VERSION "dbc-export 1 2026.26.6.5"

NS_ :

BS_:

BU_: ADSP APSB BB CMP DAS DPB EPAS3P EPASTP EPASTS GTW IDB OCS1P PTC RCM RCU TCU TCU2 UDS UI UIS VCLEFT VCSEAT2L VCSEAT2R

BO_ 1297 RCM_alertLog: 8 RCM
 SG_ RCM_alertID M : 0|10@1+ (1,0) [0|1023] "" Vector__XXX
 SG_ RCM_a073_eventFactoryMode m73 : 12|1@1+ (1,0) [0|1] "" Vector__XXX
 SG_ RCM_a073_eventDiagEnabled m73 : 13|1@1+ (1,0) [0|1] "" Vector__XXX
 SG_ RCM_a073_eventDriveOrientation m73 : 14|1@1+ (1,0) [0|1] "" Vector__XXX
 SG_ RCM_a073_comChassisCANPH4MIA m73 : 16|1@1+ (1,0) [0|1] "" Vector__XXX
 SG_ RCM_a073_comChassisCANPH4ChkSm m73 : 17|1@1+ (1,0) [0|1] "" Vector__XXX
 SG_ RCM_a073_comChassisCANPH4Cntr m73 : 18|1@1+ (1,0) [0|1] "" Vector__XXX
 SG_ RCM_a073_eventIDFsignal m73 : 25|1@1+ (1,0) [0|1] "" Vector__XXX
 SG_ RCM_a073_eventFrontLeftSeatbelt m73 : 26|1@1+ (1,0) [0|1] "" Vector__XXX
 SG_ RCM_a073_eventFrontRightSeatbelt m73 : 27|1@1+ (1,0) [0|1] "" Vector__XXX
 SG_ RCM_a073_eventVehicleSpeed m73 : 28|12@1+ (0.08,-40) [-40|287.6] "kph" Vector__XXX
 SG_ RCM_a073_eventSteeringAngle m73 : 45|14@0+ (0.1,-819.2) [-819.2|819.1] "deg" Vector__XXX
 SG_ RCM_a073_eventDriverBrakeApply m73 : 46|2@1+ (1,0) [0|2] "" Vector__XXX
 SG_ RCM_a073_eventAccelPedalPos m73 : 56|8@1+ (0.4,0) [0|101.6] "%" Vector__XXX
 SG_ RCM_a074_eventArmStatus m74 : 11|1@1+ (1,0) [0|1] "" Vector__XXX
 SG_ RCM_a074_eventFactoryMode m74 : 12|1@1+ (1,0) [0|1] "" Vector__XXX
 SG_ RCM_a074_eventDiagEnabled m74 : 13|1@1+ (1,0) [0|1] "" Vector__XXX
 SG_ RCM_a074_eventDriveOrientation m74 : 14|1@1+ (1,0) [0|1] "" Vector__XXX
 SG_ RCM_a074_comChassisCANPH5MIA m74 : 16|1@1+ (1,0) [0|1] "" Vector__XXX
 SG_ RCM_a074_comChassisCANPH5ChkSm m74 : 17|1@1+ (1,0) [0|1] "" Vector__XXX
 SG_ RCM_a074_comChassisCANPH5Cntr m74 : 18|1@1+ (1,0) [0|1] "" Vector__XXX
 SG_ RCM_a074_eventIDFsignal m74 : 25|1@1+ (1,0) [0|1] "" Vector__XXX
 SG_ RCM_a074_eventFrontLeftSeatbelt m74 : 26|1@1+ (1,0) [0|1] "" Vector__XXX
 SG_ RCM_a074_eventFrontRightSeatbelt m74 : 27|1@1+ (1,0) [0|1] "" Vector__XXX
 SG_ RCM_a074_eventVehicleSpeed m74 : 28|12@1+ (0.08,-40) [-40|287.6] "kph" Vector__XXX
 SG_ RCM_a074_eventSteeringAngle m74 : 45|14@0+ (0.1,-819.2) [-819.2|819.1] "deg" Vector__XXX
 SG_ RCM_a074_eventDriverBrakeApply m74 : 46|2@1+ (1,0) [0|2] "" Vector__XXX
 SG_ RCM_a074_eventAccelPedalPos m74 : 56|8@1+ (0.4,0) [0|101.6] "%" Vector__XXX
 SG_ RCM_a075_eventArmStatus m75 : 11|1@1+ (1,0) [0|1] "" Vector__XXX
 SG_ RCM_a075_eventFactoryMode m75 : 12|1@1+ (1,0) [0|1] "" Vector__XXX
 SG_ RCM_a075_eventDiagEnabled m75 : 13|1@1+ (1,0) [0|1] "" Vector__XXX
 SG_ RCM_a075_eventDriveOrientation m75 : 14|1@1+ (1,0) [0|1] "" Vector__XXX
 SG_ RCM_a075_comChassisCANPH6MIA m75 : 16|1@1+ (1,0) [0|1] "" Vector__XXX
 SG_ RCM_a075_comChassisCANPH6ChkSm m75 : 17|1@1+ (1,0) [0|1] "" Vector__XXX
 SG_ RCM_a075_comChassisCANPH6Cntr m75 : 18|1@1+ (1,0) [0|1] "" Vector__XXX
 SG_ RCM_a075_eventIDFsignal m75 : 25|1@1+ (1,0) [0|1] "" Vector__XXX
 SG_ RCM_a075_eventFrontLeftSeatbelt m75 : 26|1@1+ (1,0) [0|1] "" Vector__XXX
 SG_ RCM_a075_eventFrontRightSeatbelt m75 : 27|1@1+ (1,0) [0|1] "" Vector__XXX
 SG_ RCM_a075_eventVehicleSpeed m75 : 28|12@1+ (0.08,-40) [-40|287.6] "kph" Vector__XXX
 SG_ RCM_a075_eventSteeringAngle m75 : 45|14@0+ (0.1,-819.2) [-819.2|819.1] "deg" Vector__XXX
 SG_ RCM_a075_eventDriverBrakeApply m75 : 46|2@1+ (1,0) [0|2] "" Vector__XXX
 SG_ RCM_a075_eventAccelPedalPos m75 : 56|8@1+ (0.4,0) [0|101.6] "%" Vector__XXX
 SG_ RCM_a078_eventArmStatus m78 : 11|1@1+ (1,0) [0|1] "" Vector__XXX
 SG_ RCM_a078_eventFactoryMode m78 : 12|1@1+ (1,0) [0|1] "" Vector__XXX
 SG_ RCM_a078_eventDiagEnabled m78 : 13|1@1+ (1,0) [0|1] "" Vector__XXX
 SG_ RCM_a078_eventDriveOrientation m78 : 14|1@1+ (1,0) [0|1] "" Vector__XXX
 SG_ RCM_a078_comOCS1PMIA m78 : 16|1@1+ (1,0) [0|1] "" Vector__XXX
 SG_ RCM_a078_comOCS1PChkSm m78 : 17|1@1+ (1,0) [0|1] "" Vector__XXX
 SG_ RCM_a078_comOCS1PCntr m78 : 18|1@1+ (1,0) [0|1] "" Vector__XXX
 SG_ RCM_a078_eventIDFsignal m78 : 25|1@1+ (1,0) [0|1] "" Vector__XXX
 SG_ RCM_a078_eventFrontLeftSeatbelt m78 : 26|1@1+ (1,0) [0|1] "" Vector__XXX
 SG_ RCM_a078_eventFrontRightSeatbelt m78 : 27|1@1+ (1,0) [0|1] "" Vector__XXX
 SG_ RCM_a078_eventVehicleSpeed m78 : 28|12@1+ (0.08,-40) [-40|287.6] "kph" Vector__XXX
 SG_ RCM_a078_eventSteeringAngle m78 : 45|14@0+ (0.1,-819.2) [-819.2|819.1] "deg" Vector__XXX
 SG_ RCM_a078_eventDriverBrakeApply m78 : 46|2@1+ (1,0) [0|2] "" Vector__XXX
 SG_ RCM_a078_eventAccelPedalPos m78 : 56|8@1+ (0.4,0) [0|101.6] "%" Vector__XXX
 SG_ RCM_a079_eventArmStatus m79 : 11|1@1+ (1,0) [0|1] "" Vector__XXX
 SG_ RCM_a079_eventFactoryMode m79 : 12|1@1+ (1,0) [0|1] "" Vector__XXX
 SG_ RCM_a079_eventDiagEnabled m79 : 13|1@1+ (1,0) [0|1] "" Vector__XXX
 SG_ RCM_a079_eventDriveOrientation m79 : 14|1@1+ (1,0) [0|1] "" Vector__XXX
 SG_ RCM_a079_comOCS1DMIA m79 : 16|1@1+ (1,0) [0|1] "" Vector__XXX
 SG_ RCM_a079_comOCS1DChkSm m79 : 17|1@1+ (1,0) [0|1] "" Vector__XXX
 SG_ RCM_a079_comOCS1DCntr m79 : 18|1@1+ (1,0) [0|1] "" Vector__XXX
 SG_ RCM_a079_eventIDFsignal m79 : 25|1@1+ (1,0) [0|1] "" Vector__XXX
 SG_ RCM_a079_eventFrontLeftSeatbelt m79 : 26|1@1+ (1,0) [0|1] "" Vector__XXX
 SG_ RCM_a079_eventFrontRightSeatbelt m79 : 27|1@1+ (1,0) [0|1] "" Vector__XXX
 SG_ RCM_a079_eventVehicleSpeed m79 : 28|12@1+ (0.08,-40) [-40|287.6] "kph" Vector__XXX
 SG_ RCM_a079_eventSteeringAngle m79 : 45|14@0+ (0.1,-819.2) [-819.2|819.1] "deg" Vector__XXX
 SG_ RCM_a079_eventDriverBrakeApply m79 : 46|2@1+ (1,0) [0|2] "" Vector__XXX
 SG_ RCM_a079_eventAccelPedalPos m79 : 56|8@1+ (0.4,0) [0|101.6] "%" Vector__XXX
 SG_ RCM_a080_eventArmStatus m80 : 11|1@1+ (1,0) [0|1] "" Vector__XXX
 SG_ RCM_a080_eventFactoryMode m80 : 12|1@1+ (1,0) [0|1] "" Vector__XXX
 SG_ RCM_a080_eventDiagEnabled m80 : 13|1@1+ (1,0) [0|1] "" Vector__XXX
 SG_ RCM_a080_eventDriveOrientation m80 : 14|1@1+ (1,0) [0|1] "" Vector__XXX
 SG_ RCM_a080_comGTWACSMIA m80 : 16|1@1+ (1,0) [0|1] "" Vector__XXX
 SG_ RCM_a080_comGTWACSChkSm m80 : 17|1@1+ (1,0) [0|1] "" Vector__XXX
 SG_ RCM_a080_comGTWACSCntr m80 : 18|1@1+ (1,0) [0|1] "" Vector__XXX
 SG_ RCM_a080_eventIDFsignal m80 : 25|1@1+ (1,0) [0|1] "" Vector__XXX
 SG_ RCM_a080_eventFrontLeftSeatbelt m80 : 26|1@1+ (1,0) [0|1] "" Vector__XXX
 SG_ RCM_a080_eventFrontRightSeatbelt m80 : 27|1@1+ (1,0) [0|1] "" Vector__XXX
 SG_ RCM_a080_eventVehicleSpeed m80 : 28|12@1+ (0.08,-40) [-40|287.6] "kph" Vector__XXX
 SG_ RCM_a080_eventSteeringAngle m80 : 45|14@0+ (0.1,-819.2) [-819.2|819.1] "deg" Vector__XXX
 SG_ RCM_a080_eventDriverBrakeApply m80 : 46|2@1+ (1,0) [0|2] "" Vector__XXX
 SG_ RCM_a080_eventAccelPedalPos m80 : 56|8@1+ (0.4,0) [0|101.6] "%" Vector__XXX
 SG_ RCM_a083_eventArmStatus m83 : 11|1@1+ (1,0) [0|1] "" Vector__XXX
 SG_ RCM_a083_eventFactoryMode m83 : 12|1@1+ (1,0) [0|1] "" Vector__XXX
 SG_ RCM_a083_eventDiagEnabled m83 : 13|1@1+ (1,0) [0|1] "" Vector__XXX
 SG_ RCM_a083_eventDriveOrientation m83 : 14|1@1+ (1,0) [0|1] "" Vector__XXX
 SG_ RCM_a083_comGTWCarStateMIA m83 : 16|1@1+ (1,0) [0|1] "" Vector__XXX
 SG_ RCM_a083_eventIDFsignal m83 : 25|1@1+ (1,0) [0|1] "" Vector__XXX
 SG_ RCM_a083_eventFrontLeftSeatbelt m83 : 26|1@1+ (1,0) [0|1] "" Vector__XXX
 SG_ RCM_a083_eventFrontRightSeatbelt m83 : 27|1@1+ (1,0) [0|1] "" Vector__XXX
 SG_ RCM_a083_eventVehicleSpeed m83 : 28|12@1+ (0.08,-40) [-40|287.6] "kph" Vector__XXX
 SG_ RCM_a083_eventSteeringAngle m83 : 45|14@0+ (0.1,-819.2) [-819.2|819.1] "deg" Vector__XXX
 SG_ RCM_a083_eventDriverBrakeApply m83 : 46|2@1+ (1,0) [0|2] "" Vector__XXX
 SG_ RCM_a083_eventAccelPedalPos m83 : 56|8@1+ (0.4,0) [0|101.6] "%" Vector__XXX
 SG_ RCM_a087_eventArmStatus m87 : 11|1@1+ (1,0) [0|1] "" Vector__XXX
 SG_ RCM_a087_eventFactoryMode m87 : 12|1@1+ (1,0) [0|1] "" Vector__XXX
 SG_ RCM_a087_eventDiagEnabled m87 : 13|1@1+ (1,0) [0|1] "" Vector__XXX
 SG_ RCM_a087_eventDriveOrientation m87 : 14|1@1+ (1,0) [0|1] "" Vector__XXX
 SG_ RCM_a087_comChassisCANSilent m87 : 16|1@1+ (1,0) [0|1] "" Vector__XXX
 SG_ RCM_a087_comPARTYCANSilent m87 : 17|1@1+ (1,0) [0|1] "" Vector__XXX
 SG_ RCM_a087_comUnusedCANSilent m87 : 18|1@1+ (1,0) [0|1] "" Vector__XXX
 SG_ RCM_a087_eventIDFsignal m87 : 25|1@1+ (1,0) [0|1] "" Vector__XXX
 SG_ RCM_a087_eventFrontLeftSeatbelt m87 : 26|1@1+ (1,0) [0|1] "" Vector__XXX
 SG_ RCM_a087_eventFrontRightSeatbelt m87 : 27|1@1+ (1,0) [0|1] "" Vector__XXX
 SG_ RCM_a087_eventVehicleSpeed m87 : 28|12@1+ (0.08,-40) [-40|287.6] "kph" Vector__XXX
 SG_ RCM_a087_eventSteeringAngle m87 : 45|14@0+ (0.1,-819.2) [-819.2|819.1] "deg" Vector__XXX
 SG_ RCM_a087_eventDriverBrakeApply m87 : 46|2@1+ (1,0) [0|2] "" Vector__XXX
 SG_ RCM_a087_eventAccelPedalPos m87 : 56|8@1+ (0.4,0) [0|101.6] "%" Vector__XXX
 SG_ RCM_a088_eventArmStatus m88 : 11|1@1+ (1,0) [0|1] "" Vector__XXX
 SG_ RCM_a088_eventFactoryMode m88 : 12|1@1+ (1,0) [0|1] "" Vector__XXX
 SG_ RCM_a088_eventDiagEnabled m88 : 13|1@1+ (1,0) [0|1] "" Vector__XXX
 SG_ RCM_a088_eventDriveOrientation m88 : 14|1@1+ (1,0) [0|1] "" Vector__XXX
 SG_ RCM_a088_comChassisCANPH2MIA m88 : 16|1@1+ (1,0) [0|1] "" Vector__XXX
 SG_ RCM_a088_comChassisCANPH2ChkSm m88 : 17|1@1+ (1,0) [0|1] "" Vector__XXX
 SG_ RCM_a088_comChassisCANPH2Cntr m88 : 18|1@1+ (1,0) [0|1] "" Vector__XXX
 SG_ RCM_a088_eventIDFsignal m88 : 25|1@1+ (1,0) [0|1] "" Vector__XXX
 SG_ RCM_a088_eventFrontLeftSeatbelt m88 : 26|1@1+ (1,0) [0|1] "" Vector__XXX
 SG_ RCM_a088_eventFrontRightSeatbelt m88 : 27|1@1+ (1,0) [0|1] "" Vector__XXX
 SG_ RCM_a088_eventVehicleSpeed m88 : 28|12@1+ (0.08,-40) [-40|287.6] "kph" Vector__XXX
 SG_ RCM_a088_eventSteeringAngle m88 : 45|14@0+ (0.1,-819.2) [-819.2|819.1] "deg" Vector__XXX
 SG_ RCM_a088_eventDriverBrakeApply m88 : 46|2@1+ (1,0) [0|2] "" Vector__XXX
 SG_ RCM_a088_eventAccelPedalPos m88 : 56|8@1+ (0.4,0) [0|101.6] "%" Vector__XXX
 SG_ RCM_a089_eventArmStatus m89 : 11|1@1+ (1,0) [0|1] "" Vector__XXX
 SG_ RCM_a089_eventFactoryMode m89 : 12|1@1+ (1,0) [0|1] "" Vector__XXX
 SG_ RCM_a089_eventDiagEnabled m89 : 13|1@1+ (1,0) [0|1] "" Vector__XXX
 SG_ RCM_a089_eventDriveOrientation m89 : 14|1@1+ (1,0) [0|1] "" Vector__XXX
 SG_ RCM_a089_comChassisCANPH3MIA m89 : 16|1@1+ (1,0) [0|1] "" Vector__XXX
 SG_ RCM_a089_comChassisCANPH3ChkSm m89 : 17|1@1+ (1,0) [0|1] "" Vector__XXX
 SG_ RCM_a089_comChassisCANPH3Cntr m89 : 18|1@1+ (1,0) [0|1] "" Vector__XXX
 SG_ RCM_a089_eventIDFsignal m89 : 25|1@1+ (1,0) [0|1] "" Vector__XXX
 SG_ RCM_a089_eventFrontLeftSeatbelt m89 : 26|1@1+ (1,0) [0|1] "" Vector__XXX
 SG_ RCM_a089_eventFrontRightSeatbelt m89 : 27|1@1+ (1,0) [0|1] "" Vector__XXX
 SG_ RCM_a089_eventVehicleSpeed m89 : 28|12@1+ (0.08,-40) [-40|287.6] "kph" Vector__XXX
 SG_ RCM_a089_eventSteeringAngle m89 : 45|14@0+ (0.1,-819.2) [-819.2|819.1] "deg" Vector__XXX
 SG_ RCM_a089_eventDriverBrakeApply m89 : 46|2@1+ (1,0) [0|2] "" Vector__XXX
 SG_ RCM_a089_eventAccelPedalPos m89 : 56|8@1+ (0.4,0) [0|101.6] "%" Vector__XXX
 SG_ RCM_a090_eventArmStatus m90 : 11|1@1+ (1,0) [0|1] "" Vector__XXX
 SG_ RCM_a090_eventFactoryMode m90 : 12|1@1+ (1,0) [0|1] "" Vector__XXX
 SG_ RCM_a090_eventDiagEnabled m90 : 13|1@1+ (1,0) [0|1] "" Vector__XXX
 SG_ RCM_a090_eventDriveOrientation m90 : 14|1@1+ (1,0) [0|1] "" Vector__XXX
 SG_ RCM_a090_comPartyCANBusOff m90 : 16|1@1+ (1,0) [0|1] "" Vector__XXX
 SG_ RCM_a090_eventIDFsignal m90 : 25|1@1+ (1,0) [0|1] "" Vector__XXX
 SG_ RCM_a090_eventFrontLeftSeatbelt m90 : 26|1@1+ (1,0) [0|1] "" Vector__XXX
 SG_ RCM_a090_eventFrontRightSeatbelt m90 : 27|1@1+ (1,0) [0|1] "" Vector__XXX
 SG_ RCM_a090_eventVehicleSpeed m90 : 28|12@1+ (0.08,-40) [-40|287.6] "kph" Vector__XXX
 SG_ RCM_a090_eventSteeringAngle m90 : 45|14@0+ (0.1,-819.2) [-819.2|819.1] "deg" Vector__XXX
 SG_ RCM_a090_eventDriverBrakeApply m90 : 46|2@1+ (1,0) [0|2] "" Vector__XXX
 SG_ RCM_a090_eventAccelPedalPos m90 : 56|8@1+ (0.4,0) [0|101.6] "%" Vector__XXX
 SG_ RCM_a092_eventArmStatus m92 : 11|1@1+ (1,0) [0|1] "" Vector__XXX
 SG_ RCM_a092_eventFactoryMode m92 : 12|1@1+ (1,0) [0|1] "" Vector__XXX
 SG_ RCM_a092_eventDiagEnabled m92 : 13|1@1+ (1,0) [0|1] "" Vector__XXX
 SG_ RCM_a092_eventDriveOrientation m92 : 14|1@1+ (1,0) [0|1] "" Vector__XXX
 SG_ RCM_a092_comDASSafetyFrontMIA m92 : 16|1@1+ (1,0) [0|1] "" Vector__XXX
 SG_ RCM_a092_comDASSafetyFrontChkSm m92 : 17|1@1+ (1,0) [0|1] "" Vector__XXX
 SG_ RCM_a092_comDASSafetyFrontCntr m92 : 18|1@1+ (1,0) [0|1] "" Vector__XXX
 SG_ RCM_a092_eventIDFsignal m92 : 25|1@1+ (1,0) [0|1] "" Vector__XXX
 SG_ RCM_a092_eventFrontLeftSeatbelt m92 : 26|1@1+ (1,0) [0|1] "" Vector__XXX
 SG_ RCM_a092_eventFrontRightSeatbelt m92 : 27|1@1+ (1,0) [0|1] "" Vector__XXX
 SG_ RCM_a092_eventVehicleSpeed m92 : 28|12@1+ (0.08,-40) [-40|287.6] "kph" Vector__XXX
 SG_ RCM_a092_eventSteeringAngle m92 : 45|14@0+ (0.1,-819.2) [-819.2|819.1] "deg" Vector__XXX
 SG_ RCM_a092_eventDriverBrakeApply m92 : 46|2@1+ (1,0) [0|2] "" Vector__XXX
 SG_ RCM_a092_eventAccelPedalPos m92 : 56|8@1+ (0.4,0) [0|101.6] "%" Vector__XXX
 SG_ RCM_a093_eventArmStatus m93 : 11|1@1+ (1,0) [0|1] "" Vector__XXX
 SG_ RCM_a093_eventFactoryMode m93 : 12|1@1+ (1,0) [0|1] "" Vector__XXX
 SG_ RCM_a093_eventDiagEnabled m93 : 13|1@1+ (1,0) [0|1] "" Vector__XXX
 SG_ RCM_a093_eventDriveOrientation m93 : 14|1@1+ (1,0) [0|1] "" Vector__XXX
 SG_ RCM_a093_comVCLEFTStatusMIA m93 : 16|1@1+ (1,0) [0|1] "" Vector__XXX
 SG_ RCM_a093_comVCLEFTStatusChkSm m93 : 17|1@1+ (1,0) [0|1] "" Vector__XXX
 SG_ RCM_a093_comVCLEFTStatusCntr m93 : 18|1@1+ (1,0) [0|1] "" Vector__XXX
 SG_ RCM_a093_bucklSwVCFrontLeftFault m93 : 19|1@1+ (1,0) [0|1] "" Vector__XXX
 SG_ RCM_a093_bucklSwVCRearLeftFault m93 : 20|1@1+ (1,0) [0|1] "" Vector__XXX
 SG_ RCM_a093_eventIDFsignal m93 : 25|1@1+ (1,0) [0|1] "" Vector__XXX
 SG_ RCM_a093_eventFrontLeftSeatbelt m93 : 26|1@1+ (1,0) [0|1] "" Vector__XXX
 SG_ RCM_a093_eventFrontRightSeatbelt m93 : 27|1@1+ (1,0) [0|1] "" Vector__XXX
 SG_ RCM_a093_eventVehicleSpeed m93 : 28|12@1+ (0.08,-40) [-40|287.6] "kph" Vector__XXX
 SG_ RCM_a093_eventSteeringAngle m93 : 45|14@0+ (0.1,-819.2) [-819.2|819.1] "deg" Vector__XXX
 SG_ RCM_a093_eventDriverBrakeApply m93 : 46|2@1+ (1,0) [0|2] "" Vector__XXX
 SG_ RCM_a093_eventAccelPedalPos m93 : 56|8@1+ (0.4,0) [0|101.6] "%" Vector__XXX
 SG_ RCM_a094_eventArmStatus m94 : 11|1@1+ (1,0) [0|1] "" Vector__XXX
 SG_ RCM_a094_eventFactoryMode m94 : 12|1@1+ (1,0) [0|1] "" Vector__XXX
 SG_ RCM_a094_eventDiagEnabled m94 : 13|1@1+ (1,0) [0|1] "" Vector__XXX
 SG_ RCM_a094_eventDriveOrientation m94 : 14|1@1+ (1,0) [0|1] "" Vector__XXX
 SG_ RCM_a094_comVCRIGHTStatusMIA m94 : 16|1@1+ (1,0) [0|1] "" Vector__XXX
 SG_ RCM_a094_comVCRIGHTStatusChkSm m94 : 17|1@1+ (1,0) [0|1] "" Vector__XXX
 SG_ RCM_a094_comVCRIGHTStatusCntr m94 : 18|1@1+ (1,0) [0|1] "" Vector__XXX
 SG_ RCM_a094_bucklSwVCFrontRghtFault m94 : 19|1@1+ (1,0) [0|1] "" Vector__XXX
 SG_ RCM_a094_bucklSwVCRearRghtFault m94 : 20|1@1+ (1,0) [0|1] "" Vector__XXX
 SG_ RCM_a094_bucklSwVCRearCnterFault m94 : 21|1@1+ (1,0) [0|1] "" Vector__XXX
 SG_ RCM_a094_eventIDFsignal m94 : 25|1@1+ (1,0) [0|1] "" Vector__XXX
 SG_ RCM_a094_eventFrontLeftSeatbelt m94 : 26|1@1+ (1,0) [0|1] "" Vector__XXX
 SG_ RCM_a094_eventFrontRightSeatbelt m94 : 27|1@1+ (1,0) [0|1] "" Vector__XXX
 SG_ RCM_a094_eventVehicleSpeed m94 : 28|12@1+ (0.08,-40) [-40|287.6] "kph" Vector__XXX
 SG_ RCM_a094_eventSteeringAngle m94 : 45|14@0+ (0.1,-819.2) [-819.2|819.1] "deg" Vector__XXX
 SG_ RCM_a094_eventDriverBrakeApply m94 : 46|2@1+ (1,0) [0|2] "" Vector__XXX
 SG_ RCM_a094_eventAccelPedalPos m94 : 56|8@1+ (0.4,0) [0|101.6] "%" Vector__XXX
 SG_ RCM_a101_eventArmStatus m101 : 11|1@1+ (1,0) [0|1] "" Vector__XXX
 SG_ RCM_a101_eventFactoryMode m101 : 12|1@1+ (1,0) [0|1] "" Vector__XXX
 SG_ RCM_a101_eventDiagEnabled m101 : 13|1@1+ (1,0) [0|1] "" Vector__XXX
 SG_ RCM_a101_eventDriveOrientation m101 : 14|1@1+ (1,0) [0|1] "" Vector__XXX
 SG_ RCM_a101_idfMisuseMonitoringErr m101 : 16|1@1+ (1,0) [0|1] "" Vector__XXX
 SG_ RCM_a101_idfEnviMonitoringError m101 : 17|1@1+ (1,0) [0|1] "" Vector__XXX
 SG_ RCM_a101_idfEnviMonitoringEvent m101 : 18|1@1+ (1,0) [0|1] "" Vector__XXX
 SG_ RCM_a101_eventIDFsignal m101 : 25|1@1+ (1,0) [0|1] "" Vector__XXX
 SG_ RCM_a101_eventFrontLeftSeatbelt m101 : 26|1@1+ (1,0) [0|1] "" Vector__XXX
 SG_ RCM_a101_eventFrontRightSeatbelt m101 : 27|1@1+ (1,0) [0|1] "" Vector__XXX
 SG_ RCM_a101_eventVehicleSpeed m101 : 28|12@1+ (0.08,-40) [-40|287.6] "kph" Vector__XXX
 SG_ RCM_a101_eventSteeringAngle m101 : 45|14@0+ (0.1,-819.2) [-819.2|819.1] "deg" Vector__XXX
 SG_ RCM_a101_eventDriverBrakeApply m101 : 46|2@1+ (1,0) [0|2] "" Vector__XXX
 SG_ RCM_a101_eventAccelPedalPos m101 : 56|8@1+ (0.4,0) [0|101.6] "%" Vector__XXX
 SG_ RCM_a102_eventArmStatus m102 : 11|1@1+ (1,0) [0|1] "" Vector__XXX
 SG_ RCM_a102_eventFactoryMode m102 : 12|1@1+ (1,0) [0|1] "" Vector__XXX
 SG_ RCM_a102_eventDiagEnabled m102 : 13|1@1+ (1,0) [0|1] "" Vector__XXX
 SG_ RCM_a102_eventDriveOrientation m102 : 14|1@1+ (1,0) [0|1] "" Vector__XXX
 SG_ RCM_a102_imuYawR8OffCompPosLife m102 : 16|1@1+ (1,0) [0|1] "" Vector__XXX
 SG_ RCM_a102_imuYawR8OffCompNegLife m102 : 17|1@1+ (1,0) [0|1] "" Vector__XXX
 SG_ RCM_a102_imuYawR8OffCompPosFLDC m102 : 18|1@1+ (1,0) [0|1] "" Vector__XXX
 SG_ RCM_a102_imuYawR8OffCompNegFLDC m102 : 19|1@1+ (1,0) [0|1] "" Vector__XXX
 SG_ RCM_a102_imuYawR8OffCompPosSLDC m102 : 20|1@1+ (1,0) [0|1] "" Vector__XXX
 SG_ RCM_a102_imuYawR8OffCompNegSLDC m102 : 21|1@1+ (1,0) [0|1] "" Vector__XXX
 SG_ RCM_a102_eventIDFsignal m102 : 25|1@1+ (1,0) [0|1] "" Vector__XXX
 SG_ RCM_a102_eventFrontLeftSeatbelt m102 : 26|1@1+ (1,0) [0|1] "" Vector__XXX
 SG_ RCM_a102_eventFrontRightSeatbelt m102 : 27|1@1+ (1,0) [0|1] "" Vector__XXX
 SG_ RCM_a102_eventVehicleSpeed m102 : 28|12@1+ (0.08,-40) [-40|287.6] "kph" Vector__XXX
 SG_ RCM_a102_eventSteeringAngle m102 : 45|14@0+ (0.1,-819.2) [-819.2|819.1] "deg" Vector__XXX
 SG_ RCM_a102_eventDriverBrakeApply m102 : 46|2@1+ (1,0) [0|2] "" Vector__XXX
 SG_ RCM_a102_eventAccelPedalPos m102 : 56|8@1+ (0.4,0) [0|101.6] "%" Vector__XXX
 SG_ RCM_a103_eventArmStatus m103 : 11|1@1+ (1,0) [0|1] "" Vector__XXX
 SG_ RCM_a103_eventFactoryMode m103 : 12|1@1+ (1,0) [0|1] "" Vector__XXX
 SG_ RCM_a103_eventDiagEnabled m103 : 13|1@1+ (1,0) [0|1] "" Vector__XXX
 SG_ RCM_a103_eventDriveOrientation m103 : 14|1@1+ (1,0) [0|1] "" Vector__XXX
 SG_ RCM_a103_imuPtchR8OffCompPosLife m103 : 16|1@1+ (1,0) [0|1] "" Vector__XXX
 SG_ RCM_a103_imuPtchR8OffCompNegLife m103 : 17|1@1+ (1,0) [0|1] "" Vector__XXX
 SG_ RCM_a103_imuPtchR8OffCompPosFLDC m103 : 18|1@1+ (1,0) [0|1] "" Vector__XXX
 SG_ RCM_a103_imuPtchR8OffCompNegFLDC m103 : 19|1@1+ (1,0) [0|1] "" Vector__XXX
 SG_ RCM_a103_imuPtchR8OffCompPosSLDC m103 : 20|1@1+ (1,0) [0|1] "" Vector__XXX
 SG_ RCM_a103_imuPtchR8OffCompNegSLDC m103 : 21|1@1+ (1,0) [0|1] "" Vector__XXX
 SG_ RCM_a103_eventIDFsignal m103 : 25|1@1+ (1,0) [0|1] "" Vector__XXX
 SG_ RCM_a103_eventFrontLeftSeatbelt m103 : 26|1@1+ (1,0) [0|1] "" Vector__XXX
 SG_ RCM_a103_eventFrontRightSeatbelt m103 : 27|1@1+ (1,0) [0|1] "" Vector__XXX
 SG_ RCM_a103_eventVehicleSpeed m103 : 28|12@1+ (0.08,-40) [-40|287.6] "kph" Vector__XXX
 SG_ RCM_a103_eventSteeringAngle m103 : 45|14@0+ (0.1,-819.2) [-819.2|819.1] "deg" Vector__XXX
 SG_ RCM_a103_eventDriverBrakeApply m103 : 46|2@1+ (1,0) [0|2] "" Vector__XXX
 SG_ RCM_a103_eventAccelPedalPos m103 : 56|8@1+ (0.4,0) [0|101.6] "%" Vector__XXX
 SG_ RCM_a104_eventArmStatus m104 : 11|1@1+ (1,0) [0|1] "" Vector__XXX
 SG_ RCM_a104_eventFactoryMode m104 : 12|1@1+ (1,0) [0|1] "" Vector__XXX
 SG_ RCM_a104_eventDiagEnabled m104 : 13|1@1+ (1,0) [0|1] "" Vector__XXX
 SG_ RCM_a104_eventDriveOrientation m104 : 14|1@1+ (1,0) [0|1] "" Vector__XXX
 SG_ RCM_a104_imuRollR8OffCompPosLife m104 : 16|1@1+ (1,0) [0|1] "" Vector__XXX
 SG_ RCM_a104_imuRollR8OffCompNegLife m104 : 17|1@1+ (1,0) [0|1] "" Vector__XXX
 SG_ RCM_a104_imuRollR8OffCompPosFLDC m104 : 18|1@1+ (1,0) [0|1] "" Vector__XXX
 SG_ RCM_a104_imuRollR8OffCompNegFLDC m104 : 19|1@1+ (1,0) [0|1] "" Vector__XXX
 SG_ RCM_a104_imuRollR8OffCompPosSLDC m104 : 20|1@1+ (1,0) [0|1] "" Vector__XXX
 SG_ RCM_a104_imuRollR8OffCompNegSLDC m104 : 21|1@1+ (1,0) [0|1] "" Vector__XXX
 SG_ RCM_a104_eventIDFsignal m104 : 25|1@1+ (1,0) [0|1] "" Vector__XXX
 SG_ RCM_a104_eventFrontLeftSeatbelt m104 : 26|1@1+ (1,0) [0|1] "" Vector__XXX
 SG_ RCM_a104_eventFrontRightSeatbelt m104 : 27|1@1+ (1,0) [0|1] "" Vector__XXX
 SG_ RCM_a104_eventVehicleSpeed m104 : 28|12@1+ (0.08,-40) [-40|287.6] "kph" Vector__XXX
 SG_ RCM_a104_eventSteeringAngle m104 : 45|14@0+ (0.1,-819.2) [-819.2|819.1] "deg" Vector__XXX
 SG_ RCM_a104_eventDriverBrakeApply m104 : 46|2@1+ (1,0) [0|2] "" Vector__XXX
 SG_ RCM_a104_eventAccelPedalPos m104 : 56|8@1+ (0.4,0) [0|101.6] "%" Vector__XXX
 SG_ RCM_a105_eventArmStatus m105 : 11|1@1+ (1,0) [0|1] "" Vector__XXX
 SG_ RCM_a105_eventFactoryMode m105 : 12|1@1+ (1,0) [0|1] "" Vector__XXX
 SG_ RCM_a105_eventDiagEnabled m105 : 13|1@1+ (1,0) [0|1] "" Vector__XXX
 SG_ RCM_a105_eventDriveOrientation m105 : 14|1@1+ (1,0) [0|1] "" Vector__XXX
 SG_ RCM_a105_imuLongAOffCompPosLife m105 : 16|1@1+ (1,0) [0|1] "" Vector__XXX
 SG_ RCM_a105_imuLongAOffCompNegLife m105 : 17|1@1+ (1,0) [0|1] "" Vector__XXX
 SG_ RCM_a105_imuLongAOffCompPosFLDC m105 : 18|1@1+ (1,0) [0|1] "" Vector__XXX
 SG_ RCM_a105_imuLongAOffCompNegFLDC m105 : 19|1@1+ (1,0) [0|1] "" Vector__XXX
 SG_ RCM_a105_imuLongAOffCompPosSLDC m105 : 20|1@1+ (1,0) [0|1] "" Vector__XXX
 SG_ RCM_a105_imuLongAOffCompNegSLDC m105 : 21|1@1+ (1,0) [0|1] "" Vector__XXX
 SG_ RCM_a105_eventIDFsignal m105 : 25|1@1+ (1,0) [0|1] "" Vector__XXX
 SG_ RCM_a105_eventFrontLeftSeatbelt m105 : 26|1@1+ (1,0) [0|1] "" Vector__XXX
 SG_ RCM_a105_eventFrontRightSeatbelt m105 : 27|1@1+ (1,0) [0|1] "" Vector__XXX
 SG_ RCM_a105_eventVehicleSpeed m105 : 28|12@1+ (0.08,-40) [-40|287.6] "kph" Vector__XXX
 SG_ RCM_a105_eventSteeringAngle m105 : 45|14@0+ (0.1,-819.2) [-819.2|819.1] "deg" Vector__XXX
 SG_ RCM_a105_eventDriverBrakeApply m105 : 46|2@1+ (1,0) [0|2] "" Vector__XXX
 SG_ RCM_a105_eventAccelPedalPos m105 : 56|8@1+ (0.4,0) [0|101.6] "%" Vector__XXX
 SG_ RCM_a106_eventArmStatus m106 : 11|1@1+ (1,0) [0|1] "" Vector__XXX
 SG_ RCM_a106_eventFactoryMode m106 : 12|1@1+ (1,0) [0|1] "" Vector__XXX
 SG_ RCM_a106_eventDiagEnabled m106 : 13|1@1+ (1,0) [0|1] "" Vector__XXX
 SG_ RCM_a106_eventDriveOrientation m106 : 14|1@1+ (1,0) [0|1] "" Vector__XXX
 SG_ RCM_a106_imuLatAcOffCompPosLife m106 : 16|1@1+ (1,0) [0|1] "" Vector__XXX
 SG_ RCM_a106_imuLatAcOffCompNegLife m106 : 17|1@1+ (1,0) [0|1] "" Vector__XXX
 SG_ RCM_a106_imuLatAcOffCompPosFLDC m106 : 18|1@1+ (1,0) [0|1] "" Vector__XXX
 SG_ RCM_a106_imuLatAcOffCompNegFLDC m106 : 19|1@1+ (1,0) [0|1] "" Vector__XXX
 SG_ RCM_a106_imuLatAcOffCompPosSLDC m106 : 20|1@1+ (1,0) [0|1] "" Vector__XXX
 SG_ RCM_a106_imuLatAcOffCompNegSLDC m106 : 21|1@1+ (1,0) [0|1] "" Vector__XXX
 SG_ RCM_a106_eventIDFsignal m106 : 25|1@1+ (1,0) [0|1] "" Vector__XXX
 SG_ RCM_a106_eventFrontLeftSeatbelt m106 : 26|1@1+ (1,0) [0|1] "" Vector__XXX
 SG_ RCM_a106_eventFrontRightSeatbelt m106 : 27|1@1+ (1,0) [0|1] "" Vector__XXX
 SG_ RCM_a106_eventVehicleSpeed m106 : 28|12@1+ (0.08,-40) [-40|287.6] "kph" Vector__XXX
 SG_ RCM_a106_eventSteeringAngle m106 : 45|14@0+ (0.1,-819.2) [-819.2|819.1] "deg" Vector__XXX
 SG_ RCM_a106_eventDriverBrakeApply m106 : 46|2@1+ (1,0) [0|2] "" Vector__XXX
 SG_ RCM_a106_eventAccelPedalPos m106 : 56|8@1+ (0.4,0) [0|101.6] "%" Vector__XXX
 SG_ RCM_a107_eventArmStatus m107 : 11|1@1+ (1,0) [0|1] "" Vector__XXX
 SG_ RCM_a107_eventFactoryMode m107 : 12|1@1+ (1,0) [0|1] "" Vector__XXX
 SG_ RCM_a107_eventDiagEnabled m107 : 13|1@1+ (1,0) [0|1] "" Vector__XXX
 SG_ RCM_a107_eventDriveOrientation m107 : 14|1@1+ (1,0) [0|1] "" Vector__XXX
 SG_ RCM_a107_imuVertAOffCompPosLife m107 : 16|1@1+ (1,0) [0|1] "" Vector__XXX
 SG_ RCM_a107_imuVertAOffCompNegLife m107 : 17|1@1+ (1,0) [0|1] "" Vector__XXX
 SG_ RCM_a107_imuVertAOffCompPosFLDC m107 : 18|1@1+ (1,0) [0|1] "" Vector__XXX
 SG_ RCM_a107_imuVertAOffCompNegFLDC m107 : 19|1@1+ (1,0) [0|1] "" Vector__XXX
 SG_ RCM_a107_imuVertAOffCompPosSLDC m107 : 20|1@1+ (1,0) [0|1] "" Vector__XXX
 SG_ RCM_a107_imuVertAOffCompNegSLDC m107 : 21|1@1+ (1,0) [0|1] "" Vector__XXX
 SG_ RCM_a107_eventIDFsignal m107 : 25|1@1+ (1,0) [0|1] "" Vector__XXX
 SG_ RCM_a107_eventFrontLeftSeatbelt m107 : 26|1@1+ (1,0) [0|1] "" Vector__XXX
 SG_ RCM_a107_eventFrontRightSeatbelt m107 : 27|1@1+ (1,0) [0|1] "" Vector__XXX
 SG_ RCM_a107_eventVehicleSpeed m107 : 28|12@1+ (0.08,-40) [-40|287.6] "kph" Vector__XXX
 SG_ RCM_a107_eventSteeringAngle m107 : 45|14@0+ (0.1,-819.2) [-819.2|819.1] "deg" Vector__XXX
 SG_ RCM_a107_eventDriverBrakeApply m107 : 46|2@1+ (1,0) [0|2] "" Vector__XXX
 SG_ RCM_a107_eventAccelPedalPos m107 : 56|8@1+ (0.4,0) [0|101.6] "%" Vector__XXX
 SG_ RCM_a108_eventArmStatus m108 : 11|1@1+ (1,0) [0|1] "" Vector__XXX
 SG_ RCM_a108_eventFactoryMode m108 : 12|1@1+ (1,0) [0|1] "" Vector__XXX
 SG_ RCM_a108_eventDiagEnabled m108 : 13|1@1+ (1,0) [0|1] "" Vector__XXX
 SG_ RCM_a108_eventDriveOrientation m108 : 14|1@1+ (1,0) [0|1] "" Vector__XXX
 SG_ RCM_a108_crashAlgoWakeupSig m108 : 16|1@1+ (1,0) [0|1] "" Vector__XXX
 SG_ RCM_a108_eventIDFsignal m108 : 25|1@1+ (1,0) [0|1] "" Vector__XXX
 SG_ RCM_a108_eventFrontLeftSeatbelt m108 : 26|1@1+ (1,0) [0|1] "" Vector__XXX
 SG_ RCM_a108_eventFrontRightSeatbelt m108 : 27|1@1+ (1,0) [0|1] "" Vector__XXX
 SG_ RCM_a108_eventVehicleSpeed m108 : 28|12@1+ (0.08,-40) [-40|287.6] "kph" Vector__XXX
 SG_ RCM_a108_eventSteeringAngle m108 : 45|14@0+ (0.1,-819.2) [-819.2|819.1] "deg" Vector__XXX
 SG_ RCM_a108_eventDriverBrakeApply m108 : 46|2@1+ (1,0) [0|2] "" Vector__XXX
 SG_ RCM_a108_eventAccelPedalPos m108 : 56|8@1+ (0.4,0) [0|101.6] "%" Vector__XXX
 SG_ RCM_a109_eventArmStatus m109 : 11|1@1+ (1,0) [0|1] "" Vector__XXX
 SG_ RCM_a109_eventFactoryMode m109 : 12|1@1+ (1,0) [0|1] "" Vector__XXX
 SG_ RCM_a109_eventDiagEnabled m109 : 13|1@1+ (1,0) [0|1] "" Vector__XXX
 SG_ RCM_a109_eventDriveOrientation m109 : 14|1@1+ (1,0) [0|1] "" Vector__XXX
 SG_ RCM_a109_immunityThrsholdCrossed m109 : 16|1@1+ (1,0) [0|1] "" Vector__XXX
 SG_ RCM_a109_eventIDFsignal m109 : 25|1@1+ (1,0) [0|1] "" Vector__XXX
 SG_ RCM_a109_eventFrontLeftSeatbelt m109 : 26|1@1+ (1,0) [0|1] "" Vector__XXX
 SG_ RCM_a109_eventFrontRightSeatbelt m109 : 27|1@1+ (1,0) [0|1] "" Vector__XXX
 SG_ RCM_a109_eventVehicleSpeed m109 : 28|12@1+ (0.08,-40) [-40|287.6] "kph" Vector__XXX
 SG_ RCM_a109_eventSteeringAngle m109 : 45|14@0+ (0.1,-819.2) [-819.2|819.1] "deg" Vector__XXX
 SG_ RCM_a109_eventDriverBrakeApply m109 : 46|2@1+ (1,0) [0|2] "" Vector__XXX
 SG_ RCM_a109_eventAccelPedalPos m109 : 56|8@1+ (0.4,0) [0|101.6] "%" Vector__XXX
 SG_ RCM_a110_eventArmStatus m110 : 11|1@1+ (1,0) [0|1] "" Vector__XXX
 SG_ RCM_a110_eventFactoryMode m110 : 12|1@1+ (1,0) [0|1] "" Vector__XXX
 SG_ RCM_a110_eventDiagEnabled m110 : 13|1@1+ (1,0) [0|1] "" Vector__XXX
 SG_ RCM_a110_eventDriveOrientation m110 : 14|1@1+ (1,0) [0|1] "" Vector__XXX
 SG_ RCM_a110_inFactoryMode m110 : 16|1@1+ (1,0) [0|1] "" Vector__XXX
 SG_ RCM_a110_eventIDFsignal m110 : 25|1@1+ (1,0) [0|1] "" Vector__XXX
 SG_ RCM_a110_eventFrontLeftSeatbelt m110 : 26|1@1+ (1,0) [0|1] "" Vector__XXX
 SG_ RCM_a110_eventFrontRightSeatbelt m110 : 27|1@1+ (1,0) [0|1] "" Vector__XXX
 SG_ RCM_a110_eventVehicleSpeed m110 : 28|12@1+ (0.08,-40) [-40|287.6] "kph" Vector__XXX
 SG_ RCM_a110_eventSteeringAngle m110 : 45|14@0+ (0.1,-819.2) [-819.2|819.1] "deg" Vector__XXX
 SG_ RCM_a110_eventDriverBrakeApply m110 : 46|2@1+ (1,0) [0|2] "" Vector__XXX
 SG_ RCM_a110_eventAccelPedalPos m110 : 56|8@1+ (0.4,0) [0|101.6] "%" Vector__XXX
 SG_ RCM_a112_eventArmStatus m112 : 11|1@1+ (1,0) [0|1] "" Vector__XXX
 SG_ RCM_a112_eventFactoryMode m112 : 12|1@1+ (1,0) [0|1] "" Vector__XXX
 SG_ RCM_a112_eventDiagEnabled m112 : 13|1@1+ (1,0) [0|1] "" Vector__XXX
 SG_ RCM_a112_eventDriveOrientation m112 : 14|1@1+ (1,0) [0|1] "" Vector__XXX
 SG_ RCM_a112_imuYawR8SnsrMonitTmp m112 : 16|1@1+ (1,0) [0|1] "" Vector__XXX
 SG_ RCM_a112_imuYawR8SnsrMonitPerm m112 : 17|1@1+ (1,0) [0|1] "" Vector__XXX
 SG_ RCM_a112_imuYawR8ChnlMonitTmp m112 : 19|1@1+ (1,0) [0|1] "" Vector__XXX
 SG_ RCM_a112_imuYawR8ChnlMonitPerm m112 : 20|1@1+ (1,0) [0|1] "" Vector__XXX
 SG_ RCM_a112_eventIDFsignal m112 : 25|1@1+ (1,0) [0|1] "" Vector__XXX
 SG_ RCM_a112_eventFrontLeftSeatbelt m112 : 26|1@1+ (1,0) [0|1] "" Vector__XXX
 SG_ RCM_a112_eventFrontRightSeatbelt m112 : 27|1@1+ (1,0) [0|1] "" Vector__XXX
 SG_ RCM_a112_eventVehicleSpeed m112 : 28|12@1+ (0.08,-40) [-40|287.6] "kph" Vector__XXX
 SG_ RCM_a112_eventSteeringAngle m112 : 45|14@0+ (0.1,-819.2) [-819.2|819.1] "deg" Vector__XXX
 SG_ RCM_a112_eventDriverBrakeApply m112 : 46|2@1+ (1,0) [0|2] "" Vector__XXX
 SG_ RCM_a112_eventAccelPedalPos m112 : 56|8@1+ (0.4,0) [0|101.6] "%" Vector__XXX
 SG_ RCM_a113_eventArmStatus m113 : 11|1@1+ (1,0) [0|1] "" Vector__XXX
 SG_ RCM_a113_eventFactoryMode m113 : 12|1@1+ (1,0) [0|1] "" Vector__XXX
 SG_ RCM_a113_eventDiagEnabled m113 : 13|1@1+ (1,0) [0|1] "" Vector__XXX
 SG_ RCM_a113_eventDriveOrientation m113 : 14|1@1+ (1,0) [0|1] "" Vector__XXX
 SG_ RCM_a113_imuPitchR8SnsrMonitTmp m113 : 16|1@1+ (1,0) [0|1] "" Vector__XXX
 SG_ RCM_a113_imuPitchR8SnsrMonitPerm m113 : 17|1@1+ (1,0) [0|1] "" Vector__XXX
 SG_ RCM_a113_imuPitchR8ChnlMonitTmp m113 : 18|1@1+ (1,0) [0|1] "" Vector__XXX
 SG_ RCM_a113_imuPitchR8ChnlMonitPerm m113 : 19|1@1+ (1,0) [0|1] "" Vector__XXX
 SG_ RCM_a113_eventIDFsignal m113 : 25|1@1+ (1,0) [0|1] "" Vector__XXX
 SG_ RCM_a113_eventFrontLeftSeatbelt m113 : 26|1@1+ (1,0) [0|1] "" Vector__XXX
 SG_ RCM_a113_eventFrontRightSeatbelt m113 : 27|1@1+ (1,0) [0|1] "" Vector__XXX
 SG_ RCM_a113_eventVehicleSpeed m113 : 28|12@1+ (0.08,-40) [-40|287.6] "kph" Vector__XXX
 SG_ RCM_a113_eventSteeringAngle m113 : 45|14@0+ (0.1,-819.2) [-819.2|819.1] "deg" Vector__XXX
 SG_ RCM_a113_eventDriverBrakeApply m113 : 46|2@1+ (1,0) [0|2] "" Vector__XXX
 SG_ RCM_a113_eventAccelPedalPos m113 : 56|8@1+ (0.4,0) [0|101.6] "%" Vector__XXX
 SG_ RCM_a114_eventArmStatus m114 : 11|1@1+ (1,0) [0|1] "" Vector__XXX
 SG_ RCM_a114_eventFactoryMode m114 : 12|1@1+ (1,0) [0|1] "" Vector__XXX
 SG_ RCM_a114_eventDiagEnabled m114 : 13|1@1+ (1,0) [0|1] "" Vector__XXX
 SG_ RCM_a114_eventDriveOrientation m114 : 14|1@1+ (1,0) [0|1] "" Vector__XXX
 SG_ RCM_a114_imuRollR8SnsrMonitTmp m114 : 16|1@1+ (1,0) [0|1] "" Vector__XXX
 SG_ RCM_a114_imuRollR8SnsrMonitPerm m114 : 17|1@1+ (1,0) [0|1] "" Vector__XXX
 SG_ RCM_a114_imuRollR8ChnlMonitTmp m114 : 18|1@1+ (1,0) [0|1] "" Vector__XXX
 SG_ RCM_a114_imuRollR8ChnlMonitPerm m114 : 19|1@1+ (1,0) [0|1] "" Vector__XXX
 SG_ RCM_a114_eventIDFsignal m114 : 25|1@1+ (1,0) [0|1] "" Vector__XXX
 SG_ RCM_a114_eventFrontLeftSeatbelt m114 : 26|1@1+ (1,0) [0|1] "" Vector__XXX
 SG_ RCM_a114_eventFrontRightSeatbelt m114 : 27|1@1+ (1,0) [0|1] "" Vector__XXX
 SG_ RCM_a114_eventVehicleSpeed m114 : 28|12@1+ (0.08,-40) [-40|287.6] "kph" Vector__XXX
 SG_ RCM_a114_eventSteeringAngle m114 : 45|14@0+ (0.1,-819.2) [-819.2|819.1] "deg" Vector__XXX
 SG_ RCM_a114_eventDriverBrakeApply m114 : 46|2@1+ (1,0) [0|2] "" Vector__XXX
 SG_ RCM_a114_eventAccelPedalPos m114 : 56|8@1+ (0.4,0) [0|101.6] "%" Vector__XXX
 SG_ RCM_a115_eventArmStatus m115 : 11|1@1+ (1,0) [0|1] "" Vector__XXX
 SG_ RCM_a115_eventFactoryMode m115 : 12|1@1+ (1,0) [0|1] "" Vector__XXX
 SG_ RCM_a115_eventDiagEnabled m115 : 13|1@1+ (1,0) [0|1] "" Vector__XXX
 SG_ RCM_a115_eventDriveOrientation m115 : 14|1@1+ (1,0) [0|1] "" Vector__XXX
 SG_ RCM_a115_imuLinAccChnlMonitTmp m115 : 16|1@1+ (1,0) [0|1] "" Vector__XXX
 SG_ RCM_a115_imuLinAccChnlMonitPerm m115 : 17|1@1+ (1,0) [0|1] "" Vector__XXX
 SG_ RCM_a115_eventIDFsignal m115 : 25|1@1+ (1,0) [0|1] "" Vector__XXX
 SG_ RCM_a115_eventFrontLeftSeatbelt m115 : 26|1@1+ (1,0) [0|1] "" Vector__XXX
 SG_ RCM_a115_eventFrontRightSeatbelt m115 : 27|1@1+ (1,0) [0|1] "" Vector__XXX
 SG_ RCM_a115_eventVehicleSpeed m115 : 28|12@1+ (0.08,-40) [-40|287.6] "kph" Vector__XXX
 SG_ RCM_a115_eventSteeringAngle m115 : 45|14@0+ (0.1,-819.2) [-819.2|819.1] "deg" Vector__XXX
 SG_ RCM_a115_eventDriverBrakeApply m115 : 46|2@1+ (1,0) [0|2] "" Vector__XXX
 SG_ RCM_a115_eventAccelPedalPos m115 : 56|8@1+ (0.4,0) [0|101.6] "%" Vector__XXX
 SG_ RCM_a116_eventArmStatus m116 : 11|1@1+ (1,0) [0|1] "" Vector__XXX
 SG_ RCM_a116_eventFactoryMode m116 : 12|1@1+ (1,0) [0|1] "" Vector__XXX
 SG_ RCM_a116_eventDiagEnabled m116 : 13|1@1+ (1,0) [0|1] "" Vector__XXX
 SG_ RCM_a116_eventDriveOrientation m116 : 14|1@1+ (1,0) [0|1] "" Vector__XXX
 SG_ RCM_a116_imuLatAccChnlMonitTmp m116 : 16|1@1+ (1,0) [0|1] "" Vector__XXX
 SG_ RCM_a116_imuLatAccChnlMonitPerm m116 : 17|1@1+ (1,0) [0|1] "" Vector__XXX
 SG_ RCM_a116_eventIDFsignal m116 : 25|1@1+ (1,0) [0|1] "" Vector__XXX
 SG_ RCM_a116_eventFrontLeftSeatbelt m116 : 26|1@1+ (1,0) [0|1] "" Vector__XXX
 SG_ RCM_a116_eventFrontRightSeatbelt m116 : 27|1@1+ (1,0) [0|1] "" Vector__XXX
 SG_ RCM_a116_eventVehicleSpeed m116 : 28|12@1+ (0.08,-40) [-40|287.6] "kph" Vector__XXX
 SG_ RCM_a116_eventSteeringAngle m116 : 45|14@0+ (0.1,-819.2) [-819.2|819.1] "deg" Vector__XXX
 SG_ RCM_a116_eventDriverBrakeApply m116 : 46|2@1+ (1,0) [0|2] "" Vector__XXX
 SG_ RCM_a116_eventAccelPedalPos m116 : 56|8@1+ (0.4,0) [0|101.6] "%" Vector__XXX
 SG_ RCM_a117_eventArmStatus m117 : 11|1@1+ (1,0) [0|1] "" Vector__XXX
 SG_ RCM_a117_eventFactoryMode m117 : 12|1@1+ (1,0) [0|1] "" Vector__XXX
 SG_ RCM_a117_eventDiagEnabled m117 : 13|1@1+ (1,0) [0|1] "" Vector__XXX
 SG_ RCM_a117_eventDriveOrientation m117 : 14|1@1+ (1,0) [0|1] "" Vector__XXX
 SG_ RCM_a117_imuZaccelChnlMonitTmp m117 : 16|1@1+ (1,0) [0|1] "" Vector__XXX
 SG_ RCM_a117_imuZaccelChnlMonitPerm m117 : 17|1@1+ (1,0) [0|1] "" Vector__XXX
 SG_ RCM_a117_eventIDFsignal m117 : 25|1@1+ (1,0) [0|1] "" Vector__XXX
 SG_ RCM_a117_eventFrontLeftSeatbelt m117 : 26|1@1+ (1,0) [0|1] "" Vector__XXX
 SG_ RCM_a117_eventFrontRightSeatbelt m117 : 27|1@1+ (1,0) [0|1] "" Vector__XXX
 SG_ RCM_a117_eventVehicleSpeed m117 : 28|12@1+ (0.08,-40) [-40|287.6] "kph" Vector__XXX
 SG_ RCM_a117_eventSteeringAngle m117 : 45|14@0+ (0.1,-819.2) [-819.2|819.1] "deg" Vector__XXX
 SG_ RCM_a117_eventDriverBrakeApply m117 : 46|2@1+ (1,0) [0|2] "" Vector__XXX
 SG_ RCM_a117_eventAccelPedalPos m117 : 56|8@1+ (0.4,0) [0|101.6] "%" Vector__XXX
 SG_ RCM_a118_eventArmStatus m118 : 11|1@1+ (1,0) [0|1] "" Vector__XXX
 SG_ RCM_a118_eventFactoryMode m118 : 12|1@1+ (1,0) [0|1] "" Vector__XXX
 SG_ RCM_a118_eventDiagEnabled m118 : 13|1@1+ (1,0) [0|1] "" Vector__XXX
 SG_ RCM_a118_eventDriveOrientation m118 : 14|1@1+ (1,0) [0|1] "" Vector__XXX
 SG_ RCM_a118_imuInPlaneSnsrMonitTmp m118 : 16|1@1+ (1,0) [0|1] "" Vector__XXX
 SG_ RCM_a118_imuInPlaneSnsrMonitPerm m118 : 17|1@1+ (1,0) [0|1] "" Vector__XXX
 SG_ RCM_a118_eventIDFsignal m118 : 25|1@1+ (1,0) [0|1] "" Vector__XXX
 SG_ RCM_a118_eventFrontLeftSeatbelt m118 : 26|1@1+ (1,0) [0|1] "" Vector__XXX
 SG_ RCM_a118_eventFrontRightSeatbelt m118 : 27|1@1+ (1,0) [0|1] "" Vector__XXX
 SG_ RCM_a118_eventVehicleSpeed m118 : 28|12@1+ (0.08,-40) [-40|287.6] "kph" Vector__XXX
 SG_ RCM_a118_eventSteeringAngle m118 : 45|14@0+ (0.1,-819.2) [-819.2|819.1] "deg" Vector__XXX
 SG_ RCM_a118_eventDriverBrakeApply m118 : 46|2@1+ (1,0) [0|2] "" Vector__XXX
 SG_ RCM_a118_eventAccelPedalPos m118 : 56|8@1+ (0.4,0) [0|101.6] "%" Vector__XXX

BO_ 881 RCM_alertMatrix: 8 RCM
 SG_ RCM_matrixIndex M : 0|4@1+ (1,0) [0|15] "" Vector__XXX
 SG_ RCM_a000_crashDetected m0 : 4|1@1+ (1,0) [0|1] "" Vector__XXX
 SG_ RCM_a001_nearDeploy m0 : 5|1@1+ (1,0) [0|1] "" Vector__XXX
 SG_ RCM_a002_airbagsNotArmed m0 : 6|1@1+ (1,0) [0|1] "" Vector__XXX
 SG_ RCM_a003_warningIndicator m0 : 7|1@1+ (1,0) [0|1] "" Vector__XXX
 SG_ RCM_a004_internalFault m0 : 8|1@1+ (1,0) [0|1] "" Vector__XXX
 SG_ RCM_a005_crcError m0 : 9|1@1+ (1,0) [0|1] "" Vector__XXX
 SG_ RCM_a006_batteryVoltageRange m0 : 10|1@1+ (1,0) [0|1] "" Vector__XXX
 SG_ RCM_a007_powerSupplyExternal m0 : 11|1@1+ (1,0) [0|1] "" Vector__XXX
 SG_ RCM_a008_powerSupplyInternal m0 : 12|1@1+ (1,0) [0|1] "" Vector__XXX
 SG_ RCM_a009_reprogramLimit m0 : 13|1@1+ (1,0) [0|1] "" Vector__XXX
 SG_ RCM_a010_scmDisabled m0 : 14|1@1+ (1,0) [0|1] "" Vector__XXX
 SG_ RCM_a011_eepromDataLocked m0 : 15|1@1+ (1,0) [0|1] "" Vector__XXX
 SG_ RCM_a012_vinStorage m0 : 16|1@1+ (1,0) [0|1] "" Vector__XXX
 SG_ RCM_a013_driverOrientation m0 : 17|1@1+ (1,0) [0|1] "" Vector__XXX
 SG_ RCM_a014_driverABStage1 m0 : 18|1@1+ (1,0) [0|1] "" Vector__XXX
 SG_ RCM_a015_driverABStage2 m0 : 19|1@1+ (1,0) [0|1] "" Vector__XXX
 SG_ RCM_a016_passABStage1 m0 : 20|1@1+ (1,0) [0|1] "" Vector__XXX
 SG_ RCM_a017_passABStage2 m0 : 21|1@1+ (1,0) [0|1] "" Vector__XXX
 SG_ RCM_a018_passengerActiveVent m0 : 22|1@1+ (1,0) [0|1] "" Vector__XXX
 SG_ RCM_a019_pretenShldrFrontLeft m0 : 23|1@1+ (1,0) [0|1] "" Vector__XXX
 SG_ RCM_a020_pretenShldFrontRight m0 : 24|1@1+ (1,0) [0|1] "" Vector__XXX
 SG_ RCM_a021_pretenLapFrontLeft m0 : 25|1@1+ (1,0) [0|1] "" Vector__XXX
 SG_ RCM_a022_pretenLapFrontRight m0 : 26|1@1+ (1,0) [0|1] "" Vector__XXX
 SG_ RCM_a023_loadLimiterLeftSide m0 : 27|1@1+ (1,0) [0|1] "" Vector__XXX
 SG_ RCM_a024_loadLimiterRightSide m0 : 28|1@1+ (1,0) [0|1] "" Vector__XXX
 SG_ RCM_a025_kneeABDriver m0 : 29|1@1+ (1,0) [0|1] "" Vector__XXX
 SG_ RCM_a026_kneeABFrontPassenger m0 : 30|1@1+ (1,0) [0|1] "" Vector__XXX
 SG_ RCM_a027_sideAB1stRowLeft m0 : 31|1@1+ (1,0) [0|1] "" Vector__XXX
 SG_ RCM_a028_sideAB1stRowRight m0 : 32|1@1+ (1,0) [0|1] "" Vector__XXX
 SG_ RCM_a029_driverABActiveVent m0 : 33|1@1+ (1,0) [0|1] "" Vector__XXX
 SG_ RCM_a030_farSideInboardAirbag m0 : 34|1@1+ (1,0) [0|1] "" Vector__XXX
 SG_ RCM_a031_frontCenterAirbag m0 : 35|1@1+ (1,0) [0|1] "" Vector__XXX
 SG_ RCM_a032_curtainABLeft m0 : 36|1@1+ (1,0) [0|1] "" Vector__XXX
 SG_ RCM_a033_curtainABRight m0 : 37|1@1+ (1,0) [0|1] "" Vector__XXX
 SG_ RCM_a034_preten2ndRowLeft m0 : 38|1@1+ (1,0) [0|1] "" Vector__XXX
 SG_ RCM_a035_preten2ndRowRight m0 : 39|1@1+ (1,0) [0|1] "" Vector__XXX
 SG_ RCM_a036_curAB2ndRowLeft m0 : 40|1@1+ (1,0) [0|1] "" Vector__XXX
 SG_ RCM_a037_curAB2ndRowRight m0 : 41|1@1+ (1,0) [0|1] "" Vector__XXX
 SG_ RCM_a038_unusedA m0 : 42|1@1+ (1,0) [0|1] "" Vector__XXX
 SG_ RCM_a039_unusedB m0 : 43|1@1+ (1,0) [0|1] "" Vector__XXX
 SG_ RCM_a040_hoodActuatorRight m0 : 44|1@1+ (1,0) [0|1] "" Vector__XXX
 SG_ RCM_a041_hoodActuatorLeft m0 : 45|1@1+ (1,0) [0|1] "" Vector__XXX
 SG_ RCM_a042_ens1Line m0 : 46|1@1+ (1,0) [0|1] "" Vector__XXX
 SG_ RCM_a043_ens2Line m0 : 47|1@1+ (1,0) [0|1] "" Vector__XXX
 SG_ RCM_a044_upFrontSensorLeft m0 : 48|1@1+ (1,0) [0|1] "" Vector__XXX
 SG_ RCM_a045_upFrontSensorRight m0 : 49|1@1+ (1,0) [0|1] "" Vector__XXX
 SG_ RCM_a046_sideAccelBPillarLeft m0 : 50|1@1+ (1,0) [0|1] "" Vector__XXX
 SG_ RCM_a047_sideAccelBPillarRight m0 : 51|1@1+ (1,0) [0|1] "" Vector__XXX
 SG_ RCM_a048_sideAccelCPillarLeft m0 : 52|1@1+ (1,0) [0|1] "" Vector__XXX
 SG_ RCM_a049_sideAccelCPillarRight m0 : 53|1@1+ (1,0) [0|1] "" Vector__XXX
 SG_ RCM_a050_upFrontSensorCenter m0 : 54|1@1+ (1,0) [0|1] "" Vector__XXX
 SG_ RCM_a051_pressureFrontLftDoor m0 : 55|1@1+ (1,0) [0|1] "" Vector__XXX
 SG_ RCM_a052_pressureFrontRtDoor m0 : 56|1@1+ (1,0) [0|1] "" Vector__XXX
 SG_ RCM_a053_pressurePedProLeft m0 : 57|1@1+ (1,0) [0|1] "" Vector__XXX
 SG_ RCM_a054_pressurePedProRight m0 : 58|1@1+ (1,0) [0|1] "" Vector__XXX
 SG_ RCM_a055_inertialMeasurement m0 : 59|1@1+ (1,0) [0|1] "" Vector__XXX
 SG_ RCM_a056_passengerFrontOCS m0 : 60|1@1+ (1,0) [0|1] "" Vector__XXX
 SG_ RCM_a057_driverOCS m0 : 61|1@1+ (1,0) [0|1] "" Vector__XXX
 SG_ RCM_a058_buckle1stRowLeft m0 : 62|1@1+ (1,0) [0|1] "" Vector__XXX
 SG_ RCM_a059_buckle1stRowRight m0 : 63|1@1+ (1,0) [0|1] "" Vector__XXX
 SG_ RCM_a060_stpsLeft m1 : 4|1@1+ (1,0) [0|1] "" Vector__XXX
 SG_ RCM_a061_stpsRight m1 : 5|1@1+ (1,0) [0|1] "" Vector__XXX
 SG_ RCM_a062_alrSwitch m1 : 6|1@1+ (1,0) [0|1] "" Vector__XXX
 SG_ RCM_a063_sbsw2ndRowRight m1 : 7|1@1+ (1,0) [0|1] "" Vector__XXX
 SG_ RCM_a064_hardwareCodingPin1 m1 : 8|1@1+ (1,0) [0|1] "" Vector__XXX
 SG_ RCM_a065_driverOrientConfigPin m1 : 9|1@1+ (1,0) [0|1] "" Vector__XXX
 SG_ RCM_a066_seatBackSw2ndRowLeft m1 : 10|1@1+ (1,0) [0|1] "" Vector__XXX
 SG_ RCM_a067_comCANInitFailure m1 : 11|1@1+ (1,0) [0|1] "" Vector__XXX
 SG_ RCM_a068_comChassisBusOff m1 : 12|1@1+ (1,0) [0|1] "" Vector__XXX
 SG_ RCM_a069_comCHCANPH7 m1 : 13|1@1+ (1,0) [0|1] "" Vector__XXX
 SG_ RCM_a070_comCHCANPH8 m1 : 14|1@1+ (1,0) [0|1] "" Vector__XXX
 SG_ RCM_a071_comCHCANPH9 m1 : 15|1@1+ (1,0) [0|1] "" Vector__XXX
 SG_ RCM_a072_comUnused m1 : 16|1@1+ (1,0) [0|1] "" Vector__XXX
 SG_ RCM_a073_comCHCANPH4 m1 : 17|1@1+ (1,0) [0|1] "" Vector__XXX
 SG_ RCM_a074_comCHCANPH5 m1 : 18|1@1+ (1,0) [0|1] "" Vector__XXX
 SG_ RCM_a075_comCHCANPH6 m1 : 19|1@1+ (1,0) [0|1] "" Vector__XXX
 SG_ RCM_a076_comEPBLStatus m1 : 20|1@1+ (1,0) [0|1] "" Vector__XXX
 SG_ RCM_a077_comEPBRStatus m1 : 21|1@1+ (1,0) [0|1] "" Vector__XXX
 SG_ RCM_a078_comOCS1PStatus m1 : 22|1@1+ (1,0) [0|1] "" Vector__XXX
 SG_ RCM_a079_comOCS1DStatus m1 : 23|1@1+ (1,0) [0|1] "" Vector__XXX
 SG_ RCM_a080_comGTWACS m1 : 24|1@1+ (1,0) [0|1] "" Vector__XXX
 SG_ RCM_a081_comVCFRONTLVPwr m1 : 25|1@1+ (1,0) [0|1] "" Vector__XXX
 SG_ RCM_a082_comUIodo m1 : 26|1@1+ (1,0) [0|1] "" Vector__XXX
 SG_ RCM_a083_comGTWCarState m1 : 27|1@1+ (1,0) [0|1] "" Vector__XXX
 SG_ RCM_a084_comTPMSStatus m1 : 28|1@1+ (1,0) [0|1] "" Vector__XXX
 SG_ RCM_a085_comGTWCarConfig m1 : 29|1@1+ (1,0) [0|1] "" Vector__XXX
 SG_ RCM_a086_comVINMIA m1 : 30|1@1+ (1,0) [0|1] "" Vector__XXX
 SG_ RCM_a087_comCANSilent m1 : 31|1@1+ (1,0) [0|1] "" Vector__XXX
 SG_ RCM_a088_comCHCANPH2 m1 : 32|1@1+ (1,0) [0|1] "" Vector__XXX
 SG_ RCM_a089_comCHCANPH3 m1 : 33|1@1+ (1,0) [0|1] "" Vector__XXX
 SG_ RCM_a090_comPartyBusOff m1 : 34|1@1+ (1,0) [0|1] "" Vector__XXX
 SG_ RCM_a091_comEPAS3PsysStatus m1 : 35|1@1+ (1,0) [0|1] "" Vector__XXX
 SG_ RCM_a092_comDASISF m1 : 36|1@1+ (1,0) [0|1] "" Vector__XXX
 SG_ RCM_a093_comVCLEFTStatus m1 : 37|1@1+ (1,0) [0|1] "" Vector__XXX
 SG_ RCM_a094_comVCRIGHTStatus m1 : 38|1@1+ (1,0) [0|1] "" Vector__XXX
 SG_ RCM_a095_comESPstatus m1 : 39|1@1+ (1,0) [0|1] "" Vector__XXX
 SG_ RCM_a096_comESPwheelSpeeds m1 : 40|1@1+ (1,0) [0|1] "" Vector__XXX
 SG_ RCM_a097_comDIspeed m1 : 41|1@1+ (1,0) [0|1] "" Vector__XXX
 SG_ RCM_a098_comDIchassisControl m1 : 42|1@1+ (1,0) [0|1] "" Vector__XXX
 SG_ RCM_a099_comDItorque m1 : 43|1@1+ (1,0) [0|1] "" Vector__XXX
 SG_ RCM_a100_comDIsystemStatus m1 : 44|1@1+ (1,0) [0|1] "" Vector__XXX
 SG_ RCM_a101_idfSystem m1 : 45|1@1+ (1,0) [0|1] "" Vector__XXX
 SG_ RCM_a102_imuYawR8OffstCompLim m1 : 46|1@1+ (1,0) [0|1] "" Vector__XXX
 SG_ RCM_a103_imuPtchR8OffstCompLim m1 : 47|1@1+ (1,0) [0|1] "" Vector__XXX
 SG_ RCM_a104_imuRollR8OffstCompLim m1 : 48|1@1+ (1,0) [0|1] "" Vector__XXX
 SG_ RCM_a105_imuLongAccOffstCompLim m1 : 49|1@1+ (1,0) [0|1] "" Vector__XXX
 SG_ RCM_a106_imuLatAccOffstCompLim m1 : 50|1@1+ (1,0) [0|1] "" Vector__XXX
 SG_ RCM_a107_imuVertAccOffstCompLim m1 : 51|1@1+ (1,0) [0|1] "" Vector__XXX
 SG_ RCM_a108_crashAlgoWakeup m1 : 52|1@1+ (1,0) [0|1] "" Vector__XXX
 SG_ RCM_a109_abuseImmunity m1 : 53|1@1+ (1,0) [0|1] "" Vector__XXX
 SG_ RCM_a110_factoryMode m1 : 54|1@1+ (1,0) [0|1] "" Vector__XXX
 SG_ RCM_a111_diagnosticsEnabled m1 : 55|1@1+ (1,0) [0|1] "" Vector__XXX
 SG_ RCM_a112_imuYawRate m1 : 56|1@1+ (1,0) [0|1] "" Vector__XXX
 SG_ RCM_a113_imuPitchRate m1 : 57|1@1+ (1,0) [0|1] "" Vector__XXX
 SG_ RCM_a114_imuRollRate m1 : 58|1@1+ (1,0) [0|1] "" Vector__XXX
 SG_ RCM_a115_imuLinearAcceleration m1 : 59|1@1+ (1,0) [0|1] "" Vector__XXX
 SG_ RCM_a116_imuLateralAcceleration m1 : 60|1@1+ (1,0) [0|1] "" Vector__XXX
 SG_ RCM_a117_imuVerticalAcceleration m1 : 61|1@1+ (1,0) [0|1] "" Vector__XXX
 SG_ RCM_a118_imuInPlaneAcceleration m1 : 62|1@1+ (1,0) [0|1] "" Vector__XXX

BO_ 1471 RCU_alertLog: 8 RCU
 SG_ RCU_alertID M : 0|7@1+ (1,0) [0|127] "" Vector__XXX
 SG_ RCU_alertState : 15|1@1+ (1,0) [0|1] "" Vector__XXX
 SG_ RCU_a010_sensorPowerSupply m10 : 16|1@1+ (1,0) [0|1] "" Vector__XXX
 SG_ RCU_a010_sensorHardware m10 : 17|1@1+ (1,0) [0|1] "" Vector__XXX
 SG_ RCU_a010_sensorSignal m10 : 18|1@1+ (1,0) [0|1] "" Vector__XXX
 SG_ RCU_a023_validityOnChassisBus m23 : 16|1@1+ (1,0) [0|1] "" Vector__XXX
 SG_ RCU_a023_validityOnPartyBus m23 : 17|1@1+ (1,0) [0|1] "" Vector__XXX
 SG_ RCU_a024_validityOnChassisBus m24 : 16|1@1+ (1,0) [0|1] "" Vector__XXX
 SG_ RCU_a024_validityOnPartyBus m24 : 17|1@1+ (1,0) [0|1] "" Vector__XXX
 SG_ RCU_a025_validityOnChassisBus m25 : 16|1@1+ (1,0) [0|1] "" Vector__XXX
 SG_ RCU_a025_validityOnPartyBus m25 : 17|1@1+ (1,0) [0|1] "" Vector__XXX
 SG_ RCU_a035_validityOnChassisBus m35 : 16|1@1+ (1,0) [0|1] "" Vector__XXX
 SG_ RCU_a035_validityOnPartyBus m35 : 17|1@1+ (1,0) [0|1] "" Vector__XXX
 SG_ RCU_a036_validityOnChassisBus m36 : 16|1@1+ (1,0) [0|1] "" Vector__XXX
 SG_ RCU_a036_validityOnPartyBus m36 : 17|1@1+ (1,0) [0|1] "" Vector__XXX

BO_ 998 RCU_alertMatrix: 8 RCU
 SG_ RCU_matrixIndex M : 0|4@1+ (1,0) [0|15] "" Vector__XXX
 SG_ RCU_a001_valveDriverFault m0 : 4|1@1+ (1,0) [0|1] "" Vector__XXX
 SG_ RCU_a002_solenoidValveFault m0 : 5|1@1+ (1,0) [0|1] "" Vector__XXX
 SG_ RCU_a003_pumpMotorFault m0 : 6|1@1+ (1,0) [0|1] "" Vector__XXX
 SG_ RCU_a004_supplyOvervoltage m0 : 7|1@1+ (1,0) [0|1] "" Vector__XXX
 SG_ RCU_a005_supplyUndervoltage m0 : 8|1@1+ (1,0) [0|1] "" Vector__XXX
 SG_ RCU_a006_wakeLineOpen m0 : 9|1@1+ (1,0) [0|1] "" Vector__XXX
 SG_ RCU_a007_pressureSensorFault m0 : 10|1@1+ (1,0) [0|1] "" Vector__XXX
 SG_ RCU_a008_pressureNotCalibrated m0 : 11|1@1+ (1,0) [0|1] "" Vector__XXX
 SG_ RCU_a009_brakeFluidLow m0 : 12|1@1+ (1,0) [0|1] "" Vector__XXX
 SG_ RCU_a010_pedalSensorFault m0 : 13|1@1+ (1,0) [0|1] "" Vector__XXX
 SG_ RCU_a011_idbPedalTravelMismatch m0 : 14|1@1+ (1,0) [0|1] "" Vector__XXX
 SG_ RCU_a012_pedalSensorNotCal m0 : 15|1@1+ (1,0) [0|1] "" Vector__XXX
 SG_ RCU_a013_mcuGenericFault m0 : 16|1@1+ (1,0) [0|1] "" Vector__XXX
 SG_ RCU_a014_asicTempHigh m0 : 17|1@1+ (1,0) [0|1] "" Vector__XXX
 SG_ RCU_a015_fluidLeakDetected m0 : 18|1@1+ (1,0) [0|1] "" Vector__XXX
 SG_ RCU_a016_partyBusOff m0 : 19|1@1+ (1,0) [0|1] "" Vector__XXX
 SG_ RCU_a017_chassisBusOff m0 : 20|1@1+ (1,0) [0|1] "" Vector__XXX
 SG_ RCU_a018_DItorquePathFaulted m0 : 21|1@1+ (1,0) [0|1] "" Vector__XXX
 SG_ RCU_a019_DItorquePathActive m0 : 22|1@1+ (1,0) [0|1] "" Vector__XXX
 SG_ RCU_a020_BBstatusDLC m0 : 23|1@1+ (1,0) [0|1] "" Vector__XXX
 SG_ RCU_a021_BBstatusChecksum m0 : 24|1@1+ (1,0) [0|1] "" Vector__XXX
 SG_ RCU_a022_BBstatusCounter m0 : 25|1@1+ (1,0) [0|1] "" Vector__XXX
 SG_ RCU_a023_IDBstatusDLC m0 : 26|1@1+ (1,0) [0|1] "" Vector__XXX
 SG_ RCU_a024_IDBstatusChecksum m0 : 27|1@1+ (1,0) [0|1] "" Vector__XXX
 SG_ RCU_a025_IDBstatusCounter m0 : 28|1@1+ (1,0) [0|1] "" Vector__XXX
 SG_ RCU_a026_DIchassisControlDLC m0 : 29|1@1+ (1,0) [0|1] "" Vector__XXX
 SG_ RCU_a027_DIchassisCtrlChecksum m0 : 30|1@1+ (1,0) [0|1] "" Vector__XXX
 SG_ RCU_a028_DIchassisControlCounter m0 : 31|1@1+ (1,0) [0|1] "" Vector__XXX
 SG_ RCU_a029_PMstate2DLC m0 : 32|1@1+ (1,0) [0|1] "" Vector__XXX
 SG_ RCU_a030_PMstate2Checksum m0 : 33|1@1+ (1,0) [0|1] "" Vector__XXX
 SG_ RCU_a031_PMstate2Counter m0 : 34|1@1+ (1,0) [0|1] "" Vector__XXX
 SG_ RCU_a032_VCFRONTLVPowerStateDLC m0 : 35|1@1+ (1,0) [0|1] "" Vector__XXX
 SG_ RCU_a033_VCFRONTLVPowerStateChec m0 : 36|1@1+ (1,0) [0|1] "" Vector__XXX
 SG_ RCU_a034_VCFRONTLVPowerStateCoun m0 : 37|1@1+ (1,0) [0|1] "" Vector__XXX
 SG_ RCU_a035_IDBpcpInvalid m0 : 38|1@1+ (1,0) [0|1] "" Vector__XXX
 SG_ RCU_a036_IDBpspInvalid m0 : 39|1@1+ (1,0) [0|1] "" Vector__XXX
 SG_ RCU_a037_IDBinputRodStrokeInvali m0 : 40|1@1+ (1,0) [0|1] "" Vector__XXX
 SG_ RCU_a038_DIsystemStatusDLC m0 : 41|1@1+ (1,0) [0|1] "" Vector__XXX
 SG_ RCU_a039_DIaccelPosInvalid m0 : 42|1@1+ (1,0) [0|1] "" Vector__XXX
 SG_ RCU_a040_DIgearInvalid m0 : 43|1@1+ (1,0) [0|1] "" Vector__XXX
 SG_ RCU_a041_DIsystemStatusCounter m0 : 44|1@1+ (1,0) [0|1] "" Vector__XXX
 SG_ RCU_a042_DIsystemStatusChecksum m0 : 45|1@1+ (1,0) [0|1] "" Vector__XXX
 SG_ RCU_a043_VCFRONTiBoosterLvStateI m0 : 46|1@1+ (1,0) [0|1] "" Vector__XXX
 SG_ RCU_a044_VCFRONTsensorsMIA m0 : 47|1@1+ (1,0) [0|1] "" Vector__XXX
 SG_ RCU_a045_VCFRONTtempInvalid m0 : 48|1@1+ (1,0) [0|1] "" Vector__XXX
 SG_ RCU_a046_brakeFluidLevelSNA m0 : 49|1@1+ (1,0) [0|1] "" Vector__XXX
 SG_ RCU_a047_ESPwheelSpeedsDLC m0 : 50|1@1+ (1,0) [0|1] "" Vector__XXX
 SG_ RCU_a048_ESPFrLWSSLInvalid m0 : 51|1@1+ (1,0) [0|1] "" Vector__XXX
 SG_ RCU_a049_ESPFrRWSSLInvalid m0 : 52|1@1+ (1,0) [0|1] "" Vector__XXX
 SG_ RCU_a050_ESPReLWSSLInvalid m0 : 53|1@1+ (1,0) [0|1] "" Vector__XXX
 SG_ RCU_a051_ESPReRWSSLInvalid m0 : 54|1@1+ (1,0) [0|1] "" Vector__XXX
 SG_ RCU_a052_ESPwheelSpeedsCounter m0 : 55|1@1+ (1,0) [0|1] "" Vector__XXX
 SG_ RCU_a053_ESPwheelSpeedsChecksum m0 : 56|1@1+ (1,0) [0|1] "" Vector__XXX
 SG_ RCU_a054_IDBcircuitPressFaulted m0 : 57|1@1+ (1,0) [0|1] "" Vector__XXX
 SG_ RCU_a055_IDBsimulatorPressFaulte m0 : 58|1@1+ (1,0) [0|1] "" Vector__XXX
 SG_ RCU_a056_redundantControllerIsMa m0 : 59|1@1+ (1,0) [0|1] "" Vector__XXX
 SG_ RCU_a057_DASredundantBrakingCont m0 : 60|1@1+ (1,0) [0|1] "" Vector__XXX
 SG_ RCU_a058_DASredundantBrakingCont m0 : 61|1@1+ (1,0) [0|1] "" Vector__XXX
 SG_ RCU_a059_DASredundantBrakingCont m0 : 62|1@1+ (1,0) [0|1] "" Vector__XXX
 SG_ RCU_a060_DASbrakeTorqueCommandIn m0 : 63|1@1+ (1,0) [0|1] "" Vector__XXX
 SG_ RCU_a061_DIlocStatus2DLC m1 : 4|1@1+ (1,0) [0|1] "" Vector__XXX
 SG_ RCU_a062_DIlocStatus2Counter m1 : 5|1@1+ (1,0) [0|1] "" Vector__XXX
 SG_ RCU_a063_DIlocStatus2Checksum m1 : 6|1@1+ (1,0) [0|1] "" Vector__XXX
 SG_ RCU_a064_ESPredundantBrakingStat m1 : 7|1@1+ (1,0) [0|1] "" Vector__XXX
 SG_ RCU_a065_ESPredundantBrakingStat m1 : 8|1@1+ (1,0) [0|1] "" Vector__XXX
 SG_ RCU_a066_ESPredundantBrakingStat m1 : 9|1@1+ (1,0) [0|1] "" Vector__XXX

BO_ 831 RCU_info: 8 RCU
 SG_ RCU_infoIndex M : 0|8@1+ (1,0) [0|255] "" Vector__XXX
 SG_ RCU_infoPcbaID m11 : 16|8@1+ (1,0) [0|255] "" Vector__XXX
 SG_ RCU_infoAssemblyID m11 : 24|8@1+ (1,0) [0|255] "" Vector__XXX
 SG_ RCU_infoUsageID m11 : 32|16@1+ (1,0) [0|65535] "" Vector__XXX
 SG_ RCU_infoSubUsageID m11 : 48|16@1+ (1,0) [0|65535] "" Vector__XXX

BO_ 1415 TCU2_SleepConfig: 1 TCU2
 SG_ TCU2_tc10Version : 0|2@1+ (1,0) [1|3] "" Vector__XXX

BO_ 1413 TCU2_alertLog: 8 TCU2
 SG_ TCU2_alertID M : 0|5@1+ (1,0) [0|31] "" Vector__XXX
 SG_ TCU2_alertState : 15|1@1+ (1,0) [0|1] "" Vector__XXX
 SG_ TCU2_w001_FailCode m1 : 16|32@1+ (1,0) [0|4294967295] "" Vector__XXX
 SG_ TCU2_w002_RejCause m2 : 16|32@1+ (1,0) [0|4294967295] "" Vector__XXX
 SG_ TCU2_w003_CallFailCode m3 : 16|32@1+ (1,0) [0|4294967295] "" Vector__XXX
 SG_ TCU2_w004_MSDFailCode m4 : 16|32@1+ (1,0) [0|4294967295] "" Vector__XXX
 SG_ TCU2_w006_Count m6 : 16|32@1+ (1,0) [0|4294967295] "" Vector__XXX
 SG_ TCU2_w007_Count m7 : 16|32@1+ (1,0) [0|4294967295] "" Vector__XXX
 SG_ TCU2_w009_CrashCode m9 : 16|32@1+ (1,0) [0|4294967295] "" Vector__XXX
 SG_ TCU2_w012_DataRAT m12 : 16|4@1+ (1,0) [0|15] "" Vector__XXX
 SG_ TCU2_w012_RSRP m12 : 20|8@1- (1,0) [-128|127] "dBm" Vector__XXX
 SG_ TCU2_w012_RSRQ m12 : 28|7@1- (1,0) [-64|63] "dBm" Vector__XXX
 SG_ TCU2_w012_MNC m12 : 45|10@1+ (1,0) [0|1023] "" Vector__XXX
 SG_ TCU2_w012_AvgQueueUsage m12 : 55|7@1+ (1,0) [0|127] "%" Vector__XXX
 SG_ TCU2_w012_NSAAvailable m12 : 62|2@1+ (1,0) [0|3] "" Vector__XXX
 SG_ TCU2_w013_DataRAT m13 : 16|4@1+ (1,0) [0|15] "" Vector__XXX
 SG_ TCU2_w013_RSRP m13 : 20|8@1- (1,0) [-128|127] "dBm" Vector__XXX
 SG_ TCU2_w013_RSRQ m13 : 28|7@1- (1,0) [-64|63] "dBm" Vector__XXX
 SG_ TCU2_w013_MNC m13 : 45|10@1+ (1,0) [0|1023] "" Vector__XXX
 SG_ TCU2_w013_AvgQueueUsage m13 : 55|7@1+ (1,0) [0|127] "%" Vector__XXX
 SG_ TCU2_w013_NSAAvailable m13 : 62|2@1+ (1,0) [0|3] "" Vector__XXX
 SG_ TCU2_w014_Reason m14 : 16|32@1- (1,0) [-2147483648|2147483647] "" Vector__XXX

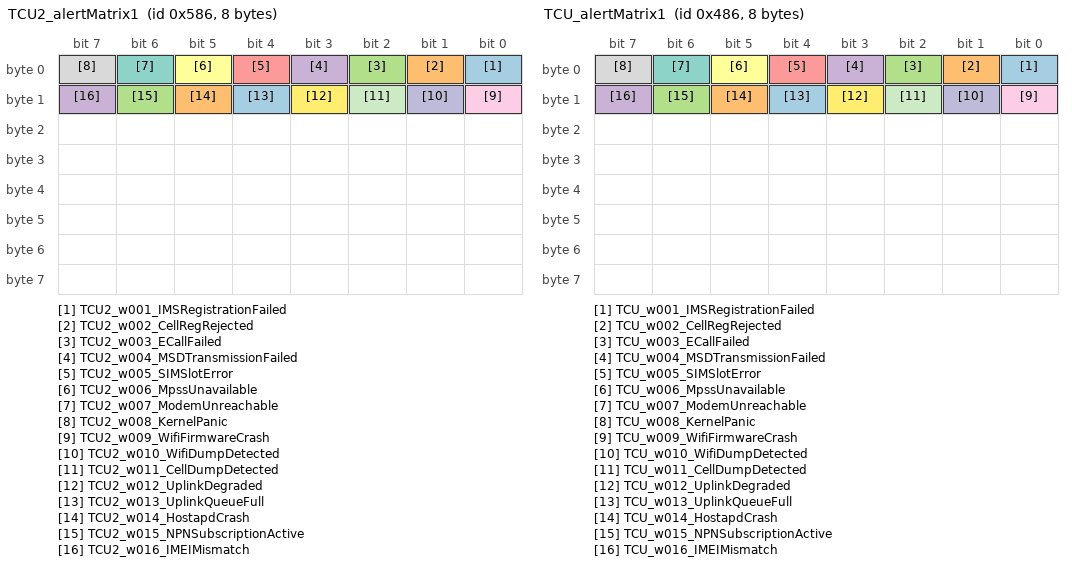
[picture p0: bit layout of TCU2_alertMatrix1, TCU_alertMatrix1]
BO_ 1414 TCU2_alertMatrix1: 8 TCU2
 SG_ TCU2_w001_IMSRegistrationFailed : 0|1@1+ (1,0) [0|1] "" Vector__XXX
 SG_ TCU2_w002_CellRegRejected : 1|1@1+ (1,0) [0|1] "" Vector__XXX
 SG_ TCU2_w003_ECallFailed : 2|1@1+ (1,0) [0|1] "" Vector__XXX
 SG_ TCU2_w004_MSDTransmissionFailed : 3|1@1+ (1,0) [0|1] "" Vector__XXX
 SG_ TCU2_w005_SIMSlotError : 4|1@1+ (1,0) [0|1] "" Vector__XXX
 SG_ TCU2_w006_MpssUnavailable : 5|1@1+ (1,0) [0|1] "" Vector__XXX
 SG_ TCU2_w007_ModemUnreachable : 6|1@1+ (1,0) [0|1] "" Vector__XXX
 SG_ TCU2_w008_KernelPanic : 7|1@1+ (1,0) [0|1] "" Vector__XXX
 SG_ TCU2_w009_WifiFirmwareCrash : 8|1@1+ (1,0) [0|1] "" Vector__XXX
 SG_ TCU2_w010_WifiDumpDetected : 9|1@1+ (1,0) [0|1] "" Vector__XXX
 SG_ TCU2_w011_CellDumpDetected : 10|1@1+ (1,0) [0|1] "" Vector__XXX
 SG_ TCU2_w012_UplinkDegraded : 11|1@1+ (1,0) [0|1] "" Vector__XXX
 SG_ TCU2_w013_UplinkQueueFull : 12|1@1+ (1,0) [0|1] "" Vector__XXX
 SG_ TCU2_w014_HostapdCrash : 13|1@1+ (1,0) [0|1] "" Vector__XXX
 SG_ TCU2_w015_NPNSubscriptionActive : 14|1@1+ (1,0) [0|1] "" Vector__XXX
 SG_ TCU2_w016_IMEIMismatch : 15|1@1+ (1,0) [0|1] "" Vector__XXX

BO_ 1412 TCU2_log: 8 TCU2
 SG_ TCU2_logMux M : 0|32@1+ (1,0) [0|4294967295] "" Vector__XXX
 SG_ TCU2_cpuTemp m0 : 32|32@1+ (1,0) [0|4294967295] "C" Vector__XXX
 SG_ TCU2_cpuUsage m1 : 32|32@1+ (1,0) [0|4294967295] "%" Vector__XXX
 SG_ TCU2_mdmCoreTemperature m2 : 32|32@1+ (1,0) [0|4294967295] "C" Vector__XXX
 SG_ TCU2_availableMemory m3 : 32|32@1+ (1,0) [0|4294967295] "KB" Vector__XXX
 SG_ TCU2_pwm m4 : 32|32@1+ (1,0) [0|4294967295] "" Vector__XXX
 SG_ TCU2_pwmcap m5 : 32|32@1+ (1,0) [0|4294967295] "" Vector__XXX
 SG_ TCU2_totalResumes m6 : 32|32@1+ (1,0) [0|4294967295] "" Vector__XXX
 SG_ TCU2_mdmUplinkQueueSize m7 : 32|32@1+ (1,0) [0|4294967295] "bytes" Vector__XXX
 SG_ TCU2_mdmRSRP m8 : 32|32@1- (1,0) [-2147483648|2147483647] "dBm" Vector__XXX
 SG_ TCU2_mdmSINR m9 : 32|32@1- (1,0) [-2147483648|2147483647] "dBm" Vector__XXX
 SG_ TCU2_mdmUplinkAllowedRate m10 : 32|32@1+ (1,0) [0|4294967295] "Kbps" Vector__XXX
 SG_ TCU2_mdmUplinkAvgRate m11 : 32|32@1+ (1,0) [0|4294967295] "Kbps" Vector__XXX
 SG_ TCU2_mdmServiceState m12 : 32|32@1+ (1,0) [0|4294967295] "" Vector__XXX
 SG_ TCU2_mdmIMSStatus m13 : 32|32@1+ (1,0) [0|4294967295] "" Vector__XXX
 SG_ TCU2_mdmSIMStatus m14 : 32|32@1+ (1,0) [0|4294967295] "" Vector__XXX
 SG_ TCU2_mdmBusyActive m15 : 32|32@1+ (1,0) [0|4294967294] "" Vector__XXX
 SG_ TCU2_modemUptime m16 : 32|32@1+ (1,0) [0|4294967295] "" Vector__XXX
 SG_ TCU2_mdmDataRat m17 : 32|3@1+ (1,0) [0|7] "" Vector__XXX
 SG_ TCU2_mdmDataCallStatus m18 : 32|3@1+ (1,0) [0|7] "" Vector__XXX
 SG_ TCU2_mdmNSAAvailable m19 : 32|2@1+ (1,0) [0|3] "" Vector__XXX
 SG_ TCU2_mdmPCIID m20 : 32|32@1+ (1,0) [0|4294967295] "" Vector__XXX
 SG_ TCU2_mdmMnc m21 : 32|32@1+ (1,0) [0|4294967295] "" Vector__XXX
 SG_ TCU2_mdmMcc m22 : 32|32@1+ (1,0) [0|4294967295] "" Vector__XXX
 SG_ TCU2_mdmTxKiloBytes m23 : 32|32@1+ (1,0) [0|4294967295] "KB" Vector__XXX
 SG_ TCU2_mdmDataCallTermReason m24 : 32|32@1+ (1,0) [0|4294967295] "" Vector__XXX
 SG_ TCU2_mdmDataCallTermCode m25 : 32|32@1+ (1,0) [0|4294967295] "" Vector__XXX
 SG_ TCU2_cellularSMState m26 : 32|32@1+ (1,0) [0|4294967295] "" Vector__XXX
 SG_ TCU2_tcuSMState m27 : 32|32@1+ (1,0) [0|4294967295] "" Vector__XXX
 SG_ TCU2_checkInternetFailCount m28 : 32|32@1+ (1,0) [0|4294967295] "" Vector__XXX
 SG_ TCU2_mdmBand m29 : 32|32@1+ (1,0) [0|4294967295] "" Vector__XXX
 SG_ TCU2_wakeSource m30 : 32|2@1+ (1,0) [0|3] "" Vector__XXX

BO_ 1159 TCU_SleepConfig: 1 TCU
 SG_ TCU_tc10Version : 0|2@1+ (1,0) [1|3] "" Vector__XXX

BO_ 1157 TCU_alertLog: 8 TCU
 SG_ TCU_alertID M : 0|5@1+ (1,0) [0|31] "" Vector__XXX
 SG_ TCU_alertState : 15|1@1+ (1,0) [0|1] "" Vector__XXX
 SG_ TCU_w001_FailCode m1 : 16|32@1+ (1,0) [0|4294967295] "" Vector__XXX
 SG_ TCU_w002_RejCause m2 : 16|32@1+ (1,0) [0|4294967295] "" Vector__XXX
 SG_ TCU_w003_CallFailCode m3 : 16|32@1+ (1,0) [0|4294967295] "" Vector__XXX
 SG_ TCU_w004_MSDFailCode m4 : 16|32@1+ (1,0) [0|4294967295] "" Vector__XXX
 SG_ TCU_w006_Count m6 : 16|32@1+ (1,0) [0|4294967295] "" Vector__XXX
 SG_ TCU_w007_Count m7 : 16|32@1+ (1,0) [0|4294967295] "" Vector__XXX
 SG_ TCU_w009_CrashCode m9 : 16|32@1+ (1,0) [0|4294967295] "" Vector__XXX
 SG_ TCU_w012_DataRAT m12 : 16|4@1+ (1,0) [0|15] "" Vector__XXX
 SG_ TCU_w012_RSRP m12 : 20|8@1- (1,0) [-128|127] "dBm" Vector__XXX
 SG_ TCU_w012_RSRQ m12 : 28|7@1- (1,0) [-64|63] "dBm" Vector__XXX
 SG_ TCU_w012_MNC m12 : 45|10@1+ (1,0) [0|1023] "" Vector__XXX
 SG_ TCU_w012_AvgQueueUsage m12 : 55|7@1+ (1,0) [0|127] "%" Vector__XXX
 SG_ TCU_w012_NSAAvailable m12 : 62|2@1+ (1,0) [0|3] "" Vector__XXX
 SG_ TCU_w013_DataRAT m13 : 16|4@1+ (1,0) [0|15] "" Vector__XXX
 SG_ TCU_w013_RSRP m13 : 20|8@1- (1,0) [-128|127] "dBm" Vector__XXX
 SG_ TCU_w013_RSRQ m13 : 28|7@1- (1,0) [-64|63] "dBm" Vector__XXX
 SG_ TCU_w013_MNC m13 : 45|10@1+ (1,0) [0|1023] "" Vector__XXX
 SG_ TCU_w013_AvgQueueUsage m13 : 55|7@1+ (1,0) [0|127] "%" Vector__XXX
 SG_ TCU_w013_NSAAvailable m13 : 62|2@1+ (1,0) [0|3] "" Vector__XXX
 SG_ TCU_w014_Reason m14 : 16|32@1- (1,0) [-2147483648|2147483647] "" Vector__XXX

BO_ 1158 TCU_alertMatrix1: 8 TCU
 SG_ TCU_w001_IMSRegistrationFailed : 0|1@1+ (1,0) [0|1] "" Vector__XXX
 SG_ TCU_w002_CellRegRejected : 1|1@1+ (1,0) [0|1] "" Vector__XXX
 SG_ TCU_w003_ECallFailed : 2|1@1+ (1,0) [0|1] "" Vector__XXX
 SG_ TCU_w004_MSDTransmissionFailed : 3|1@1+ (1,0) [0|1] "" Vector__XXX
 SG_ TCU_w005_SIMSlotError : 4|1@1+ (1,0) [0|1] "" Vector__XXX
 SG_ TCU_w006_MpssUnavailable : 5|1@1+ (1,0) [0|1] "" Vector__XXX
 SG_ TCU_w007_ModemUnreachable : 6|1@1+ (1,0) [0|1] "" Vector__XXX
 SG_ TCU_w008_KernelPanic : 7|1@1+ (1,0) [0|1] "" Vector__XXX
 SG_ TCU_w009_WifiFirmwareCrash : 8|1@1+ (1,0) [0|1] "" Vector__XXX
 SG_ TCU_w010_WifiDumpDetected : 9|1@1+ (1,0) [0|1] "" Vector__XXX
 SG_ TCU_w011_CellDumpDetected : 10|1@1+ (1,0) [0|1] "" Vector__XXX
 SG_ TCU_w012_UplinkDegraded : 11|1@1+ (1,0) [0|1] "" Vector__XXX
 SG_ TCU_w013_UplinkQueueFull : 12|1@1+ (1,0) [0|1] "" Vector__XXX
 SG_ TCU_w014_HostapdCrash : 13|1@1+ (1,0) [0|1] "" Vector__XXX
 SG_ TCU_w015_NPNSubscriptionActive : 14|1@1+ (1,0) [0|1] "" Vector__XXX
 SG_ TCU_w016_IMEIMismatch : 15|1@1+ (1,0) [0|1] "" Vector__XXX

BO_ 1155 TCU_log: 8 TCU
 SG_ TCU_logMux M : 0|32@1+ (1,0) [0|4294967295] "" Vector__XXX
 SG_ TCU_cpuTemp m0 : 32|32@1+ (1,0) [0|4294967295] "C" Vector__XXX
 SG_ TCU_cpuUsage m1 : 32|32@1+ (1,0) [0|4294967295] "%" Vector__XXX
 SG_ TCU_mdmCoreTemperature m2 : 32|32@1+ (1,0) [0|4294967295] "C" Vector__XXX
 SG_ TCU_availableMemory m3 : 32|32@1+ (1,0) [0|4294967295] "KB" Vector__XXX
 SG_ TCU_pwm m4 : 32|32@1+ (1,0) [0|4294967295] "" Vector__XXX
 SG_ TCU_pwmcap m5 : 32|32@1+ (1,0) [0|4294967295] "" Vector__XXX
 SG_ TCU_totalResumes m6 : 32|32@1+ (1,0) [0|4294967295] "" Vector__XXX
 SG_ TCU_mdmUplinkQueueSize m7 : 32|32@1+ (1,0) [0|4294967295] "bytes" Vector__XXX
 SG_ TCU_mdmRSRP m8 : 32|32@1- (1,0) [-2147483648|2147483647] "dBm" Vector__XXX
 SG_ TCU_mdmSINR m9 : 32|32@1- (1,0) [-2147483648|2147483647] "dBm" Vector__XXX
 SG_ TCU_mdmUplinkAllowedRate m10 : 32|32@1+ (1,0) [0|4294967295] "Kbps" Vector__XXX
 SG_ TCU_mdmUplinkAvgRate m11 : 32|32@1+ (1,0) [0|4294967295] "Kbps" Vector__XXX
 SG_ TCU_mdmServiceState m12 : 32|32@1+ (1,0) [0|4294967295] "" Vector__XXX
 SG_ TCU_mdmIMSStatus m13 : 32|32@1+ (1,0) [0|4294967295] "" Vector__XXX
 SG_ TCU_mdmSIMStatus m14 : 32|32@1+ (1,0) [0|4294967295] "" Vector__XXX
 SG_ TCU_mdmBusyActive m15 : 32|32@1+ (1,0) [0|4294967294] "" Vector__XXX
 SG_ TCU_modemUptime m16 : 32|32@1+ (1,0) [0|4294967295] "" Vector__XXX
 SG_ TCU_mdmDataRat m17 : 32|3@1+ (1,0) [0|7] "" Vector__XXX
 SG_ TCU_mdmDataCallStatus m18 : 32|3@1+ (1,0) [0|7] "" Vector__XXX
 SG_ TCU_mdmNSAAvailable m19 : 32|2@1+ (1,0) [0|3] "" Vector__XXX
 SG_ TCU_mdmPCIID m20 : 32|32@1+ (1,0) [0|4294967295] "" Vector__XXX
 SG_ TCU_mdmMnc m21 : 32|32@1+ (1,0) [0|4294967295] "" Vector__XXX
 SG_ TCU_mdmMcc m22 : 32|32@1+ (1,0) [0|4294967295] "" Vector__XXX
 SG_ TCU_mdmTxKiloBytes m23 : 32|32@1+ (1,0) [0|4294967295] "KB" Vector__XXX
 SG_ TCU_mdmDataCallTermReason m24 : 32|32@1+ (1,0) [0|4294967295] "" Vector__XXX
 SG_ TCU_mdmDataCallTermCode m25 : 32|32@1+ (1,0) [0|4294967295] "" Vector__XXX
 SG_ TCU_cellularSMState m26 : 32|32@1+ (1,0) [0|4294967295] "" Vector__XXX
 SG_ TCU_tcuSMState m27 : 32|32@1+ (1,0) [0|4294967295] "" Vector__XXX
 SG_ TCU_checkInternetFailCount m28 : 32|32@1+ (1,0) [0|4294967295] "" Vector__XXX
 SG_ TCU_mdmBand m29 : 32|32@1+ (1,0) [0|4294967295] "" Vector__XXX
 SG_ TCU_wakeSource m30 : 32|2@1+ (1,0) [0|3] "" Vector__XXX

BO_ 1603 UDS_ocs1pRequest: 8 UDS
 SG_ UDS_ocs1pRequestData : 7|64@0+ (1,0) [0|1.84467440737e+19] "" Vector__XXX

BO_ 1551 UDS_thcRequest: 8 UDS
 SG_ UDS_thcRequestData_H : 7|32@0+ (1,0) [0|4294967295] "" Vector__XXX
 SG_ UDS_thcRequestData_L : 39|32@0+ (1,0) [0|4294967295] "" Vector__XXX

BO_TX_BU_ 881 : RCM;
BO_TX_BU_ 1471 : RCU;
BO_TX_BU_ 998 : RCU;
BO_TX_BU_ 831 : RCU;
BO_TX_BU_ 1415 : TCU2;
BO_TX_BU_ 1413 : TCU2;
BO_TX_BU_ 1414 : TCU2;
BO_TX_BU_ 1412 : TCU2;
BO_TX_BU_ 1159 : TCU;
BO_TX_BU_ 1157 : TCU;
BO_TX_BU_ 1158 : TCU;
BO_TX_BU_ 1155 : TCU;
BO_TX_BU_ 1603 : UDS;
BO_TX_BU_ 1551 : UDS;
CM_ SG_ 1297 RCM_a073_eventFactoryMode "Restraint control module: a073 event factory mode";
CM_ SG_ 1297 RCM_a073_eventDiagEnabled "Restraint control module: a073 event diag enabled";
CM_ SG_ 1297 RCM_a073_eventDriveOrientation "Restraint control module: a073 event drive orientation";
CM_ SG_ 1297 RCM_a073_comChassisCANPH4MIA "Restraint control module: a073 com chassis CANPH4 MIA";
CM_ SG_ 1297 RCM_a073_comChassisCANPH4ChkSm "Restraint control module: a073 com chassis CANPH4 chk sm";
CM_ SG_ 1297 RCM_a073_comChassisCANPH4Cntr "Restraint control module: a073 com chassis CANPH4 cntr";
CM_ SG_ 1297 RCM_a073_eventIDFsignal "Restraint control module: a073 event ID fsignal";
CM_ SG_ 1297 RCM_a073_eventFrontLeftSeatbelt "Restraint control module: a073 event front left seatbelt";
CM_ SG_ 1297 RCM_a073_eventFrontRightSeatbelt "Restraint control module: a073 event front right seatbelt";
CM_ SG_ 1297 RCM_a073_eventVehicleSpeed "Restraint control module: a073 event vehicle speed";
CM_ SG_ 1297 RCM_a073_eventSteeringAngle "Restraint control module: a073 event steering angle";
CM_ SG_ 1297 RCM_a073_eventDriverBrakeApply "Restraint control module: a073 event driver brake apply; raw 3 = signal not available (SNA)";
CM_ SG_ 1297 RCM_a073_eventAccelPedalPos "Restraint control module: a073 event accel pedal pos; raw 255 = signal not available (SNA)";
CM_ SG_ 1297 RCM_a074_eventArmStatus "Restraint control module: a074 event arm status";
CM_ SG_ 1297 RCM_a074_eventFactoryMode "Restraint control module: a074 event factory mode";
CM_ SG_ 1297 RCM_a074_eventDiagEnabled "Restraint control module: a074 event diag enabled";
CM_ SG_ 1297 RCM_a074_eventDriveOrientation "Restraint control module: a074 event drive orientation";
CM_ SG_ 1297 RCM_a074_comChassisCANPH5MIA "Restraint control module: a074 com chassis CANPH5 MIA";
CM_ SG_ 1297 RCM_a074_comChassisCANPH5ChkSm "Restraint control module: a074 com chassis CANPH5 chk sm";
CM_ SG_ 1297 RCM_a074_comChassisCANPH5Cntr "Restraint control module: a074 com chassis CANPH5 cntr";
CM_ SG_ 1297 RCM_a074_eventIDFsignal "Restraint control module: a074 event ID fsignal";
CM_ SG_ 1297 RCM_a074_eventFrontLeftSeatbelt "Restraint control module: a074 event front left seatbelt";
CM_ SG_ 1297 RCM_a074_eventFrontRightSeatbelt "Restraint control module: a074 event front right seatbelt";
CM_ SG_ 1297 RCM_a074_eventVehicleSpeed "Restraint control module: a074 event vehicle speed";
CM_ SG_ 1297 RCM_a074_eventSteeringAngle "Restraint control module: a074 event steering angle";
CM_ SG_ 1297 RCM_a074_eventDriverBrakeApply "Restraint control module: a074 event driver brake apply; raw 3 = signal not available (SNA)";
CM_ SG_ 1297 RCM_a074_eventAccelPedalPos "Restraint control module: a074 event accel pedal pos; raw 255 = signal not available (SNA)";
CM_ SG_ 1297 RCM_a075_eventArmStatus "Restraint control module: a075 event arm status";
CM_ SG_ 1297 RCM_a075_eventFactoryMode "Restraint control module: a075 event factory mode";
CM_ SG_ 1297 RCM_a075_eventDiagEnabled "Restraint control module: a075 event diag enabled";
CM_ SG_ 1297 RCM_a075_eventDriveOrientation "Restraint control module: a075 event drive orientation";
CM_ SG_ 1297 RCM_a075_comChassisCANPH6MIA "Restraint control module: a075 com chassis CANPH6 MIA";
CM_ SG_ 1297 RCM_a075_comChassisCANPH6ChkSm "Restraint control module: a075 com chassis CANPH6 chk sm";
CM_ SG_ 1297 RCM_a075_comChassisCANPH6Cntr "Restraint control module: a075 com chassis CANPH6 cntr";
CM_ SG_ 1297 RCM_a075_eventIDFsignal "Restraint control module: a075 event ID fsignal";
CM_ SG_ 1297 RCM_a075_eventFrontLeftSeatbelt "Restraint control module: a075 event front left seatbelt";
CM_ SG_ 1297 RCM_a075_eventFrontRightSeatbelt "Restraint control module: a075 event front right seatbelt";
CM_ SG_ 1297 RCM_a075_eventVehicleSpeed "Restraint control module: a075 event vehicle speed";
CM_ SG_ 1297 RCM_a075_eventSteeringAngle "Restraint control module: a075 event steering angle";
CM_ SG_ 1297 RCM_a075_eventDriverBrakeApply "Restraint control module: a075 event driver brake apply; raw 3 = signal not available (SNA)";
CM_ SG_ 1297 RCM_a075_eventAccelPedalPos "Restraint control module: a075 event accel pedal pos; raw 255 = signal not available (SNA)";
CM_ SG_ 1297 RCM_a078_eventArmStatus "Restraint control module: a078 event arm status";
CM_ SG_ 1297 RCM_a078_eventFactoryMode "Restraint control module: a078 event factory mode";
CM_ SG_ 1297 RCM_a078_eventDiagEnabled "Restraint control module: a078 event diag enabled";
CM_ SG_ 1297 RCM_a078_eventDriveOrientation "Restraint control module: a078 event drive orientation";
CM_ SG_ 1297 RCM_a078_comOCS1PMIA "Restraint control module: a078 com OCS1 PMIA";
CM_ SG_ 1297 RCM_a078_comOCS1PChkSm "Restraint control module: a078 com OCS1 p chk sm";
CM_ SG_ 1297 RCM_a078_comOCS1PCntr "Restraint control module: a078 com OCS1 p cntr";
CM_ SG_ 1297 RCM_a078_eventIDFsignal "Restraint control module: a078 event ID fsignal";
CM_ SG_ 1297 RCM_a078_eventFrontLeftSeatbelt "Restraint control module: a078 event front left seatbelt";
CM_ SG_ 1297 RCM_a078_eventFrontRightSeatbelt "Restraint control module: a078 event front right seatbelt";
CM_ SG_ 1297 RCM_a078_eventVehicleSpeed "Restraint control module: a078 event vehicle speed";
CM_ SG_ 1297 RCM_a078_eventSteeringAngle "Restraint control module: a078 event steering angle";
CM_ SG_ 1297 RCM_a078_eventDriverBrakeApply "Restraint control module: a078 event driver brake apply; raw 3 = signal not available (SNA)";
CM_ SG_ 1297 RCM_a078_eventAccelPedalPos "Restraint control module: a078 event accel pedal pos; raw 255 = signal not available (SNA)";
CM_ SG_ 1297 RCM_a079_eventArmStatus "Restraint control module: a079 event arm status";
CM_ SG_ 1297 RCM_a079_eventFactoryMode "Restraint control module: a079 event factory mode";
CM_ SG_ 1297 RCM_a079_eventDiagEnabled "Restraint control module: a079 event diag enabled";
CM_ SG_ 1297 RCM_a079_eventDriveOrientation "Restraint control module: a079 event drive orientation";
CM_ SG_ 1297 RCM_a079_comOCS1DMIA "Restraint control module: a079 com OCS1 DMIA";
CM_ SG_ 1297 RCM_a079_comOCS1DChkSm "Restraint control module: a079 com OCS1 d chk sm";
CM_ SG_ 1297 RCM_a079_comOCS1DCntr "Restraint control module: a079 com OCS1 d cntr";
CM_ SG_ 1297 RCM_a079_eventIDFsignal "Restraint control module: a079 event ID fsignal";
CM_ SG_ 1297 RCM_a079_eventFrontLeftSeatbelt "Restraint control module: a079 event front left seatbelt";
CM_ SG_ 1297 RCM_a079_eventFrontRightSeatbelt "Restraint control module: a079 event front right seatbelt";
CM_ SG_ 1297 RCM_a079_eventVehicleSpeed "Restraint control module: a079 event vehicle speed";
CM_ SG_ 1297 RCM_a079_eventSteeringAngle "Restraint control module: a079 event steering angle";
CM_ SG_ 1297 RCM_a079_eventDriverBrakeApply "Restraint control module: a079 event driver brake apply; raw 3 = signal not available (SNA)";
CM_ SG_ 1297 RCM_a079_eventAccelPedalPos "Restraint control module: a079 event accel pedal pos; raw 255 = signal not available (SNA)";
CM_ SG_ 1297 RCM_a080_eventArmStatus "Restraint control module: a080 event arm status";
CM_ SG_ 1297 RCM_a080_eventFactoryMode "Restraint control module: a080 event factory mode";
CM_ SG_ 1297 RCM_a080_eventDiagEnabled "Restraint control module: a080 event diag enabled";
CM_ SG_ 1297 RCM_a080_eventDriveOrientation "Restraint control module: a080 event drive orientation";
CM_ SG_ 1297 RCM_a080_comGTWACSMIA "Restraint control module: a080 com GTWACSMIA";
CM_ SG_ 1297 RCM_a080_comGTWACSChkSm "Restraint control module: a080 com GTWACS chk sm";
CM_ SG_ 1297 RCM_a080_comGTWACSCntr "Restraint control module: a080 com GTWACS cntr";
CM_ SG_ 1297 RCM_a080_eventIDFsignal "Restraint control module: a080 event ID fsignal";
CM_ SG_ 1297 RCM_a080_eventFrontLeftSeatbelt "Restraint control module: a080 event front left seatbelt";
CM_ SG_ 1297 RCM_a080_eventFrontRightSeatbelt "Restraint control module: a080 event front right seatbelt";
CM_ SG_ 1297 RCM_a080_eventVehicleSpeed "Restraint control module: a080 event vehicle speed";
CM_ SG_ 1297 RCM_a080_eventSteeringAngle "Restraint control module: a080 event steering angle";
CM_ SG_ 1297 RCM_a080_eventDriverBrakeApply "Restraint control module: a080 event driver brake apply; raw 3 = signal not available (SNA)";
CM_ SG_ 1297 RCM_a080_eventAccelPedalPos "Restraint control module: a080 event accel pedal pos; raw 255 = signal not available (SNA)";
CM_ SG_ 1297 RCM_a083_eventArmStatus "Restraint control module: a083 event arm status";
CM_ SG_ 1297 RCM_a083_eventFactoryMode "Restraint control module: a083 event factory mode";
CM_ SG_ 1297 RCM_a083_eventDiagEnabled "Restraint control module: a083 event diag enabled";
CM_ SG_ 1297 RCM_a083_eventDriveOrientation "Restraint control module: a083 event drive orientation";
CM_ SG_ 1297 RCM_a083_comGTWCarStateMIA "Restraint control module: a083 com GTW car state MIA";
CM_ SG_ 1297 RCM_a083_eventIDFsignal "Restraint control module: a083 event ID fsignal";
CM_ SG_ 1297 RCM_a083_eventFrontLeftSeatbelt "Restraint control module: a083 event front left seatbelt";
CM_ SG_ 1297 RCM_a083_eventFrontRightSeatbelt "Restraint control module: a083 event front right seatbelt";
CM_ SG_ 1297 RCM_a083_eventVehicleSpeed "Restraint control module: a083 event vehicle speed";
CM_ SG_ 1297 RCM_a083_eventSteeringAngle "Restraint control module: a083 event steering angle";
CM_ SG_ 1297 RCM_a083_eventDriverBrakeApply "Restraint control module: a083 event driver brake apply; raw 3 = signal not available (SNA)";
CM_ SG_ 1297 RCM_a083_eventAccelPedalPos "Restraint control module: a083 event accel pedal pos; raw 255 = signal not available (SNA)";
CM_ SG_ 1297 RCM_a087_eventArmStatus "Restraint control module: a087 event arm status";
CM_ SG_ 1297 RCM_a087_eventFactoryMode "Restraint control module: a087 event factory mode";
CM_ SG_ 1297 RCM_a087_eventDiagEnabled "Restraint control module: a087 event diag enabled";
CM_ SG_ 1297 RCM_a087_eventDriveOrientation "Restraint control module: a087 event drive orientation";
CM_ SG_ 1297 RCM_a087_comChassisCANSilent "Restraint control module: a087 com chassis CAN silent";
CM_ SG_ 1297 RCM_a087_comPARTYCANSilent "Restraint control module: a087 com PARTYCAN silent";
CM_ SG_ 1297 RCM_a087_comUnusedCANSilent "Restraint control module: a087 com unused CAN silent";
CM_ SG_ 1297 RCM_a087_eventIDFsignal "Restraint control module: a087 event ID fsignal";
CM_ SG_ 1297 RCM_a087_eventFrontLeftSeatbelt "Restraint control module: a087 event front left seatbelt";
CM_ SG_ 1297 RCM_a087_eventFrontRightSeatbelt "Restraint control module: a087 event front right seatbelt";
CM_ SG_ 1297 RCM_a087_eventVehicleSpeed "Restraint control module: a087 event vehicle speed";
CM_ SG_ 1297 RCM_a087_eventSteeringAngle "Restraint control module: a087 event steering angle";
CM_ SG_ 1297 RCM_a087_eventDriverBrakeApply "Restraint control module: a087 event driver brake apply; raw 3 = signal not available (SNA)";
CM_ SG_ 1297 RCM_a087_eventAccelPedalPos "Restraint control module: a087 event accel pedal pos; raw 255 = signal not available (SNA)";
CM_ SG_ 1297 RCM_a088_eventArmStatus "Restraint control module: a088 event arm status";
CM_ SG_ 1297 RCM_a088_eventFactoryMode "Restraint control module: a088 event factory mode";
CM_ SG_ 1297 RCM_a088_eventDiagEnabled "Restraint control module: a088 event diag enabled";
CM_ SG_ 1297 RCM_a088_eventDriveOrientation "Restraint control module: a088 event drive orientation";
CM_ SG_ 1297 RCM_a088_comChassisCANPH2MIA "Restraint control module: a088 com chassis CANPH2 MIA";
CM_ SG_ 1297 RCM_a088_comChassisCANPH2ChkSm "Restraint control module: a088 com chassis CANPH2 chk sm";
CM_ SG_ 1297 RCM_a088_comChassisCANPH2Cntr "Restraint control module: a088 com chassis CANPH2 cntr";
CM_ SG_ 1297 RCM_a088_eventIDFsignal "Restraint control module: a088 event ID fsignal";
CM_ SG_ 1297 RCM_a088_eventFrontLeftSeatbelt "Restraint control module: a088 event front left seatbelt";
CM_ SG_ 1297 RCM_a088_eventFrontRightSeatbelt "Restraint control module: a088 event front right seatbelt";
CM_ SG_ 1297 RCM_a088_eventVehicleSpeed "Restraint control module: a088 event vehicle speed";
CM_ SG_ 1297 RCM_a088_eventSteeringAngle "Restraint control module: a088 event steering angle";
CM_ SG_ 1297 RCM_a088_eventDriverBrakeApply "Restraint control module: a088 event driver brake apply; raw 3 = signal not available (SNA)";
CM_ SG_ 1297 RCM_a088_eventAccelPedalPos "Restraint control module: a088 event accel pedal pos; raw 255 = signal not available (SNA)";
CM_ SG_ 1297 RCM_a089_eventArmStatus "Restraint control module: a089 event arm status";
CM_ SG_ 1297 RCM_a089_eventFactoryMode "Restraint control module: a089 event factory mode";
CM_ SG_ 1297 RCM_a089_eventDiagEnabled "Restraint control module: a089 event diag enabled";
CM_ SG_ 1297 RCM_a089_eventDriveOrientation "Restraint control module: a089 event drive orientation";
CM_ SG_ 1297 RCM_a089_comChassisCANPH3MIA "Restraint control module: a089 com chassis CANPH3 MIA";
CM_ SG_ 1297 RCM_a089_comChassisCANPH3ChkSm "Restraint control module: a089 com chassis CANPH3 chk sm";
CM_ SG_ 1297 RCM_a089_comChassisCANPH3Cntr "Restraint control module: a089 com chassis CANPH3 cntr";
CM_ SG_ 1297 RCM_a089_eventIDFsignal "Restraint control module: a089 event ID fsignal";
CM_ SG_ 1297 RCM_a089_eventFrontLeftSeatbelt "Restraint control module: a089 event front left seatbelt";
CM_ SG_ 1297 RCM_a089_eventFrontRightSeatbelt "Restraint control module: a089 event front right seatbelt";
CM_ SG_ 1297 RCM_a089_eventVehicleSpeed "Restraint control module: a089 event vehicle speed";
CM_ SG_ 1297 RCM_a089_eventSteeringAngle "Restraint control module: a089 event steering angle";
CM_ SG_ 1297 RCM_a089_eventDriverBrakeApply "Restraint control module: a089 event driver brake apply; raw 3 = signal not available (SNA)";
CM_ SG_ 1297 RCM_a089_eventAccelPedalPos "Restraint control module: a089 event accel pedal pos; raw 255 = signal not available (SNA)";
CM_ SG_ 1297 RCM_a090_eventArmStatus "Restraint control module: a090 event arm status";
CM_ SG_ 1297 RCM_a090_eventFactoryMode "Restraint control module: a090 event factory mode";
CM_ SG_ 1297 RCM_a090_eventDiagEnabled "Restraint control module: a090 event diag enabled";
CM_ SG_ 1297 RCM_a090_eventDriveOrientation "Restraint control module: a090 event drive orientation";
CM_ SG_ 1297 RCM_a090_comPartyCANBusOff "Restraint control module: a090 com party CAN bus off";
CM_ SG_ 1297 RCM_a090_eventIDFsignal "Restraint control module: a090 event ID fsignal";
CM_ SG_ 1297 RCM_a090_eventFrontLeftSeatbelt "Restraint control module: a090 event front left seatbelt";
CM_ SG_ 1297 RCM_a090_eventFrontRightSeatbelt "Restraint control module: a090 event front right seatbelt";
CM_ SG_ 1297 RCM_a090_eventVehicleSpeed "Restraint control module: a090 event vehicle speed";
CM_ SG_ 1297 RCM_a090_eventSteeringAngle "Restraint control module: a090 event steering angle";
CM_ SG_ 1297 RCM_a090_eventDriverBrakeApply "Restraint control module: a090 event driver brake apply; raw 3 = signal not available (SNA)";
CM_ SG_ 1297 RCM_a090_eventAccelPedalPos "Restraint control module: a090 event accel pedal pos; raw 255 = signal not available (SNA)";
CM_ SG_ 1297 RCM_a092_eventArmStatus "Restraint control module: a092 event arm status";
CM_ SG_ 1297 RCM_a092_eventFactoryMode "Restraint control module: a092 event factory mode";
CM_ SG_ 1297 RCM_a092_eventDiagEnabled "Restraint control module: a092 event diag enabled";
CM_ SG_ 1297 RCM_a092_eventDriveOrientation "Restraint control module: a092 event drive orientation";
CM_ SG_ 1297 RCM_a092_comDASSafetyFrontMIA "Restraint control module: a092 com DAS safety front MIA";
CM_ SG_ 1297 RCM_a092_comDASSafetyFrontChkSm "Restraint control module: a092 com DAS safety front chk sm";
CM_ SG_ 1297 RCM_a092_comDASSafetyFrontCntr "Restraint control module: a092 com DAS safety front cntr";
CM_ SG_ 1297 RCM_a092_eventIDFsignal "Restraint control module: a092 event ID fsignal";
CM_ SG_ 1297 RCM_a092_eventFrontLeftSeatbelt "Restraint control module: a092 event front left seatbelt";
CM_ SG_ 1297 RCM_a092_eventFrontRightSeatbelt "Restraint control module: a092 event front right seatbelt";
CM_ SG_ 1297 RCM_a092_eventVehicleSpeed "Restraint control module: a092 event vehicle speed";
CM_ SG_ 1297 RCM_a092_eventSteeringAngle "Restraint control module: a092 event steering angle";
CM_ SG_ 1297 RCM_a092_eventDriverBrakeApply "Restraint control module: a092 event driver brake apply; raw 3 = signal not available (SNA)";
CM_ SG_ 1297 RCM_a092_eventAccelPedalPos "Restraint control module: a092 event accel pedal pos; raw 255 = signal not available (SNA)";
CM_ SG_ 1297 RCM_a093_eventArmStatus "Restraint control module: a093 event arm status";
CM_ SG_ 1297 RCM_a093_eventFactoryMode "Restraint control module: a093 event factory mode";
CM_ SG_ 1297 RCM_a093_eventDiagEnabled "Restraint control module: a093 event diag enabled";
CM_ SG_ 1297 RCM_a093_eventDriveOrientation "Restraint control module: a093 event drive orientation";
CM_ SG_ 1297 RCM_a093_comVCLEFTStatusMIA "Restraint control module: a093 com VCLEFT status MIA";
CM_ SG_ 1297 RCM_a093_comVCLEFTStatusChkSm "Restraint control module: a093 com VCLEFT status chk sm";
CM_ SG_ 1297 RCM_a093_comVCLEFTStatusCntr "Restraint control module: a093 com VCLEFT status cntr";
CM_ SG_ 1297 RCM_a093_bucklSwVCFrontLeftFault "Restraint control module: a093 buckl sw VC front left fault";
CM_ SG_ 1297 RCM_a093_bucklSwVCRearLeftFault "Restraint control module: a093 buckl sw VC rear left fault";
CM_ SG_ 1297 RCM_a093_eventIDFsignal "Restraint control module: a093 event ID fsignal";
CM_ SG_ 1297 RCM_a093_eventFrontLeftSeatbelt "Restraint control module: a093 event front left seatbelt";
CM_ SG_ 1297 RCM_a093_eventFrontRightSeatbelt "Restraint control module: a093 event front right seatbelt";
CM_ SG_ 1297 RCM_a093_eventVehicleSpeed "Restraint control module: a093 event vehicle speed";
CM_ SG_ 1297 RCM_a093_eventSteeringAngle "Restraint control module: a093 event steering angle";
CM_ SG_ 1297 RCM_a093_eventDriverBrakeApply "Restraint control module: a093 event driver brake apply; raw 3 = signal not available (SNA)";
CM_ SG_ 1297 RCM_a093_eventAccelPedalPos "Restraint control module: a093 event accel pedal pos; raw 255 = signal not available (SNA)";
CM_ SG_ 1297 RCM_a094_eventArmStatus "Restraint control module: a094 event arm status";
CM_ SG_ 1297 RCM_a094_eventFactoryMode "Restraint control module: a094 event factory mode";
CM_ SG_ 1297 RCM_a094_eventDiagEnabled "Restraint control module: a094 event diag enabled";
CM_ SG_ 1297 RCM_a094_eventDriveOrientation "Restraint control module: a094 event drive orientation";
CM_ SG_ 1297 RCM_a094_comVCRIGHTStatusMIA "Restraint control module: a094 com VCRIGHT status MIA";
CM_ SG_ 1297 RCM_a094_comVCRIGHTStatusChkSm "Restraint control module: a094 com VCRIGHT status chk sm";
CM_ SG_ 1297 RCM_a094_comVCRIGHTStatusCntr "Restraint control module: a094 com VCRIGHT status cntr";
CM_ SG_ 1297 RCM_a094_bucklSwVCFrontRghtFault "Restraint control module: a094 buckl sw VC front rght fault";
CM_ SG_ 1297 RCM_a094_bucklSwVCRearRghtFault "Restraint control module: a094 buckl sw VC rear rght fault";
CM_ SG_ 1297 RCM_a094_bucklSwVCRearCnterFault "Restraint control module: a094 buckl sw VC rear cnter fault";
CM_ SG_ 1297 RCM_a094_eventIDFsignal "Restraint control module: a094 event ID fsignal";
CM_ SG_ 1297 RCM_a094_eventFrontLeftSeatbelt "Restraint control module: a094 event front left seatbelt";
CM_ SG_ 1297 RCM_a094_eventFrontRightSeatbelt "Restraint control module: a094 event front right seatbelt";
CM_ SG_ 1297 RCM_a094_eventVehicleSpeed "Restraint control module: a094 event vehicle speed";
CM_ SG_ 1297 RCM_a094_eventSteeringAngle "Restraint control module: a094 event steering angle";
CM_ SG_ 1297 RCM_a094_eventDriverBrakeApply "Restraint control module: a094 event driver brake apply; raw 3 = signal not available (SNA)";
CM_ SG_ 1297 RCM_a094_eventAccelPedalPos "Restraint control module: a094 event accel pedal pos; raw 255 = signal not available (SNA)";
CM_ SG_ 1297 RCM_a101_eventArmStatus "Restraint control module: a101 event arm status";
CM_ SG_ 1297 RCM_a101_eventFactoryMode "Restraint control module: a101 event factory mode";
CM_ SG_ 1297 RCM_a101_eventDiagEnabled "Restraint control module: a101 event diag enabled";
CM_ SG_ 1297 RCM_a101_eventDriveOrientation "Restraint control module: a101 event drive orientation";
CM_ SG_ 1297 RCM_a101_idfMisuseMonitoringErr "Restraint control module: a101 idf misuse monitoring err";
CM_ SG_ 1297 RCM_a101_idfEnviMonitoringError "Restraint control module: a101 idf envi monitoring error";
CM_ SG_ 1297 RCM_a101_idfEnviMonitoringEvent "Restraint control module: a101 idf envi monitoring event";
CM_ SG_ 1297 RCM_a101_eventIDFsignal "Restraint control module: a101 event ID fsignal";
CM_ SG_ 1297 RCM_a101_eventFrontLeftSeatbelt "Restraint control module: a101 event front left seatbelt";
CM_ SG_ 1297 RCM_a101_eventFrontRightSeatbelt "Restraint control module: a101 event front right seatbelt";
CM_ SG_ 1297 RCM_a101_eventVehicleSpeed "Restraint control module: a101 event vehicle speed";
CM_ SG_ 1297 RCM_a101_eventSteeringAngle "Restraint control module: a101 event steering angle";
CM_ SG_ 1297 RCM_a101_eventDriverBrakeApply "Restraint control module: a101 event driver brake apply; raw 3 = signal not available (SNA)";
CM_ SG_ 1297 RCM_a101_eventAccelPedalPos "Restraint control module: a101 event accel pedal pos; raw 255 = signal not available (SNA)";
CM_ SG_ 1297 RCM_a102_eventArmStatus "Restraint control module: a102 event arm status";
CM_ SG_ 1297 RCM_a102_eventFactoryMode "Restraint control module: a102 event factory mode";
CM_ SG_ 1297 RCM_a102_eventDiagEnabled "Restraint control module: a102 event diag enabled";
CM_ SG_ 1297 RCM_a102_eventDriveOrientation "Restraint control module: a102 event drive orientation";
CM_ SG_ 1297 RCM_a102_imuYawR8OffCompPosLife "Restraint control module: a102 imu yaw R8 off comp pos life";
CM_ SG_ 1297 RCM_a102_imuYawR8OffCompNegLife "Restraint control module: a102 imu yaw R8 off comp neg life";
CM_ SG_ 1297 RCM_a102_imuYawR8OffCompPosFLDC "Restraint control module: a102 imu yaw R8 off comp pos FLDC";
CM_ SG_ 1297 RCM_a102_imuYawR8OffCompNegFLDC "Restraint control module: a102 imu yaw R8 off comp neg FLDC";
CM_ SG_ 1297 RCM_a102_imuYawR8OffCompPosSLDC "Restraint control module: a102 imu yaw R8 off comp pos SLDC";
CM_ SG_ 1297 RCM_a102_imuYawR8OffCompNegSLDC "Restraint control module: a102 imu yaw R8 off comp neg SLDC";
CM_ SG_ 1297 RCM_a102_eventIDFsignal "Restraint control module: a102 event ID fsignal";
CM_ SG_ 1297 RCM_a102_eventFrontLeftSeatbelt "Restraint control module: a102 event front left seatbelt";
CM_ SG_ 1297 RCM_a102_eventFrontRightSeatbelt "Restraint control module: a102 event front right seatbelt";
CM_ SG_ 1297 RCM_a102_eventVehicleSpeed "Restraint control module: a102 event vehicle speed";
CM_ SG_ 1297 RCM_a102_eventSteeringAngle "Restraint control module: a102 event steering angle";
CM_ SG_ 1297 RCM_a102_eventDriverBrakeApply "Restraint control module: a102 event driver brake apply; raw 3 = signal not available (SNA)";
CM_ SG_ 1297 RCM_a102_eventAccelPedalPos "Restraint control module: a102 event accel pedal pos; raw 255 = signal not available (SNA)";
CM_ SG_ 1297 RCM_a103_eventArmStatus "Restraint control module: a103 event arm status";
CM_ SG_ 1297 RCM_a103_eventFactoryMode "Restraint control module: a103 event factory mode";
CM_ SG_ 1297 RCM_a103_eventDiagEnabled "Restraint control module: a103 event diag enabled";
CM_ SG_ 1297 RCM_a103_eventDriveOrientation "Restraint control module: a103 event drive orientation";
CM_ SG_ 1297 RCM_a103_imuPtchR8OffCompPosLife "Restraint control module: a103 imu ptch R8 off comp pos life";
CM_ SG_ 1297 RCM_a103_imuPtchR8OffCompNegLife "Restraint control module: a103 imu ptch R8 off comp neg life";
CM_ SG_ 1297 RCM_a103_imuPtchR8OffCompPosFLDC "Restraint control module: a103 imu ptch R8 off comp pos FLDC";
CM_ SG_ 1297 RCM_a103_imuPtchR8OffCompNegFLDC "Restraint control module: a103 imu ptch R8 off comp neg FLDC";
CM_ SG_ 1297 RCM_a103_imuPtchR8OffCompPosSLDC "Restraint control module: a103 imu ptch R8 off comp pos SLDC";
CM_ SG_ 1297 RCM_a103_imuPtchR8OffCompNegSLDC "Restraint control module: a103 imu ptch R8 off comp neg SLDC";
CM_ SG_ 1297 RCM_a103_eventIDFsignal "Restraint control module: a103 event ID fsignal";
CM_ SG_ 1297 RCM_a103_eventFrontLeftSeatbelt "Restraint control module: a103 event front left seatbelt";
CM_ SG_ 1297 RCM_a103_eventFrontRightSeatbelt "Restraint control module: a103 event front right seatbelt";
CM_ SG_ 1297 RCM_a103_eventVehicleSpeed "Restraint control module: a103 event vehicle speed";
CM_ SG_ 1297 RCM_a103_eventSteeringAngle "Restraint control module: a103 event steering angle";
CM_ SG_ 1297 RCM_a103_eventDriverBrakeApply "Restraint control module: a103 event driver brake apply; raw 3 = signal not available (SNA)";
CM_ SG_ 1297 RCM_a103_eventAccelPedalPos "Restraint control module: a103 event accel pedal pos; raw 255 = signal not available (SNA)";
CM_ SG_ 1297 RCM_a104_eventArmStatus "Restraint control module: a104 event arm status";
CM_ SG_ 1297 RCM_a104_eventFactoryMode "Restraint control module: a104 event factory mode";
CM_ SG_ 1297 RCM_a104_eventDiagEnabled "Restraint control module: a104 event diag enabled";
CM_ SG_ 1297 RCM_a104_eventDriveOrientation "Restraint control module: a104 event drive orientation";
CM_ SG_ 1297 RCM_a104_imuRollR8OffCompPosLife "Restraint control module: a104 imu roll R8 off comp pos life";
CM_ SG_ 1297 RCM_a104_imuRollR8OffCompNegLife "Restraint control module: a104 imu roll R8 off comp neg life";
CM_ SG_ 1297 RCM_a104_imuRollR8OffCompPosFLDC "Restraint control module: a104 imu roll R8 off comp pos FLDC";
CM_ SG_ 1297 RCM_a104_imuRollR8OffCompNegFLDC "Restraint control module: a104 imu roll R8 off comp neg FLDC";
CM_ SG_ 1297 RCM_a104_imuRollR8OffCompPosSLDC "Restraint control module: a104 imu roll R8 off comp pos SLDC";
CM_ SG_ 1297 RCM_a104_imuRollR8OffCompNegSLDC "Restraint control module: a104 imu roll R8 off comp neg SLDC";
CM_ SG_ 1297 RCM_a104_eventIDFsignal "Restraint control module: a104 event ID fsignal";
CM_ SG_ 1297 RCM_a104_eventFrontLeftSeatbelt "Restraint control module: a104 event front left seatbelt";
CM_ SG_ 1297 RCM_a104_eventFrontRightSeatbelt "Restraint control module: a104 event front right seatbelt";
CM_ SG_ 1297 RCM_a104_eventVehicleSpeed "Restraint control module: a104 event vehicle speed";
CM_ SG_ 1297 RCM_a104_eventSteeringAngle "Restraint control module: a104 event steering angle";
CM_ SG_ 1297 RCM_a104_eventDriverBrakeApply "Restraint control module: a104 event driver brake apply; raw 3 = signal not available (SNA)";
CM_ SG_ 1297 RCM_a104_eventAccelPedalPos "Restraint control module: a104 event accel pedal pos; raw 255 = signal not available (SNA)";
CM_ SG_ 1297 RCM_a105_eventArmStatus "Restraint control module: a105 event arm status";
CM_ SG_ 1297 RCM_a105_eventFactoryMode "Restraint control module: a105 event factory mode";
CM_ SG_ 1297 RCM_a105_eventDiagEnabled "Restraint control module: a105 event diag enabled";
CM_ SG_ 1297 RCM_a105_eventDriveOrientation "Restraint control module: a105 event drive orientation";
CM_ SG_ 1297 RCM_a105_imuLongAOffCompPosLife "Restraint control module: a105 imu long a off comp pos life";
CM_ SG_ 1297 RCM_a105_imuLongAOffCompNegLife "Restraint control module: a105 imu long a off comp neg life";
CM_ SG_ 1297 RCM_a105_imuLongAOffCompPosFLDC "Restraint control module: a105 imu long a off comp pos FLDC";
CM_ SG_ 1297 RCM_a105_imuLongAOffCompNegFLDC "Restraint control module: a105 imu long a off comp neg FLDC";
CM_ SG_ 1297 RCM_a105_imuLongAOffCompPosSLDC "Restraint control module: a105 imu long a off comp pos SLDC";
CM_ SG_ 1297 RCM_a105_imuLongAOffCompNegSLDC "Restraint control module: a105 imu long a off comp neg SLDC";
CM_ SG_ 1297 RCM_a105_eventIDFsignal "Restraint control module: a105 event ID fsignal";
CM_ SG_ 1297 RCM_a105_eventFrontLeftSeatbelt "Restraint control module: a105 event front left seatbelt";
CM_ SG_ 1297 RCM_a105_eventFrontRightSeatbelt "Restraint control module: a105 event front right seatbelt";
CM_ SG_ 1297 RCM_a105_eventVehicleSpeed "Restraint control module: a105 event vehicle speed";
CM_ SG_ 1297 RCM_a105_eventSteeringAngle "Restraint control module: a105 event steering angle";
CM_ SG_ 1297 RCM_a105_eventDriverBrakeApply "Restraint control module: a105 event driver brake apply; raw 3 = signal not available (SNA)";
CM_ SG_ 1297 RCM_a105_eventAccelPedalPos "Restraint control module: a105 event accel pedal pos; raw 255 = signal not available (SNA)";
CM_ SG_ 1297 RCM_a106_eventArmStatus "Restraint control module: a106 event arm status";
CM_ SG_ 1297 RCM_a106_eventFactoryMode "Restraint control module: a106 event factory mode";
CM_ SG_ 1297 RCM_a106_eventDiagEnabled "Restraint control module: a106 event diag enabled";
CM_ SG_ 1297 RCM_a106_eventDriveOrientation "Restraint control module: a106 event drive orientation";
CM_ SG_ 1297 RCM_a106_imuLatAcOffCompPosLife "Restraint control module: a106 imu lat ac off comp pos life";
CM_ SG_ 1297 RCM_a106_imuLatAcOffCompNegLife "Restraint control module: a106 imu lat ac off comp neg life";
CM_ SG_ 1297 RCM_a106_imuLatAcOffCompPosFLDC "Restraint control module: a106 imu lat ac off comp pos FLDC";
CM_ SG_ 1297 RCM_a106_imuLatAcOffCompNegFLDC "Restraint control module: a106 imu lat ac off comp neg FLDC";
CM_ SG_ 1297 RCM_a106_imuLatAcOffCompPosSLDC "Restraint control module: a106 imu lat ac off comp pos SLDC";
CM_ SG_ 1297 RCM_a106_imuLatAcOffCompNegSLDC "Restraint control module: a106 imu lat ac off comp neg SLDC";
CM_ SG_ 1297 RCM_a106_eventIDFsignal "Restraint control module: a106 event ID fsignal";
CM_ SG_ 1297 RCM_a106_eventFrontLeftSeatbelt "Restraint control module: a106 event front left seatbelt";
CM_ SG_ 1297 RCM_a106_eventFrontRightSeatbelt "Restraint control module: a106 event front right seatbelt";
CM_ SG_ 1297 RCM_a106_eventVehicleSpeed "Restraint control module: a106 event vehicle speed";
CM_ SG_ 1297 RCM_a106_eventSteeringAngle "Restraint control module: a106 event steering angle";
CM_ SG_ 1297 RCM_a106_eventDriverBrakeApply "Restraint control module: a106 event driver brake apply; raw 3 = signal not available (SNA)";
CM_ SG_ 1297 RCM_a106_eventAccelPedalPos "Restraint control module: a106 event accel pedal pos; raw 255 = signal not available (SNA)";
CM_ SG_ 1297 RCM_a107_eventArmStatus "Restraint control module: a107 event arm status";
CM_ SG_ 1297 RCM_a107_eventFactoryMode "Restraint control module: a107 event factory mode";
CM_ SG_ 1297 RCM_a107_eventDiagEnabled "Restraint control module: a107 event diag enabled";
CM_ SG_ 1297 RCM_a107_eventDriveOrientation "Restraint control module: a107 event drive orientation";
CM_ SG_ 1297 RCM_a107_imuVertAOffCompPosLife "Restraint control module: a107 imu vert a off comp pos life";
CM_ SG_ 1297 RCM_a107_imuVertAOffCompNegLife "Restraint control module: a107 imu vert a off comp neg life";
CM_ SG_ 1297 RCM_a107_imuVertAOffCompPosFLDC "Restraint control module: a107 imu vert a off comp pos FLDC";
CM_ SG_ 1297 RCM_a107_imuVertAOffCompNegFLDC "Restraint control module: a107 imu vert a off comp neg FLDC";
CM_ SG_ 1297 RCM_a107_imuVertAOffCompPosSLDC "Restraint control module: a107 imu vert a off comp pos SLDC";
CM_ SG_ 1297 RCM_a107_imuVertAOffCompNegSLDC "Restraint control module: a107 imu vert a off comp neg SLDC";
CM_ SG_ 1297 RCM_a107_eventIDFsignal "Restraint control module: a107 event ID fsignal";
CM_ SG_ 1297 RCM_a107_eventFrontLeftSeatbelt "Restraint control module: a107 event front left seatbelt";
CM_ SG_ 1297 RCM_a107_eventFrontRightSeatbelt "Restraint control module: a107 event front right seatbelt";
CM_ SG_ 1297 RCM_a107_eventVehicleSpeed "Restraint control module: a107 event vehicle speed";
CM_ SG_ 1297 RCM_a107_eventSteeringAngle "Restraint control module: a107 event steering angle";
CM_ SG_ 1297 RCM_a107_eventDriverBrakeApply "Restraint control module: a107 event driver brake apply; raw 3 = signal not available (SNA)";
CM_ SG_ 1297 RCM_a107_eventAccelPedalPos "Restraint control module: a107 event accel pedal pos; raw 255 = signal not available (SNA)";
CM_ SG_ 1297 RCM_a108_eventArmStatus "Restraint control module: a108 event arm status";
CM_ SG_ 1297 RCM_a108_eventFactoryMode "Restraint control module: a108 event factory mode";
CM_ SG_ 1297 RCM_a108_eventDiagEnabled "Restraint control module: a108 event diag enabled";
CM_ SG_ 1297 RCM_a108_eventDriveOrientation "Restraint control module: a108 event drive orientation";
CM_ SG_ 1297 RCM_a108_crashAlgoWakeupSig "Restraint control module: a108 crash algo wakeup sig";
CM_ SG_ 1297 RCM_a108_eventIDFsignal "Restraint control module: a108 event ID fsignal";
CM_ SG_ 1297 RCM_a108_eventFrontLeftSeatbelt "Restraint control module: a108 event front left seatbelt";
CM_ SG_ 1297 RCM_a108_eventFrontRightSeatbelt "Restraint control module: a108 event front right seatbelt";
CM_ SG_ 1297 RCM_a108_eventVehicleSpeed "Restraint control module: a108 event vehicle speed";
CM_ SG_ 1297 RCM_a108_eventSteeringAngle "Restraint control module: a108 event steering angle";
CM_ SG_ 1297 RCM_a108_eventDriverBrakeApply "Restraint control module: a108 event driver brake apply; raw 3 = signal not available (SNA)";
CM_ SG_ 1297 RCM_a108_eventAccelPedalPos "Restraint control module: a108 event accel pedal pos; raw 255 = signal not available (SNA)";
CM_ SG_ 1297 RCM_a109_eventArmStatus "Restraint control module: a109 event arm status";
CM_ SG_ 1297 RCM_a109_eventFactoryMode "Restraint control module: a109 event factory mode";
CM_ SG_ 1297 RCM_a109_eventDiagEnabled "Restraint control module: a109 event diag enabled";
CM_ SG_ 1297 RCM_a109_eventDriveOrientation "Restraint control module: a109 event drive orientation";
CM_ SG_ 1297 RCM_a109_immunityThrsholdCrossed "Restraint control module: a109 immunity thrshold crossed";
CM_ SG_ 1297 RCM_a109_eventIDFsignal "Restraint control module: a109 event ID fsignal";
CM_ SG_ 1297 RCM_a109_eventFrontLeftSeatbelt "Restraint control module: a109 event front left seatbelt";
CM_ SG_ 1297 RCM_a109_eventFrontRightSeatbelt "Restraint control module: a109 event front right seatbelt";
CM_ SG_ 1297 RCM_a109_eventVehicleSpeed "Restraint control module: a109 event vehicle speed";
CM_ SG_ 1297 RCM_a109_eventSteeringAngle "Restraint control module: a109 event steering angle";
CM_ SG_ 1297 RCM_a109_eventDriverBrakeApply "Restraint control module: a109 event driver brake apply; raw 3 = signal not available (SNA)";
CM_ SG_ 1297 RCM_a109_eventAccelPedalPos "Restraint control module: a109 event accel pedal pos; raw 255 = signal not available (SNA)";
CM_ SG_ 1297 RCM_a110_eventArmStatus "Restraint control module: a110 event arm status";
CM_ SG_ 1297 RCM_a110_eventFactoryMode "Restraint control module: a110 event factory mode";
CM_ SG_ 1297 RCM_a110_eventDiagEnabled "Restraint control module: a110 event diag enabled";
CM_ SG_ 1297 RCM_a110_eventDriveOrientation "Restraint control module: a110 event drive orientation";
CM_ SG_ 1297 RCM_a110_inFactoryMode "Restraint control module: a110 in factory mode";
CM_ SG_ 1297 RCM_a110_eventIDFsignal "Restraint control module: a110 event ID fsignal";
CM_ SG_ 1297 RCM_a110_eventFrontLeftSeatbelt "Restraint control module: a110 event front left seatbelt";
CM_ SG_ 1297 RCM_a110_eventFrontRightSeatbelt "Restraint control module: a110 event front right seatbelt";
CM_ SG_ 1297 RCM_a110_eventVehicleSpeed "Restraint control module: a110 event vehicle speed";
CM_ SG_ 1297 RCM_a110_eventSteeringAngle "Restraint control module: a110 event steering angle";
CM_ SG_ 1297 RCM_a110_eventDriverBrakeApply "Restraint control module: a110 event driver brake apply; raw 3 = signal not available (SNA)";
CM_ SG_ 1297 RCM_a110_eventAccelPedalPos "Restraint control module: a110 event accel pedal pos; raw 255 = signal not available (SNA)";
CM_ SG_ 1297 RCM_a112_eventArmStatus "Restraint control module: a112 event arm status";
CM_ SG_ 1297 RCM_a112_eventFactoryMode "Restraint control module: a112 event factory mode";
CM_ SG_ 1297 RCM_a112_eventDiagEnabled "Restraint control module: a112 event diag enabled";
CM_ SG_ 1297 RCM_a112_eventDriveOrientation "Restraint control module: a112 event drive orientation";
CM_ SG_ 1297 RCM_a112_imuYawR8SnsrMonitTmp "Restraint control module: a112 imu yaw R8 snsr monit tmp";
CM_ SG_ 1297 RCM_a112_imuYawR8SnsrMonitPerm "Restraint control module: a112 imu yaw R8 snsr monit perm";
CM_ SG_ 1297 RCM_a112_imuYawR8ChnlMonitTmp "Restraint control module: a112 imu yaw R8 chnl monit tmp";
CM_ SG_ 1297 RCM_a112_imuYawR8ChnlMonitPerm "Restraint control module: a112 imu yaw R8 chnl monit perm";
CM_ SG_ 1297 RCM_a112_eventIDFsignal "Restraint control module: a112 event ID fsignal";
CM_ SG_ 1297 RCM_a112_eventFrontLeftSeatbelt "Restraint control module: a112 event front left seatbelt";
CM_ SG_ 1297 RCM_a112_eventFrontRightSeatbelt "Restraint control module: a112 event front right seatbelt";
CM_ SG_ 1297 RCM_a112_eventVehicleSpeed "Restraint control module: a112 event vehicle speed";
CM_ SG_ 1297 RCM_a112_eventSteeringAngle "Restraint control module: a112 event steering angle";
CM_ SG_ 1297 RCM_a112_eventDriverBrakeApply "Restraint control module: a112 event driver brake apply; raw 3 = signal not available (SNA)";
CM_ SG_ 1297 RCM_a112_eventAccelPedalPos "Restraint control module: a112 event accel pedal pos; raw 255 = signal not available (SNA)";
CM_ SG_ 1297 RCM_a113_eventArmStatus "Restraint control module: a113 event arm status";
CM_ SG_ 1297 RCM_a113_eventFactoryMode "Restraint control module: a113 event factory mode";
CM_ SG_ 1297 RCM_a113_eventDiagEnabled "Restraint control module: a113 event diag enabled";
CM_ SG_ 1297 RCM_a113_eventDriveOrientation "Restraint control module: a113 event drive orientation";
CM_ SG_ 1297 RCM_a113_imuPitchR8SnsrMonitTmp "Restraint control module: a113 imu pitch R8 snsr monit tmp";
CM_ SG_ 1297 RCM_a113_imuPitchR8SnsrMonitPerm "Restraint control module: a113 imu pitch R8 snsr monit perm";
CM_ SG_ 1297 RCM_a113_imuPitchR8ChnlMonitTmp "Restraint control module: a113 imu pitch R8 chnl monit tmp";
CM_ SG_ 1297 RCM_a113_imuPitchR8ChnlMonitPerm "Restraint control module: a113 imu pitch R8 chnl monit perm";
CM_ SG_ 1297 RCM_a113_eventIDFsignal "Restraint control module: a113 event ID fsignal";
CM_ SG_ 1297 RCM_a113_eventFrontLeftSeatbelt "Restraint control module: a113 event front left seatbelt";
CM_ SG_ 1297 RCM_a113_eventFrontRightSeatbelt "Restraint control module: a113 event front right seatbelt";
CM_ SG_ 1297 RCM_a113_eventVehicleSpeed "Restraint control module: a113 event vehicle speed";
CM_ SG_ 1297 RCM_a113_eventSteeringAngle "Restraint control module: a113 event steering angle";
CM_ SG_ 1297 RCM_a113_eventDriverBrakeApply "Restraint control module: a113 event driver brake apply; raw 3 = signal not available (SNA)";
CM_ SG_ 1297 RCM_a113_eventAccelPedalPos "Restraint control module: a113 event accel pedal pos; raw 255 = signal not available (SNA)";
CM_ SG_ 1297 RCM_a114_eventArmStatus "Restraint control module: a114 event arm status";
CM_ SG_ 1297 RCM_a114_eventFactoryMode "Restraint control module: a114 event factory mode";
CM_ SG_ 1297 RCM_a114_eventDiagEnabled "Restraint control module: a114 event diag enabled";
CM_ SG_ 1297 RCM_a114_eventDriveOrientation "Restraint control module: a114 event drive orientation";
CM_ SG_ 1297 RCM_a114_imuRollR8SnsrMonitTmp "Restraint control module: a114 imu roll R8 snsr monit tmp";
CM_ SG_ 1297 RCM_a114_imuRollR8SnsrMonitPerm "Restraint control module: a114 imu roll R8 snsr monit perm";
CM_ SG_ 1297 RCM_a114_imuRollR8ChnlMonitTmp "Restraint control module: a114 imu roll R8 chnl monit tmp";
CM_ SG_ 1297 RCM_a114_imuRollR8ChnlMonitPerm "Restraint control module: a114 imu roll R8 chnl monit perm";
CM_ SG_ 1297 RCM_a114_eventIDFsignal "Restraint control module: a114 event ID fsignal";
CM_ SG_ 1297 RCM_a114_eventFrontLeftSeatbelt "Restraint control module: a114 event front left seatbelt";
CM_ SG_ 1297 RCM_a114_eventFrontRightSeatbelt "Restraint control module: a114 event front right seatbelt";
CM_ SG_ 1297 RCM_a114_eventVehicleSpeed "Restraint control module: a114 event vehicle speed";
CM_ SG_ 1297 RCM_a114_eventSteeringAngle "Restraint control module: a114 event steering angle";
CM_ SG_ 1297 RCM_a114_eventDriverBrakeApply "Restraint control module: a114 event driver brake apply; raw 3 = signal not available (SNA)";
CM_ SG_ 1297 RCM_a114_eventAccelPedalPos "Restraint control module: a114 event accel pedal pos; raw 255 = signal not available (SNA)";
CM_ SG_ 1297 RCM_a115_eventArmStatus "Restraint control module: a115 event arm status";
CM_ SG_ 1297 RCM_a115_eventFactoryMode "Restraint control module: a115 event factory mode";
CM_ SG_ 1297 RCM_a115_eventDiagEnabled "Restraint control module: a115 event diag enabled";
CM_ SG_ 1297 RCM_a115_eventDriveOrientation "Restraint control module: a115 event drive orientation";
CM_ SG_ 1297 RCM_a115_imuLinAccChnlMonitTmp "Restraint control module: a115 imu lin acc chnl monit tmp";
CM_ SG_ 1297 RCM_a115_imuLinAccChnlMonitPerm "Restraint control module: a115 imu lin acc chnl monit perm";
CM_ SG_ 1297 RCM_a115_eventIDFsignal "Restraint control module: a115 event ID fsignal";
CM_ SG_ 1297 RCM_a115_eventFrontLeftSeatbelt "Restraint control module: a115 event front left seatbelt";
CM_ SG_ 1297 RCM_a115_eventFrontRightSeatbelt "Restraint control module: a115 event front right seatbelt";
CM_ SG_ 1297 RCM_a115_eventVehicleSpeed "Restraint control module: a115 event vehicle speed";
CM_ SG_ 1297 RCM_a115_eventSteeringAngle "Restraint control module: a115 event steering angle";
CM_ SG_ 1297 RCM_a115_eventDriverBrakeApply "Restraint control module: a115 event driver brake apply; raw 3 = signal not available (SNA)";
CM_ SG_ 1297 RCM_a115_eventAccelPedalPos "Restraint control module: a115 event accel pedal pos; raw 255 = signal not available (SNA)";
CM_ SG_ 1297 RCM_a116_eventArmStatus "Restraint control module: a116 event arm status";
CM_ SG_ 1297 RCM_a116_eventFactoryMode "Restraint control module: a116 event factory mode";
CM_ SG_ 1297 RCM_a116_eventDiagEnabled "Restraint control module: a116 event diag enabled";
CM_ SG_ 1297 RCM_a116_eventDriveOrientation "Restraint control module: a116 event drive orientation";
CM_ SG_ 1297 RCM_a116_imuLatAccChnlMonitTmp "Restraint control module: a116 imu lat acc chnl monit tmp";
CM_ SG_ 1297 RCM_a116_imuLatAccChnlMonitPerm "Restraint control module: a116 imu lat acc chnl monit perm";
CM_ SG_ 1297 RCM_a116_eventIDFsignal "Restraint control module: a116 event ID fsignal";
CM_ SG_ 1297 RCM_a116_eventFrontLeftSeatbelt "Restraint control module: a116 event front left seatbelt";
CM_ SG_ 1297 RCM_a116_eventFrontRightSeatbelt "Restraint control module: a116 event front right seatbelt";
CM_ SG_ 1297 RCM_a116_eventVehicleSpeed "Restraint control module: a116 event vehicle speed";
CM_ SG_ 1297 RCM_a116_eventSteeringAngle "Restraint control module: a116 event steering angle";
CM_ SG_ 1297 RCM_a116_eventDriverBrakeApply "Restraint control module: a116 event driver brake apply; raw 3 = signal not available (SNA)";
CM_ SG_ 1297 RCM_a116_eventAccelPedalPos "Restraint control module: a116 event accel pedal pos; raw 255 = signal not available (SNA)";
CM_ SG_ 1297 RCM_a117_eventArmStatus "Restraint control module: a117 event arm status";
CM_ SG_ 1297 RCM_a117_eventFactoryMode "Restraint control module: a117 event factory mode";
CM_ SG_ 1297 RCM_a117_eventDiagEnabled "Restraint control module: a117 event diag enabled";
CM_ SG_ 1297 RCM_a117_eventDriveOrientation "Restraint control module: a117 event drive orientation";
CM_ SG_ 1297 RCM_a117_imuZaccelChnlMonitTmp "Restraint control module: a117 imu zaccel chnl monit tmp";
CM_ SG_ 1297 RCM_a117_imuZaccelChnlMonitPerm "Restraint control module: a117 imu zaccel chnl monit perm";
CM_ SG_ 1297 RCM_a117_eventIDFsignal "Restraint control module: a117 event ID fsignal";
CM_ SG_ 1297 RCM_a117_eventFrontLeftSeatbelt "Restraint control module: a117 event front left seatbelt";
CM_ SG_ 1297 RCM_a117_eventFrontRightSeatbelt "Restraint control module: a117 event front right seatbelt";
CM_ SG_ 1297 RCM_a117_eventVehicleSpeed "Restraint control module: a117 event vehicle speed";
CM_ SG_ 1297 RCM_a117_eventSteeringAngle "Restraint control module: a117 event steering angle";
CM_ SG_ 1297 RCM_a117_eventDriverBrakeApply "Restraint control module: a117 event driver brake apply; raw 3 = signal not available (SNA)";
CM_ SG_ 1297 RCM_a117_eventAccelPedalPos "Restraint control module: a117 event accel pedal pos; raw 255 = signal not available (SNA)";
CM_ SG_ 1297 RCM_a118_eventArmStatus "Restraint control module: a118 event arm status";
CM_ SG_ 1297 RCM_a118_eventFactoryMode "Restraint control module: a118 event factory mode";
CM_ SG_ 1297 RCM_a118_eventDiagEnabled "Restraint control module: a118 event diag enabled";
CM_ SG_ 1297 RCM_a118_eventDriveOrientation "Restraint control module: a118 event drive orientation";
CM_ SG_ 1297 RCM_a118_imuInPlaneSnsrMonitTmp "Restraint control module: a118 imu in plane snsr monit tmp";
CM_ SG_ 1297 RCM_a118_imuInPlaneSnsrMonitPerm "Restraint control module: a118 imu in plane snsr monit perm";
CM_ SG_ 1297 RCM_a118_eventIDFsignal "Restraint control module: a118 event ID fsignal";
CM_ SG_ 1297 RCM_a118_eventFrontLeftSeatbelt "Restraint control module: a118 event front left seatbelt";
CM_ SG_ 1297 RCM_a118_eventFrontRightSeatbelt "Restraint control module: a118 event front right seatbelt";
CM_ SG_ 1297 RCM_a118_eventVehicleSpeed "Restraint control module: a118 event vehicle speed";
CM_ SG_ 1297 RCM_a118_eventSteeringAngle "Restraint control module: a118 event steering angle";
CM_ SG_ 1297 RCM_a118_eventDriverBrakeApply "Restraint control module: a118 event driver brake apply; raw 3 = signal not available (SNA)";
CM_ SG_ 1297 RCM_a118_eventAccelPedalPos "Restraint control module: a118 event accel pedal pos; raw 255 = signal not available (SNA)";
CM_ BO_ 881 "Restraint control module message: alert matrix";
CM_ SG_ 881 RCM_matrixIndex "Restraint control module: matrix index";
CM_ SG_ 881 RCM_a000_crashDetected "Restraint control module: a000 crash detected";
CM_ SG_ 881 RCM_a001_nearDeploy "Restraint control module: a001 near deploy";
CM_ SG_ 881 RCM_a002_airbagsNotArmed "Restraint control module: a002 airbags not armed";
CM_ SG_ 881 RCM_a003_warningIndicator "Restraint control module: a003 warning indicator";
CM_ SG_ 881 RCM_a004_internalFault "Restraint control module: a004 internal fault";
CM_ SG_ 881 RCM_a005_crcError "Restraint control module: a005 crc error";
CM_ SG_ 881 RCM_a006_batteryVoltageRange "Restraint control module: a006 battery voltage range";
CM_ SG_ 881 RCM_a007_powerSupplyExternal "Restraint control module: a007 power supply external";
CM_ SG_ 881 RCM_a008_powerSupplyInternal "Restraint control module: a008 power supply internal";
CM_ SG_ 881 RCM_a009_reprogramLimit "Restraint control module: a009 reprogram limit";
CM_ SG_ 881 RCM_a010_scmDisabled "Restraint control module: a010 scm disabled";
CM_ SG_ 881 RCM_a011_eepromDataLocked "Restraint control module: a011 eeprom data locked";
CM_ SG_ 881 RCM_a012_vinStorage "Restraint control module: a012 vin storage";
CM_ SG_ 881 RCM_a013_driverOrientation "Restraint control module: a013 driver orientation";
CM_ SG_ 881 RCM_a014_driverABStage1 "Restraint control module: a014 driver AB stage1";
CM_ SG_ 881 RCM_a015_driverABStage2 "Restraint control module: a015 driver AB stage2";
CM_ SG_ 881 RCM_a016_passABStage1 "Restraint control module: a016 pass AB stage1";
CM_ SG_ 881 RCM_a017_passABStage2 "Restraint control module: a017 pass AB stage2";
CM_ SG_ 881 RCM_a018_passengerActiveVent "Restraint control module: a018 passenger active vent";
CM_ SG_ 881 RCM_a019_pretenShldrFrontLeft "Restraint control module: a019 preten shldr front left";
CM_ SG_ 881 RCM_a020_pretenShldFrontRight "Restraint control module: a020 preten shld front right";
CM_ SG_ 881 RCM_a021_pretenLapFrontLeft "Restraint control module: a021 preten lap front left";
CM_ SG_ 881 RCM_a022_pretenLapFrontRight "Restraint control module: a022 preten lap front right";
CM_ SG_ 881 RCM_a023_loadLimiterLeftSide "Restraint control module: a023 load limiter left side";
CM_ SG_ 881 RCM_a024_loadLimiterRightSide "Restraint control module: a024 load limiter right side";
CM_ SG_ 881 RCM_a025_kneeABDriver "Restraint control module: a025 knee AB driver";
CM_ SG_ 881 RCM_a026_kneeABFrontPassenger "Restraint control module: a026 knee AB front passenger";
CM_ SG_ 881 RCM_a027_sideAB1stRowLeft "Restraint control module: a027 side ab1st row left";
CM_ SG_ 881 RCM_a028_sideAB1stRowRight "Restraint control module: a028 side ab1st row right";
CM_ SG_ 881 RCM_a029_driverABActiveVent "Restraint control module: a029 driver AB active vent";
CM_ SG_ 881 RCM_a030_farSideInboardAirbag "Restraint control module: a030 far side inboard airbag";
CM_ SG_ 881 RCM_a031_frontCenterAirbag "Restraint control module: a031 front center airbag";
CM_ SG_ 881 RCM_a032_curtainABLeft "Restraint control module: a032 curtain AB left";
CM_ SG_ 881 RCM_a033_curtainABRight "Restraint control module: a033 curtain AB right";
CM_ SG_ 881 RCM_a034_preten2ndRowLeft "Restraint control module: a034 preten2nd row left";
CM_ SG_ 881 RCM_a035_preten2ndRowRight "Restraint control module: a035 preten2nd row right";
CM_ SG_ 881 RCM_a036_curAB2ndRowLeft "Restraint control module: a036 cur ab2nd row left";
CM_ SG_ 881 RCM_a037_curAB2ndRowRight "Restraint control module: a037 cur ab2nd row right";
CM_ SG_ 881 RCM_a038_unusedA "Restraint control module: a038 unused a";
CM_ SG_ 881 RCM_a039_unusedB "Restraint control module: a039 unused b";
CM_ SG_ 881 RCM_a040_hoodActuatorRight "Restraint control module: a040 hood actuator right";
CM_ SG_ 881 RCM_a041_hoodActuatorLeft "Restraint control module: a041 hood actuator left";
CM_ SG_ 881 RCM_a042_ens1Line "Restraint control module: a042 ens1 line";
CM_ SG_ 881 RCM_a043_ens2Line "Restraint control module: a043 ens2 line";
CM_ SG_ 881 RCM_a044_upFrontSensorLeft "Restraint control module: a044 up front sensor left";
CM_ SG_ 881 RCM_a045_upFrontSensorRight "Restraint control module: a045 up front sensor right";
CM_ SG_ 881 RCM_a046_sideAccelBPillarLeft "Restraint control module: a046 side accel b pillar left";
CM_ SG_ 881 RCM_a047_sideAccelBPillarRight "Restraint control module: a047 side accel b pillar right";
CM_ SG_ 881 RCM_a048_sideAccelCPillarLeft "Restraint control module: a048 side accel c pillar left";
CM_ SG_ 881 RCM_a049_sideAccelCPillarRight "Restraint control module: a049 side accel c pillar right";
CM_ SG_ 881 RCM_a050_upFrontSensorCenter "Restraint control module: a050 up front sensor center";
CM_ SG_ 881 RCM_a051_pressureFrontLftDoor "Restraint control module: a051 pressure front lft door";
CM_ SG_ 881 RCM_a052_pressureFrontRtDoor "Restraint control module: a052 pressure front rt door";
CM_ SG_ 881 RCM_a053_pressurePedProLeft "Restraint control module: a053 pressure ped pro left";
CM_ SG_ 881 RCM_a054_pressurePedProRight "Restraint control module: a054 pressure ped pro right";
CM_ SG_ 881 RCM_a055_inertialMeasurement "Restraint control module: a055 inertial measurement";
CM_ SG_ 881 RCM_a056_passengerFrontOCS "Restraint control module: a056 passenger front OCS";
CM_ SG_ 881 RCM_a057_driverOCS "Restraint control module: a057 driver OCS";
CM_ SG_ 881 RCM_a058_buckle1stRowLeft "Restraint control module: a058 buckle1st row left";
CM_ SG_ 881 RCM_a059_buckle1stRowRight "Restraint control module: a059 buckle1st row right";
CM_ SG_ 881 RCM_a060_stpsLeft "Restraint control module: a060 stps left";
CM_ SG_ 881 RCM_a061_stpsRight "Restraint control module: a061 stps right";
CM_ SG_ 881 RCM_a062_alrSwitch "Restraint control module: a062 alr switch";
CM_ SG_ 881 RCM_a063_sbsw2ndRowRight "Restraint control module: a063 sbsw2nd row right";
CM_ SG_ 881 RCM_a064_hardwareCodingPin1 "Restraint control module: a064 hardware coding pin1";
CM_ SG_ 881 RCM_a065_driverOrientConfigPin "Restraint control module: a065 driver orient config pin";
CM_ SG_ 881 RCM_a066_seatBackSw2ndRowLeft "Restraint control module: a066 seat back sw2nd row left";
CM_ SG_ 881 RCM_a067_comCANInitFailure "Restraint control module: a067 com CAN init failure";
CM_ SG_ 881 RCM_a068_comChassisBusOff "Restraint control module: a068 com chassis bus off";
CM_ SG_ 881 RCM_a069_comCHCANPH7 "Restraint control module: a069 com CHCANPH7";
CM_ SG_ 881 RCM_a070_comCHCANPH8 "Restraint control module: a070 com CHCANPH8";
CM_ SG_ 881 RCM_a071_comCHCANPH9 "Restraint control module: a071 com CHCANPH9";
CM_ SG_ 881 RCM_a072_comUnused "Restraint control module: a072 com unused";
CM_ SG_ 881 RCM_a073_comCHCANPH4 "Restraint control module: a073 com CHCANPH4";
CM_ SG_ 881 RCM_a074_comCHCANPH5 "Restraint control module: a074 com CHCANPH5";
CM_ SG_ 881 RCM_a075_comCHCANPH6 "Restraint control module: a075 com CHCANPH6";
CM_ SG_ 881 RCM_a076_comEPBLStatus "Restraint control module: a076 com EPBL status";
CM_ SG_ 881 RCM_a077_comEPBRStatus "Restraint control module: a077 com EPBR status";
CM_ SG_ 881 RCM_a078_comOCS1PStatus "Restraint control module: a078 com OCS1 p status";
CM_ SG_ 881 RCM_a079_comOCS1DStatus "Restraint control module: a079 com OCS1 d status";
CM_ SG_ 881 RCM_a080_comGTWACS "Restraint control module: a080 com GTWACS";
CM_ SG_ 881 RCM_a081_comVCFRONTLVPwr "Restraint control module: a081 com VCFRONTLV pwr";
CM_ SG_ 881 RCM_a082_comUIodo "Restraint control module: a082 com u iodo";
CM_ SG_ 881 RCM_a083_comGTWCarState "Restraint control module: a083 com GTW car state";
CM_ SG_ 881 RCM_a084_comTPMSStatus "Restraint control module: a084 com TPMS status";
CM_ SG_ 881 RCM_a085_comGTWCarConfig "Restraint control module: a085 com GTW car config";
CM_ SG_ 881 RCM_a086_comVINMIA "Restraint control module: a086 com VINMIA";
CM_ SG_ 881 RCM_a087_comCANSilent "Restraint control module: a087 com CAN silent";
CM_ SG_ 881 RCM_a088_comCHCANPH2 "Restraint control module: a088 com CHCANPH2";
CM_ SG_ 881 RCM_a089_comCHCANPH3 "Restraint control module: a089 com CHCANPH3";
CM_ SG_ 881 RCM_a090_comPartyBusOff "Restraint control module: a090 com party bus off";
CM_ SG_ 881 RCM_a091_comEPAS3PsysStatus "Restraint control module: a091 com EPAS3 psys status";
CM_ SG_ 881 RCM_a092_comDASISF "Restraint control module: a092 com DASISF";
CM_ SG_ 881 RCM_a093_comVCLEFTStatus "Restraint control module: a093 com VCLEFT status";
CM_ SG_ 881 RCM_a094_comVCRIGHTStatus "Restraint control module: a094 com VCRIGHT status";
CM_ SG_ 881 RCM_a095_comESPstatus "Restraint control module: a095 com ES pstatus";
CM_ SG_ 881 RCM_a096_comESPwheelSpeeds "Restraint control module: a096 com ES pwheel speeds";
CM_ SG_ 881 RCM_a097_comDIspeed "Restraint control module: a097 com d ispeed";
CM_ SG_ 881 RCM_a098_comDIchassisControl "Restraint control module: a098 com d ichassis control";
CM_ SG_ 881 RCM_a099_comDItorque "Restraint control module: a099 com d itorque";
CM_ SG_ 881 RCM_a100_comDIsystemStatus "Restraint control module: a100 com d isystem status";
CM_ SG_ 881 RCM_a101_idfSystem "Restraint control module: a101 idf system";
CM_ SG_ 881 RCM_a102_imuYawR8OffstCompLim "Restraint control module: a102 imu yaw R8 offst comp lim";
CM_ SG_ 881 RCM_a103_imuPtchR8OffstCompLim "Restraint control module: a103 imu ptch R8 offst comp lim";
CM_ SG_ 881 RCM_a104_imuRollR8OffstCompLim "Restraint control module: a104 imu roll R8 offst comp lim";
CM_ SG_ 881 RCM_a105_imuLongAccOffstCompLim "Restraint control module: a105 imu long acc offst comp lim";
CM_ SG_ 881 RCM_a106_imuLatAccOffstCompLim "Restraint control module: a106 imu lat acc offst comp lim";
CM_ SG_ 881 RCM_a107_imuVertAccOffstCompLim "Restraint control module: a107 imu vert acc offst comp lim";
CM_ SG_ 881 RCM_a108_crashAlgoWakeup "Restraint control module: a108 crash algo wakeup";
CM_ SG_ 881 RCM_a109_abuseImmunity "Restraint control module: a109 abuse immunity";
CM_ SG_ 881 RCM_a110_factoryMode "Restraint control module: a110 factory mode";
CM_ SG_ 881 RCM_a111_diagnosticsEnabled "Restraint control module: a111 diagnostics enabled";
CM_ SG_ 881 RCM_a112_imuYawRate "Restraint control module: a112 imu yaw rate";
CM_ SG_ 881 RCM_a113_imuPitchRate "Restraint control module: a113 imu pitch rate";
CM_ SG_ 881 RCM_a114_imuRollRate "Restraint control module: a114 imu roll rate";
CM_ SG_ 881 RCM_a115_imuLinearAcceleration "Restraint control module: a115 imu linear acceleration";
CM_ SG_ 881 RCM_a116_imuLateralAcceleration "Restraint control module: a116 imu lateral acceleration";
CM_ SG_ 881 RCM_a117_imuVerticalAcceleration "Restraint control module: a117 imu vertical acceleration";
CM_ SG_ 881 RCM_a118_imuInPlaneAcceleration "Restraint control module: a118 imu in plane acceleration";
CM_ BO_ 1471 "RCU ECU message: alert log";
CM_ SG_ 1471 RCU_alertID "RCU ECU: alert ID";
CM_ SG_ 1471 RCU_alertState "RCU ECU: alert state";
CM_ SG_ 1471 RCU_a010_sensorPowerSupply "RCU ECU: a010 sensor power supply";
CM_ SG_ 1471 RCU_a010_sensorHardware "RCU ECU: a010 sensor hardware";
CM_ SG_ 1471 RCU_a010_sensorSignal "RCU ECU: a010 sensor signal";
CM_ SG_ 1471 RCU_a023_validityOnChassisBus "RCU ECU: a023 validity on chassis bus";
CM_ SG_ 1471 RCU_a023_validityOnPartyBus "RCU ECU: a023 validity on party bus";
CM_ SG_ 1471 RCU_a024_validityOnChassisBus "RCU ECU: a024 validity on chassis bus";
CM_ SG_ 1471 RCU_a024_validityOnPartyBus "RCU ECU: a024 validity on party bus";
CM_ SG_ 1471 RCU_a025_validityOnChassisBus "RCU ECU: a025 validity on chassis bus";
CM_ SG_ 1471 RCU_a025_validityOnPartyBus "RCU ECU: a025 validity on party bus";
CM_ SG_ 1471 RCU_a035_validityOnChassisBus "RCU ECU: a035 validity on chassis bus";
CM_ SG_ 1471 RCU_a035_validityOnPartyBus "RCU ECU: a035 validity on party bus";
CM_ SG_ 1471 RCU_a036_validityOnChassisBus "RCU ECU: a036 validity on chassis bus";
CM_ SG_ 1471 RCU_a036_validityOnPartyBus "RCU ECU: a036 validity on party bus";
CM_ BO_ 998 "RCU ECU message: alert matrix";
CM_ SG_ 998 RCU_matrixIndex "RCU ECU: matrix index";
CM_ SG_ 998 RCU_a001_valveDriverFault "RCU ECU: a001 valve driver fault";
CM_ SG_ 998 RCU_a002_solenoidValveFault "RCU ECU: a002 solenoid valve fault";
CM_ SG_ 998 RCU_a003_pumpMotorFault "RCU ECU: a003 pump motor fault";
CM_ SG_ 998 RCU_a004_supplyOvervoltage "RCU ECU: a004 supply overvoltage";
CM_ SG_ 998 RCU_a005_supplyUndervoltage "RCU ECU: a005 supply undervoltage";
CM_ SG_ 998 RCU_a006_wakeLineOpen "RCU ECU: a006 wake line open";
CM_ SG_ 998 RCU_a007_pressureSensorFault "RCU ECU: a007 pressure sensor fault";
CM_ SG_ 998 RCU_a008_pressureNotCalibrated "RCU ECU: a008 pressure not calibrated";
CM_ SG_ 998 RCU_a009_brakeFluidLow "RCU ECU: a009 brake fluid low";
CM_ SG_ 998 RCU_a010_pedalSensorFault "RCU ECU: a010 pedal sensor fault";
CM_ SG_ 998 RCU_a011_idbPedalTravelMismatch "RCU ECU: a011 idb pedal travel mismatch";
CM_ SG_ 998 RCU_a012_pedalSensorNotCal "RCU ECU: a012 pedal sensor not cal";
CM_ SG_ 998 RCU_a013_mcuGenericFault "RCU ECU: a013 mcu generic fault";
CM_ SG_ 998 RCU_a014_asicTempHigh "RCU ECU: a014 asic temp high";
CM_ SG_ 998 RCU_a015_fluidLeakDetected "RCU ECU: a015 fluid leak detected";
CM_ SG_ 998 RCU_a016_partyBusOff "RCU ECU: a016 party bus off";
CM_ SG_ 998 RCU_a017_chassisBusOff "RCU ECU: a017 chassis bus off";
CM_ SG_ 998 RCU_a018_DItorquePathFaulted "RCU ECU: a018 d itorque path faulted";
CM_ SG_ 998 RCU_a019_DItorquePathActive "RCU ECU: a019 d itorque path active";
CM_ SG_ 998 RCU_a020_BBstatusDLC "RCU ECU: a020 b bstatus DLC";
CM_ SG_ 998 RCU_a021_BBstatusChecksum "RCU ECU: a021 b bstatus checksum";
CM_ SG_ 998 RCU_a022_BBstatusCounter "RCU ECU: a022 b bstatus counter";
CM_ SG_ 998 RCU_a023_IDBstatusDLC "RCU ECU: a023 ID bstatus DLC";
CM_ SG_ 998 RCU_a024_IDBstatusChecksum "RCU ECU: a024 ID bstatus checksum";
CM_ SG_ 998 RCU_a025_IDBstatusCounter "RCU ECU: a025 ID bstatus counter";
CM_ SG_ 998 RCU_a026_DIchassisControlDLC "RCU ECU: a026 d ichassis control DLC";
CM_ SG_ 998 RCU_a027_DIchassisCtrlChecksum "RCU ECU: a027 d ichassis ctrl checksum";
CM_ SG_ 998 RCU_a028_DIchassisControlCounter "RCU ECU: a028 d ichassis control counter";
CM_ SG_ 998 RCU_a029_PMstate2DLC "RCU ECU: a029 p mstate2 DLC";
CM_ SG_ 998 RCU_a030_PMstate2Checksum "RCU ECU: a030 p mstate2 checksum";
CM_ SG_ 998 RCU_a031_PMstate2Counter "RCU ECU: a031 p mstate2 counter";
CM_ SG_ 998 RCU_a032_VCFRONTLVPowerStateDLC "RCU ECU: a032 VCFRONTLV power state DLC";
CM_ SG_ 998 RCU_a033_VCFRONTLVPowerStateChec "RCU ECU: a033 VCFRONTLV power state checksum";
CM_ SG_ 998 RCU_a034_VCFRONTLVPowerStateCoun "RCU ECU: a034 VCFRONTLV power state counter";
CM_ SG_ 998 RCU_a035_IDBpcpInvalid "RCU ECU: a035 ID bpcp invalid";
CM_ SG_ 998 RCU_a036_IDBpspInvalid "RCU ECU: a036 ID bpsp invalid";
CM_ SG_ 998 RCU_a037_IDBinputRodStrokeInvali "RCU ECU: a037 ID binput rod stroke invalid";
CM_ SG_ 998 RCU_a038_DIsystemStatusDLC "RCU ECU: a038 d isystem status DLC";
CM_ SG_ 998 RCU_a039_DIaccelPosInvalid "RCU ECU: a039 d iaccel pos invalid";
CM_ SG_ 998 RCU_a040_DIgearInvalid "RCU ECU: a040 d igear invalid";
CM_ SG_ 998 RCU_a041_DIsystemStatusCounter "RCU ECU: a041 d isystem status counter";
CM_ SG_ 998 RCU_a042_DIsystemStatusChecksum "RCU ECU: a042 d isystem status checksum";
CM_ SG_ 998 RCU_a043_VCFRONTiBoosterLvStateI "RCU ECU: a043 VCFRON ti booster lv state invalid";
CM_ SG_ 998 RCU_a044_VCFRONTsensorsMIA "RCU ECU: a044 VCFRON tsensors MIA";
CM_ SG_ 998 RCU_a045_VCFRONTtempInvalid "RCU ECU: a045 VCFRON ttemp invalid";
CM_ SG_ 998 RCU_a046_brakeFluidLevelSNA "RCU ECU: a046 brake fluid level SNA";
CM_ SG_ 998 RCU_a047_ESPwheelSpeedsDLC "RCU ECU: a047 ES pwheel speeds DLC";
CM_ SG_ 998 RCU_a048_ESPFrLWSSLInvalid "RCU ECU: a048 ESP fr LWSSL invalid";
CM_ SG_ 998 RCU_a049_ESPFrRWSSLInvalid "RCU ECU: a049 ESP fr RWSSL invalid";
CM_ SG_ 998 RCU_a050_ESPReLWSSLInvalid "RCU ECU: a050 ESP re LWSSL invalid";
CM_ SG_ 998 RCU_a051_ESPReRWSSLInvalid "RCU ECU: a051 ESP re RWSSL invalid";
CM_ SG_ 998 RCU_a052_ESPwheelSpeedsCounter "RCU ECU: a052 ES pwheel speeds counter";
CM_ SG_ 998 RCU_a053_ESPwheelSpeedsChecksum "RCU ECU: a053 ES pwheel speeds checksum";
CM_ SG_ 998 RCU_a054_IDBcircuitPressFaulted "RCU ECU: a054 ID bcircuit press faulted";
CM_ SG_ 998 RCU_a055_IDBsimulatorPressFaulte "RCU ECU: a055 ID bsimulator press faulted";
CM_ SG_ 998 RCU_a056_redundantControllerIsMa "RCU ECU: a056 redundant controller is master";
CM_ SG_ 998 RCU_a057_DASredundantBrakingCont "RCU ECU: a057 DA sredundant braking control DLC";
CM_ SG_ 998 RCU_a058_DASredundantBrakingCont "RCU ECU: a058 DA sredundant braking control counter";
CM_ SG_ 998 RCU_a059_DASredundantBrakingCont "RCU ECU: a059 DA sredundant braking control checksum";
CM_ SG_ 998 RCU_a060_DASbrakeTorqueCommandIn "RCU ECU: a060 DA sbrake torque command invalid";
CM_ SG_ 998 RCU_a061_DIlocStatus2DLC "RCU ECU: a061 d iloc status2 DLC";
CM_ SG_ 998 RCU_a062_DIlocStatus2Counter "RCU ECU: a062 d iloc status2 counter";
CM_ SG_ 998 RCU_a063_DIlocStatus2Checksum "RCU ECU: a063 d iloc status2 checksum";
CM_ SG_ 998 RCU_a064_ESPredundantBrakingStat "RCU ECU: a064 ES predundant braking status DLC";
CM_ SG_ 998 RCU_a065_ESPredundantBrakingStat "RCU ECU: a065 ES predundant braking status counter";
CM_ SG_ 998 RCU_a066_ESPredundantBrakingStat "RCU ECU: a066 ES predundant braking status checksum";
CM_ BO_ 831 "RCU ECU message: info";
CM_ SG_ 831 RCU_infoIndex "RCU ECU: info index";
CM_ SG_ 831 RCU_infoPcbaID "RCU ECU: info pcba ID";
CM_ SG_ 831 RCU_infoAssemblyID "RCU ECU: info assembly ID";
CM_ SG_ 831 RCU_infoUsageID "RCU ECU: info usage ID";
CM_ SG_ 831 RCU_infoSubUsageID "RCU ECU: info sub usage ID";
CM_ BO_ 1415 "TCU2 ECU message: sleep config";
CM_ SG_ 1415 TCU2_tc10Version "Indicates which version of Open Alliance's TC10 protocol is supported by the modem; raw 0 = signal not available (SNA)";
CM_ BO_ 1413 "TCU2 ECU message: alert log";
CM_ SG_ 1413 TCU2_alertID "TCU2 ECU: alert ID";
CM_ SG_ 1413 TCU2_alertState "TCU2 ECU: alert state";
CM_ SG_ 1413 TCU2_w001_FailCode "TCU2 ECU: w001 fail code";
CM_ SG_ 1413 TCU2_w002_RejCause "TCU2 ECU: w002 rej cause";
CM_ SG_ 1413 TCU2_w003_CallFailCode "TCU2 ECU: w003 call fail code";
CM_ SG_ 1413 TCU2_w004_MSDFailCode "TCU2 ECU: w004 MSD fail code";
CM_ SG_ 1413 TCU2_w006_Count "TCU2 ECU: w006 count";
CM_ SG_ 1413 TCU2_w007_Count "TCU2 ECU: w007 count";
CM_ SG_ 1413 TCU2_w009_CrashCode "TCU2 ECU: w009 crash code";
CM_ SG_ 1413 TCU2_w012_DataRAT "TCU2 ECU: w012 data RAT";
CM_ SG_ 1413 TCU2_w012_RSRP "TCU2 ECU: w012 RSRP";
CM_ SG_ 1413 TCU2_w012_RSRQ "TCU2 ECU: w012 RSRQ";
CM_ SG_ 1413 TCU2_w012_MNC "TCU2 ECU: w012 MNC";
CM_ SG_ 1413 TCU2_w012_AvgQueueUsage "TCU2 ECU: w012 avg queue usage";
CM_ SG_ 1413 TCU2_w012_NSAAvailable "TCU2 ECU: w012 NSA available";
CM_ SG_ 1413 TCU2_w013_DataRAT "TCU2 ECU: w013 data RAT";
CM_ SG_ 1413 TCU2_w013_RSRP "TCU2 ECU: w013 RSRP";
CM_ SG_ 1413 TCU2_w013_RSRQ "TCU2 ECU: w013 RSRQ";
CM_ SG_ 1413 TCU2_w013_MNC "TCU2 ECU: w013 MNC";
CM_ SG_ 1413 TCU2_w013_AvgQueueUsage "TCU2 ECU: w013 avg queue usage";
CM_ SG_ 1413 TCU2_w013_NSAAvailable "TCU2 ECU: w013 NSA available";
CM_ SG_ 1413 TCU2_w014_Reason "TCU2 ECU: w014 reason";
CM_ BO_ 1414 "TCU2 ECU message: alert matrix1";
CM_ SG_ 1414 TCU2_w001_IMSRegistrationFailed "TCU2 ECU: w001 IMS registration failed";
CM_ SG_ 1414 TCU2_w002_CellRegRejected "TCU2 ECU: w002 cell reg rejected";
CM_ SG_ 1414 TCU2_w003_ECallFailed "TCU2 ECU: w003 e call failed";
CM_ SG_ 1414 TCU2_w004_MSDTransmissionFailed "TCU2 ECU: w004 MSD transmission failed";
CM_ SG_ 1414 TCU2_w005_SIMSlotError "TCU2 ECU: w005 SIM slot error";
CM_ SG_ 1414 TCU2_w006_MpssUnavailable "TCU2 ECU: w006 mpss unavailable";
CM_ SG_ 1414 TCU2_w007_ModemUnreachable "TCU2 ECU: w007 modem unreachable";
CM_ SG_ 1414 TCU2_w008_KernelPanic "TCU2 ECU: w008 kernel panic";
CM_ SG_ 1414 TCU2_w009_WifiFirmwareCrash "TCU2 ECU: w009 wifi firmware crash";
CM_ SG_ 1414 TCU2_w010_WifiDumpDetected "TCU2 ECU: w010 wifi dump detected";
CM_ SG_ 1414 TCU2_w011_CellDumpDetected "TCU2 ECU: w011 cell dump detected";
CM_ SG_ 1414 TCU2_w012_UplinkDegraded "TCU2 ECU: w012 uplink degraded";
CM_ SG_ 1414 TCU2_w013_UplinkQueueFull "TCU2 ECU: w013 uplink queue full";
CM_ SG_ 1414 TCU2_w014_HostapdCrash "TCU2 ECU: w014 hostapd crash";
CM_ SG_ 1414 TCU2_w015_NPNSubscriptionActive "TCU2 ECU: w015 NPN subscription active";
CM_ SG_ 1414 TCU2_w016_IMEIMismatch "TCU2 ECU: w016 IMEI mismatch";
CM_ BO_ 1412 "TCU2 ECU message: log";
CM_ SG_ 1412 TCU2_logMux "TCU2 ECU: log mux";
CM_ SG_ 1412 TCU2_cpuTemp "Indicates the current temperature reported by the Central Processing Unit (CPU) in the modem application processor";
CM_ SG_ 1412 TCU2_cpuUsage "Indicates the current CPU usage in percentage reported by the modem application processor";
CM_ SG_ 1412 TCU2_mdmCoreTemperature "Indicates the current Communication Processor (CP) temperature reported by the modem CP.";
CM_ SG_ 1412 TCU2_availableMemory "Indicates the currently available Random Access Memory in the modem application processor";
CM_ SG_ 1412 TCU2_pwm "Indicates the active Pulse Width Modulation (PWM) duty cycle applied to the modem fan.";
CM_ SG_ 1412 TCU2_pwmcap "Indicates the active Pulse Width Modulation (PWM) duty cycle restriciton applied to the modem fan.";
CM_ SG_ 1412 TCU2_totalResumes "Indicates the total amount of times the modem has been resumed";
CM_ SG_ 1412 TCU2_mdmUplinkQueueSize "TCU2 ECU: mdm uplink queue size";
CM_ SG_ 1412 TCU2_mdmRSRP "TCU2 ECU: mdm RSRP";
CM_ SG_ 1412 TCU2_mdmSINR "TCU2 ECU: mdm SINR";
CM_ SG_ 1412 TCU2_mdmUplinkAllowedRate "TCU2 ECU: mdm uplink allowed rate";
CM_ SG_ 1412 TCU2_mdmUplinkAvgRate "TCU2 ECU: mdm uplink avg rate";
CM_ SG_ 1412 TCU2_mdmServiceState "TCU2 ECU: mdm service state";
CM_ SG_ 1412 TCU2_mdmIMSStatus "Indicates the current IP Multimedia System (IMS) registration state.";
CM_ SG_ 1412 TCU2_mdmSIMStatus "TCU2 ECU: mdm SIM status";
CM_ SG_ 1412 TCU2_mdmBusyActive "Reports whether the modem busy service is active on the modem application processor; raw 4294967295 = signal not available (SNA)";
CM_ SG_ 1412 TCU2_modemUptime "Indicates the current modem Application Processor uptime.";
CM_ SG_ 1412 TCU2_mdmDataRat "Reports which Radio Access Technology (RAT) is active for the current data bearer.";
CM_ SG_ 1412 TCU2_mdmDataCallStatus "Indicates the current state of the Packet Data Protocol (PDP) context.";
CM_ SG_ 1412 TCU2_mdmNSAAvailable "TCU2 ECU: mdm NSA available";
CM_ SG_ 1412 TCU2_mdmPCIID "TCU2 ECU: mdm PCIID";
CM_ SG_ 1412 TCU2_mdmMnc "TCU2 ECU: mdm mnc";
CM_ SG_ 1412 TCU2_mdmMcc "TCU2 ECU: mdm mcc";
CM_ SG_ 1412 TCU2_mdmTxKiloBytes "TCU2 ECU: mdm tx kilo bytes";
CM_ SG_ 1412 TCU2_mdmDataCallTermReason "Indicates the internal reason which the Data Call was terminated.";
CM_ SG_ 1412 TCU2_mdmDataCallTermCode "Indicates the termination code informed by the network that caused the Data Call termination.";
CM_ SG_ 1412 TCU2_cellularSMState "Indicates the current state of cellular state machine.";
CM_ SG_ 1412 TCU2_tcuSMState "Reports the state of the Telematics Control Unit (TCU) state machine.";
CM_ SG_ 1412 TCU2_checkInternetFailCount "Reports the count of unsuccessful cellular connectivity checks.";
CM_ SG_ 1412 TCU2_mdmBand "Indicates the band which the baseband processor is currently attached to the cellular network.";
CM_ SG_ 1412 TCU2_wakeSource "Indicates the source of wake event in the modem.";
CM_ BO_ 1159 "TCU ECU message: sleep config";
CM_ SG_ 1159 TCU_tc10Version "Indicates which version of Open Alliance's TC10 protocol is supported by the modem; raw 0 = signal not available (SNA)";
CM_ BO_ 1157 "TCU ECU message: alert log";
CM_ SG_ 1157 TCU_alertID "TCU ECU: alert ID";
CM_ SG_ 1157 TCU_alertState "TCU ECU: alert state";
CM_ SG_ 1157 TCU_w001_FailCode "TCU ECU: w001 fail code";
CM_ SG_ 1157 TCU_w002_RejCause "TCU ECU: w002 rej cause";
CM_ SG_ 1157 TCU_w003_CallFailCode "TCU ECU: w003 call fail code";
CM_ SG_ 1157 TCU_w004_MSDFailCode "TCU ECU: w004 MSD fail code";
CM_ SG_ 1157 TCU_w006_Count "TCU ECU: w006 count";
CM_ SG_ 1157 TCU_w007_Count "TCU ECU: w007 count";
CM_ SG_ 1157 TCU_w009_CrashCode "TCU ECU: w009 crash code";
CM_ SG_ 1157 TCU_w012_DataRAT "TCU ECU: w012 data RAT";
CM_ SG_ 1157 TCU_w012_RSRP "TCU ECU: w012 RSRP";
CM_ SG_ 1157 TCU_w012_RSRQ "TCU ECU: w012 RSRQ";
CM_ SG_ 1157 TCU_w012_MNC "TCU ECU: w012 MNC";
CM_ SG_ 1157 TCU_w012_AvgQueueUsage "TCU ECU: w012 avg queue usage";
CM_ SG_ 1157 TCU_w012_NSAAvailable "TCU ECU: w012 NSA available";
CM_ SG_ 1157 TCU_w013_DataRAT "TCU ECU: w013 data RAT";
CM_ SG_ 1157 TCU_w013_RSRP "TCU ECU: w013 RSRP";
CM_ SG_ 1157 TCU_w013_RSRQ "TCU ECU: w013 RSRQ";
CM_ SG_ 1157 TCU_w013_MNC "TCU ECU: w013 MNC";
CM_ SG_ 1157 TCU_w013_AvgQueueUsage "TCU ECU: w013 avg queue usage";
CM_ SG_ 1157 TCU_w013_NSAAvailable "TCU ECU: w013 NSA available";
CM_ SG_ 1157 TCU_w014_Reason "TCU ECU: w014 reason";
CM_ BO_ 1158 "TCU ECU message: alert matrix1";
CM_ SG_ 1158 TCU_w001_IMSRegistrationFailed "TCU ECU: w001 IMS registration failed";
CM_ SG_ 1158 TCU_w002_CellRegRejected "TCU ECU: w002 cell reg rejected";
CM_ SG_ 1158 TCU_w003_ECallFailed "TCU ECU: w003 e call failed";
CM_ SG_ 1158 TCU_w004_MSDTransmissionFailed "TCU ECU: w004 MSD transmission failed";
CM_ SG_ 1158 TCU_w005_SIMSlotError "TCU ECU: w005 SIM slot error";
CM_ SG_ 1158 TCU_w006_MpssUnavailable "TCU ECU: w006 mpss unavailable";
CM_ SG_ 1158 TCU_w007_ModemUnreachable "TCU ECU: w007 modem unreachable";
CM_ SG_ 1158 TCU_w008_KernelPanic "TCU ECU: w008 kernel panic";
CM_ SG_ 1158 TCU_w009_WifiFirmwareCrash "TCU ECU: w009 wifi firmware crash";
CM_ SG_ 1158 TCU_w010_WifiDumpDetected "TCU ECU: w010 wifi dump detected";
CM_ SG_ 1158 TCU_w011_CellDumpDetected "TCU ECU: w011 cell dump detected";
CM_ SG_ 1158 TCU_w012_UplinkDegraded "TCU ECU: w012 uplink degraded";
CM_ SG_ 1158 TCU_w013_UplinkQueueFull "TCU ECU: w013 uplink queue full";
CM_ SG_ 1158 TCU_w014_HostapdCrash "TCU ECU: w014 hostapd crash";
CM_ SG_ 1158 TCU_w015_NPNSubscriptionActive "TCU ECU: w015 NPN subscription active";
CM_ SG_ 1158 TCU_w016_IMEIMismatch "TCU ECU: w016 IMEI mismatch";
CM_ BO_ 1155 "TCU ECU message: log";
CM_ SG_ 1155 TCU_logMux "TCU ECU: log mux";
CM_ SG_ 1155 TCU_cpuTemp "Indicates the current temperature reported by the Central Processing Unit (CPU) in the modem application processor";
CM_ SG_ 1155 TCU_cpuUsage "Indicates the current CPU usage in percentage reported by the modem application processor";
CM_ SG_ 1155 TCU_mdmCoreTemperature "Indicates the current Communication Processor (CP) temperature reported by the modem CP.";
CM_ SG_ 1155 TCU_availableMemory "Indicates the currently available Random Access Memory in the modem application processor";
CM_ SG_ 1155 TCU_pwm "Indicates the active Pulse Width Modulation (PWM) duty cycle applied to the modem fan.";
CM_ SG_ 1155 TCU_pwmcap "Indicates the active Pulse Width Modulation (PWM) duty cycle restriciton applied to the modem fan.";
CM_ SG_ 1155 TCU_totalResumes "Indicates the total amount of times the modem has been resumed";
CM_ SG_ 1155 TCU_mdmUplinkQueueSize "TCU ECU: mdm uplink queue size";
CM_ SG_ 1155 TCU_mdmRSRP "TCU ECU: mdm RSRP";
CM_ SG_ 1155 TCU_mdmSINR "TCU ECU: mdm SINR";
CM_ SG_ 1155 TCU_mdmUplinkAllowedRate "TCU ECU: mdm uplink allowed rate";
CM_ SG_ 1155 TCU_mdmUplinkAvgRate "TCU ECU: mdm uplink avg rate";
CM_ SG_ 1155 TCU_mdmServiceState "TCU ECU: mdm service state";
CM_ SG_ 1155 TCU_mdmIMSStatus "Indicates the current IP Multimedia System (IMS) registration state.";
CM_ SG_ 1155 TCU_mdmSIMStatus "TCU ECU: mdm SIM status";
CM_ SG_ 1155 TCU_mdmBusyActive "Reports whether the modem busy service is active on the modem application processor; raw 4294967295 = signal not available (SNA)";
CM_ SG_ 1155 TCU_modemUptime "Indicates the current modem Application Processor uptime.";
CM_ SG_ 1155 TCU_mdmDataRat "Reports which Radio Access Technology (RAT) is active for the current data bearer.";
CM_ SG_ 1155 TCU_mdmDataCallStatus "Indicates the current state of the Packet Data Protocol (PDP) context.";
CM_ SG_ 1155 TCU_mdmNSAAvailable "TCU ECU: mdm NSA available";
CM_ SG_ 1155 TCU_mdmPCIID "TCU ECU: mdm PCIID";
CM_ SG_ 1155 TCU_mdmMnc "TCU ECU: mdm mnc";
CM_ SG_ 1155 TCU_mdmMcc "TCU ECU: mdm mcc";
CM_ SG_ 1155 TCU_mdmTxKiloBytes "TCU ECU: mdm tx kilo bytes";
CM_ SG_ 1155 TCU_mdmDataCallTermReason "Indicates the internal reason which the Data Call was terminated.";
CM_ SG_ 1155 TCU_mdmDataCallTermCode "Indicates the termination code informed by the network that caused the Data Call termination.";
CM_ SG_ 1155 TCU_cellularSMState "Indicates the current state of cellular state machine.";
CM_ SG_ 1155 TCU_tcuSMState "Reports the state of the Telematics Control Unit (TCU) state machine.";
CM_ SG_ 1155 TCU_checkInternetFailCount "Reports the count of unsuccessful cellular connectivity checks.";
CM_ SG_ 1155 TCU_mdmBand "Indicates the band which the baseband processor is currently attached to the cellular network.";
CM_ SG_ 1155 TCU_wakeSource "Indicates the source of wake event in the modem.";
CM_ BO_ 1603 "UDS ECU message: ocs1p request";
CM_ SG_ 1603 UDS_ocs1pRequestData "UDS ECU: ocs1p request data";
CM_ BO_ 1551 "UDS ECU message: thc request";
CM_ SG_ 1551 UDS_thcRequestData_H "UDS ECU: thc request data h";
CM_ SG_ 1551 UDS_thcRequestData_L "UDS ECU: thc request data l";
BA_DEF_ BO_ "GenMsgCycleTime" INT 0 3600000;
BA_DEF_ BO_ "GenMsgSendType" ENUM "Cyclic","NotUsed","NotUsed","NotUsed","NotUsed","NotUsed","NotUsed","IfActive","NoMsgSendType","NotUsed";
BA_DEF_ BO_ "VFrameFormat" ENUM "StandardCAN","ExtendedCAN","reserved","J1939PG","reserved","reserved","reserved","reserved","reserved","reserved","reserved","reserved","reserved","reserved","StandardCAN_FD","ExtendedCAN_FD";
BA_DEF_ BO_ "CANFD_BRS" ENUM "0","1";
BA_DEF_ SG_ "GenSigSNA" STRING;
BA_DEF_ SG_ "SystemSignalLongSymbol" STRING;
BA_DEF_ SG_ "Confidence" ENUM "validated","plausible","layout-only","contradicted";
BA_DEF_DEF_ "GenMsgCycleTime" 0;
BA_DEF_DEF_ "GenMsgSendType" "NoMsgSendType";
BA_DEF_DEF_ "VFrameFormat" "StandardCAN";
BA_DEF_DEF_ "CANFD_BRS" "1";
BA_DEF_DEF_ "GenSigSNA" "";
BA_DEF_DEF_ "SystemSignalLongSymbol" "";
BA_DEF_DEF_ "Confidence" "layout-only";
BA_ "GenMsgCycleTime" BO_ 881 1000;
BA_ "GenMsgSendType" BO_ 881 0;
BA_ "GenMsgCycleTime" BO_ 998 1000;
BA_ "GenMsgSendType" BO_ 998 0;
BA_ "GenMsgCycleTime" BO_ 831 10000;
BA_ "GenMsgSendType" BO_ 831 0;
BA_ "GenMsgCycleTime" BO_ 1415 1000;
BA_ "GenMsgSendType" BO_ 1415 0;
BA_ "GenMsgCycleTime" BO_ 1414 1000;
BA_ "GenMsgSendType" BO_ 1414 0;
BA_ "GenMsgCycleTime" BO_ 1412 1000;
BA_ "GenMsgSendType" BO_ 1412 0;
BA_ "GenMsgCycleTime" BO_ 1159 1000;
BA_ "GenMsgSendType" BO_ 1159 0;
BA_ "GenMsgCycleTime" BO_ 1158 1000;
BA_ "GenMsgSendType" BO_ 1158 0;
BA_ "GenMsgCycleTime" BO_ 1155 1000;
BA_ "GenMsgSendType" BO_ 1155 0;
BA_ "Confidence" SG_ 1297 RCM_a073_eventFactoryMode 1;
BA_ "Confidence" SG_ 1297 RCM_a073_eventDiagEnabled 1;
BA_ "Confidence" SG_ 1297 RCM_a073_eventDriveOrientation 1;
BA_ "Confidence" SG_ 1297 RCM_a073_eventIDFsignal 1;
BA_ "Confidence" SG_ 1297 RCM_a073_eventFrontLeftSeatbelt 1;
BA_ "Confidence" SG_ 1297 RCM_a073_eventFrontRightSeatbelt 1;
BA_ "Confidence" SG_ 1297 RCM_a073_eventVehicleSpeed 1;
BA_ "Confidence" SG_ 1297 RCM_a073_eventSteeringAngle 1;
BA_ "Confidence" SG_ 1297 RCM_a073_eventDriverBrakeApply 1;
BA_ "GenSigSNA" SG_ 1297 RCM_a073_eventDriverBrakeApply "3";
BA_ "Confidence" SG_ 1297 RCM_a073_eventAccelPedalPos 1;
BA_ "GenSigSNA" SG_ 1297 RCM_a073_eventAccelPedalPos "255";
BA_ "Confidence" SG_ 1297 RCM_a074_eventArmStatus 1;
BA_ "Confidence" SG_ 1297 RCM_a074_eventFactoryMode 1;
BA_ "Confidence" SG_ 1297 RCM_a074_eventDiagEnabled 1;
BA_ "Confidence" SG_ 1297 RCM_a074_eventDriveOrientation 1;
BA_ "Confidence" SG_ 1297 RCM_a074_eventIDFsignal 1;
BA_ "Confidence" SG_ 1297 RCM_a074_eventFrontLeftSeatbelt 1;
BA_ "Confidence" SG_ 1297 RCM_a074_eventFrontRightSeatbelt 1;
BA_ "Confidence" SG_ 1297 RCM_a074_eventVehicleSpeed 1;
BA_ "Confidence" SG_ 1297 RCM_a074_eventSteeringAngle 1;
BA_ "Confidence" SG_ 1297 RCM_a074_eventDriverBrakeApply 1;
BA_ "GenSigSNA" SG_ 1297 RCM_a074_eventDriverBrakeApply "3";
BA_ "Confidence" SG_ 1297 RCM_a074_eventAccelPedalPos 1;
BA_ "GenSigSNA" SG_ 1297 RCM_a074_eventAccelPedalPos "255";
BA_ "Confidence" SG_ 1297 RCM_a075_eventArmStatus 1;
BA_ "Confidence" SG_ 1297 RCM_a075_eventFactoryMode 1;
BA_ "Confidence" SG_ 1297 RCM_a075_eventDiagEnabled 1;
BA_ "Confidence" SG_ 1297 RCM_a075_eventDriveOrientation 1;
BA_ "Confidence" SG_ 1297 RCM_a075_eventIDFsignal 1;
BA_ "Confidence" SG_ 1297 RCM_a075_eventFrontLeftSeatbelt 1;
BA_ "Confidence" SG_ 1297 RCM_a075_eventFrontRightSeatbelt 1;
BA_ "Confidence" SG_ 1297 RCM_a075_eventVehicleSpeed 1;
BA_ "Confidence" SG_ 1297 RCM_a075_eventSteeringAngle 1;
BA_ "Confidence" SG_ 1297 RCM_a075_eventDriverBrakeApply 1;
BA_ "GenSigSNA" SG_ 1297 RCM_a075_eventDriverBrakeApply "3";
BA_ "Confidence" SG_ 1297 RCM_a075_eventAccelPedalPos 1;
BA_ "GenSigSNA" SG_ 1297 RCM_a075_eventAccelPedalPos "255";
BA_ "Confidence" SG_ 1297 RCM_a078_eventArmStatus 1;
BA_ "Confidence" SG_ 1297 RCM_a078_eventFactoryMode 1;
BA_ "Confidence" SG_ 1297 RCM_a078_eventDiagEnabled 1;
BA_ "Confidence" SG_ 1297 RCM_a078_eventDriveOrientation 1;
BA_ "Confidence" SG_ 1297 RCM_a078_eventIDFsignal 1;
BA_ "Confidence" SG_ 1297 RCM_a078_eventFrontLeftSeatbelt 1;
BA_ "Confidence" SG_ 1297 RCM_a078_eventFrontRightSeatbelt 1;
BA_ "Confidence" SG_ 1297 RCM_a078_eventVehicleSpeed 1;
BA_ "Confidence" SG_ 1297 RCM_a078_eventSteeringAngle 1;
BA_ "Confidence" SG_ 1297 RCM_a078_eventDriverBrakeApply 1;
BA_ "GenSigSNA" SG_ 1297 RCM_a078_eventDriverBrakeApply "3";
BA_ "Confidence" SG_ 1297 RCM_a078_eventAccelPedalPos 1;
BA_ "GenSigSNA" SG_ 1297 RCM_a078_eventAccelPedalPos "255";
BA_ "Confidence" SG_ 1297 RCM_a079_eventArmStatus 1;
BA_ "Confidence" SG_ 1297 RCM_a079_eventFactoryMode 1;
BA_ "Confidence" SG_ 1297 RCM_a079_eventDiagEnabled 1;
BA_ "Confidence" SG_ 1297 RCM_a079_eventDriveOrientation 1;
BA_ "Confidence" SG_ 1297 RCM_a079_eventIDFsignal 1;
BA_ "Confidence" SG_ 1297 RCM_a079_eventFrontLeftSeatbelt 1;
BA_ "Confidence" SG_ 1297 RCM_a079_eventFrontRightSeatbelt 1;
BA_ "Confidence" SG_ 1297 RCM_a079_eventVehicleSpeed 1;
BA_ "Confidence" SG_ 1297 RCM_a079_eventSteeringAngle 1;
BA_ "Confidence" SG_ 1297 RCM_a079_eventDriverBrakeApply 1;
BA_ "GenSigSNA" SG_ 1297 RCM_a079_eventDriverBrakeApply "3";
BA_ "Confidence" SG_ 1297 RCM_a079_eventAccelPedalPos 1;
BA_ "GenSigSNA" SG_ 1297 RCM_a079_eventAccelPedalPos "255";
BA_ "Confidence" SG_ 1297 RCM_a080_eventArmStatus 1;
BA_ "Confidence" SG_ 1297 RCM_a080_eventFactoryMode 1;
BA_ "Confidence" SG_ 1297 RCM_a080_eventDiagEnabled 1;
BA_ "Confidence" SG_ 1297 RCM_a080_eventDriveOrientation 1;
BA_ "Confidence" SG_ 1297 RCM_a080_eventIDFsignal 1;
BA_ "Confidence" SG_ 1297 RCM_a080_eventFrontLeftSeatbelt 1;
BA_ "Confidence" SG_ 1297 RCM_a080_eventFrontRightSeatbelt 1;
BA_ "Confidence" SG_ 1297 RCM_a080_eventVehicleSpeed 1;
BA_ "Confidence" SG_ 1297 RCM_a080_eventSteeringAngle 1;
BA_ "Confidence" SG_ 1297 RCM_a080_eventDriverBrakeApply 1;
BA_ "GenSigSNA" SG_ 1297 RCM_a080_eventDriverBrakeApply "3";
BA_ "Confidence" SG_ 1297 RCM_a080_eventAccelPedalPos 1;
BA_ "GenSigSNA" SG_ 1297 RCM_a080_eventAccelPedalPos "255";
BA_ "Confidence" SG_ 1297 RCM_a083_eventArmStatus 1;
BA_ "Confidence" SG_ 1297 RCM_a083_eventFactoryMode 1;
BA_ "Confidence" SG_ 1297 RCM_a083_eventDiagEnabled 1;
BA_ "Confidence" SG_ 1297 RCM_a083_eventDriveOrientation 1;
BA_ "Confidence" SG_ 1297 RCM_a083_eventIDFsignal 1;
BA_ "Confidence" SG_ 1297 RCM_a083_eventFrontLeftSeatbelt 1;
BA_ "Confidence" SG_ 1297 RCM_a083_eventFrontRightSeatbelt 1;
BA_ "Confidence" SG_ 1297 RCM_a083_eventVehicleSpeed 1;
BA_ "Confidence" SG_ 1297 RCM_a083_eventSteeringAngle 1;
BA_ "Confidence" SG_ 1297 RCM_a083_eventDriverBrakeApply 1;
BA_ "GenSigSNA" SG_ 1297 RCM_a083_eventDriverBrakeApply "3";
BA_ "Confidence" SG_ 1297 RCM_a083_eventAccelPedalPos 1;
BA_ "GenSigSNA" SG_ 1297 RCM_a083_eventAccelPedalPos "255";
BA_ "Confidence" SG_ 1297 RCM_a087_eventArmStatus 1;
BA_ "Confidence" SG_ 1297 RCM_a087_eventFactoryMode 1;
BA_ "Confidence" SG_ 1297 RCM_a087_eventDiagEnabled 1;
BA_ "Confidence" SG_ 1297 RCM_a087_eventDriveOrientation 1;
BA_ "Confidence" SG_ 1297 RCM_a087_eventIDFsignal 1;
BA_ "Confidence" SG_ 1297 RCM_a087_eventFrontLeftSeatbelt 1;
BA_ "Confidence" SG_ 1297 RCM_a087_eventFrontRightSeatbelt 1;
BA_ "Confidence" SG_ 1297 RCM_a087_eventVehicleSpeed 1;
BA_ "Confidence" SG_ 1297 RCM_a087_eventSteeringAngle 1;
BA_ "Confidence" SG_ 1297 RCM_a087_eventDriverBrakeApply 1;
BA_ "GenSigSNA" SG_ 1297 RCM_a087_eventDriverBrakeApply "3";
BA_ "Confidence" SG_ 1297 RCM_a087_eventAccelPedalPos 1;
BA_ "GenSigSNA" SG_ 1297 RCM_a087_eventAccelPedalPos "255";
BA_ "Confidence" SG_ 1297 RCM_a088_eventArmStatus 1;
BA_ "Confidence" SG_ 1297 RCM_a088_eventFactoryMode 1;
BA_ "Confidence" SG_ 1297 RCM_a088_eventDiagEnabled 1;
BA_ "Confidence" SG_ 1297 RCM_a088_eventDriveOrientation 1;
BA_ "Confidence" SG_ 1297 RCM_a088_eventIDFsignal 1;
BA_ "Confidence" SG_ 1297 RCM_a088_eventFrontLeftSeatbelt 1;
BA_ "Confidence" SG_ 1297 RCM_a088_eventFrontRightSeatbelt 1;
BA_ "Confidence" SG_ 1297 RCM_a088_eventVehicleSpeed 1;
BA_ "Confidence" SG_ 1297 RCM_a088_eventSteeringAngle 1;
BA_ "Confidence" SG_ 1297 RCM_a088_eventDriverBrakeApply 1;
BA_ "GenSigSNA" SG_ 1297 RCM_a088_eventDriverBrakeApply "3";
BA_ "Confidence" SG_ 1297 RCM_a088_eventAccelPedalPos 1;
BA_ "GenSigSNA" SG_ 1297 RCM_a088_eventAccelPedalPos "255";
BA_ "Confidence" SG_ 1297 RCM_a089_eventArmStatus 1;
BA_ "Confidence" SG_ 1297 RCM_a089_eventFactoryMode 1;
BA_ "Confidence" SG_ 1297 RCM_a089_eventDiagEnabled 1;
BA_ "Confidence" SG_ 1297 RCM_a089_eventDriveOrientation 1;
BA_ "Confidence" SG_ 1297 RCM_a089_eventIDFsignal 1;
BA_ "Confidence" SG_ 1297 RCM_a089_eventFrontLeftSeatbelt 1;
BA_ "Confidence" SG_ 1297 RCM_a089_eventFrontRightSeatbelt 1;
BA_ "Confidence" SG_ 1297 RCM_a089_eventVehicleSpeed 1;
BA_ "Confidence" SG_ 1297 RCM_a089_eventSteeringAngle 1;
BA_ "Confidence" SG_ 1297 RCM_a089_eventDriverBrakeApply 1;
BA_ "GenSigSNA" SG_ 1297 RCM_a089_eventDriverBrakeApply "3";
BA_ "Confidence" SG_ 1297 RCM_a089_eventAccelPedalPos 1;
BA_ "GenSigSNA" SG_ 1297 RCM_a089_eventAccelPedalPos "255";
BA_ "Confidence" SG_ 1297 RCM_a090_eventArmStatus 1;
BA_ "Confidence" SG_ 1297 RCM_a090_eventFactoryMode 1;
BA_ "Confidence" SG_ 1297 RCM_a090_eventDiagEnabled 1;
BA_ "Confidence" SG_ 1297 RCM_a090_eventDriveOrientation 1;
BA_ "Confidence" SG_ 1297 RCM_a090_eventIDFsignal 1;
BA_ "Confidence" SG_ 1297 RCM_a090_eventFrontLeftSeatbelt 1;
BA_ "Confidence" SG_ 1297 RCM_a090_eventFrontRightSeatbelt 1;
BA_ "Confidence" SG_ 1297 RCM_a090_eventVehicleSpeed 1;
BA_ "Confidence" SG_ 1297 RCM_a090_eventSteeringAngle 1;
BA_ "Confidence" SG_ 1297 RCM_a090_eventDriverBrakeApply 1;
BA_ "GenSigSNA" SG_ 1297 RCM_a090_eventDriverBrakeApply "3";
BA_ "Confidence" SG_ 1297 RCM_a090_eventAccelPedalPos 1;
BA_ "GenSigSNA" SG_ 1297 RCM_a090_eventAccelPedalPos "255";
BA_ "Confidence" SG_ 1297 RCM_a092_eventArmStatus 1;
BA_ "Confidence" SG_ 1297 RCM_a092_eventFactoryMode 1;
BA_ "Confidence" SG_ 1297 RCM_a092_eventDiagEnabled 1;
BA_ "Confidence" SG_ 1297 RCM_a092_eventDriveOrientation 1;
BA_ "Confidence" SG_ 1297 RCM_a092_eventIDFsignal 1;
BA_ "Confidence" SG_ 1297 RCM_a092_eventFrontLeftSeatbelt 1;
BA_ "Confidence" SG_ 1297 RCM_a092_eventFrontRightSeatbelt 1;
BA_ "Confidence" SG_ 1297 RCM_a092_eventVehicleSpeed 1;
BA_ "Confidence" SG_ 1297 RCM_a092_eventSteeringAngle 1;
BA_ "Confidence" SG_ 1297 RCM_a092_eventDriverBrakeApply 1;
BA_ "GenSigSNA" SG_ 1297 RCM_a092_eventDriverBrakeApply "3";
BA_ "Confidence" SG_ 1297 RCM_a092_eventAccelPedalPos 1;
BA_ "GenSigSNA" SG_ 1297 RCM_a092_eventAccelPedalPos "255";
BA_ "Confidence" SG_ 1297 RCM_a093_eventArmStatus 1;
BA_ "Confidence" SG_ 1297 RCM_a093_eventFactoryMode 1;
BA_ "Confidence" SG_ 1297 RCM_a093_eventDiagEnabled 1;
BA_ "Confidence" SG_ 1297 RCM_a093_eventDriveOrientation 1;
BA_ "Confidence" SG_ 1297 RCM_a093_eventIDFsignal 1;
BA_ "Confidence" SG_ 1297 RCM_a093_eventFrontLeftSeatbelt 1;
BA_ "Confidence" SG_ 1297 RCM_a093_eventFrontRightSeatbelt 1;
BA_ "Confidence" SG_ 1297 RCM_a093_eventVehicleSpeed 1;
BA_ "Confidence" SG_ 1297 RCM_a093_eventSteeringAngle 1;
BA_ "Confidence" SG_ 1297 RCM_a093_eventDriverBrakeApply 1;
BA_ "GenSigSNA" SG_ 1297 RCM_a093_eventDriverBrakeApply "3";
BA_ "Confidence" SG_ 1297 RCM_a093_eventAccelPedalPos 1;
BA_ "GenSigSNA" SG_ 1297 RCM_a093_eventAccelPedalPos "255";
BA_ "Confidence" SG_ 1297 RCM_a094_eventArmStatus 1;
BA_ "Confidence" SG_ 1297 RCM_a094_eventFactoryMode 1;
BA_ "Confidence" SG_ 1297 RCM_a094_eventDiagEnabled 1;
BA_ "Confidence" SG_ 1297 RCM_a094_eventDriveOrientation 1;
BA_ "Confidence" SG_ 1297 RCM_a094_eventIDFsignal 1;
BA_ "Confidence" SG_ 1297 RCM_a094_eventFrontLeftSeatbelt 1;
BA_ "Confidence" SG_ 1297 RCM_a094_eventFrontRightSeatbelt 1;
BA_ "Confidence" SG_ 1297 RCM_a094_eventVehicleSpeed 1;
BA_ "Confidence" SG_ 1297 RCM_a094_eventSteeringAngle 1;
BA_ "Confidence" SG_ 1297 RCM_a094_eventDriverBrakeApply 1;
BA_ "GenSigSNA" SG_ 1297 RCM_a094_eventDriverBrakeApply "3";
BA_ "Confidence" SG_ 1297 RCM_a094_eventAccelPedalPos 1;
BA_ "GenSigSNA" SG_ 1297 RCM_a094_eventAccelPedalPos "255";
BA_ "Confidence" SG_ 1297 RCM_a101_eventArmStatus 1;
BA_ "Confidence" SG_ 1297 RCM_a101_eventFactoryMode 1;
BA_ "Confidence" SG_ 1297 RCM_a101_eventDiagEnabled 1;
BA_ "Confidence" SG_ 1297 RCM_a101_eventDriveOrientation 1;
BA_ "Confidence" SG_ 1297 RCM_a101_eventIDFsignal 1;
BA_ "Confidence" SG_ 1297 RCM_a101_eventFrontLeftSeatbelt 1;
BA_ "Confidence" SG_ 1297 RCM_a101_eventFrontRightSeatbelt 1;
BA_ "Confidence" SG_ 1297 RCM_a101_eventVehicleSpeed 1;
BA_ "Confidence" SG_ 1297 RCM_a101_eventSteeringAngle 1;
BA_ "Confidence" SG_ 1297 RCM_a101_eventDriverBrakeApply 1;
BA_ "GenSigSNA" SG_ 1297 RCM_a101_eventDriverBrakeApply "3";
BA_ "Confidence" SG_ 1297 RCM_a101_eventAccelPedalPos 1;
BA_ "GenSigSNA" SG_ 1297 RCM_a101_eventAccelPedalPos "255";
BA_ "Confidence" SG_ 1297 RCM_a102_eventArmStatus 1;
BA_ "Confidence" SG_ 1297 RCM_a102_eventFactoryMode 1;
BA_ "Confidence" SG_ 1297 RCM_a102_eventDiagEnabled 1;
BA_ "Confidence" SG_ 1297 RCM_a102_eventDriveOrientation 1;
BA_ "Confidence" SG_ 1297 RCM_a102_eventIDFsignal 1;
BA_ "Confidence" SG_ 1297 RCM_a102_eventFrontLeftSeatbelt 1;
BA_ "Confidence" SG_ 1297 RCM_a102_eventFrontRightSeatbelt 1;
BA_ "Confidence" SG_ 1297 RCM_a102_eventVehicleSpeed 1;
BA_ "Confidence" SG_ 1297 RCM_a102_eventSteeringAngle 1;
BA_ "Confidence" SG_ 1297 RCM_a102_eventDriverBrakeApply 1;
BA_ "GenSigSNA" SG_ 1297 RCM_a102_eventDriverBrakeApply "3";
BA_ "Confidence" SG_ 1297 RCM_a102_eventAccelPedalPos 1;
BA_ "GenSigSNA" SG_ 1297 RCM_a102_eventAccelPedalPos "255";
BA_ "Confidence" SG_ 1297 RCM_a103_eventArmStatus 1;
BA_ "Confidence" SG_ 1297 RCM_a103_eventFactoryMode 1;
BA_ "Confidence" SG_ 1297 RCM_a103_eventDiagEnabled 1;
BA_ "Confidence" SG_ 1297 RCM_a103_eventDriveOrientation 1;
BA_ "Confidence" SG_ 1297 RCM_a103_eventIDFsignal 1;
BA_ "Confidence" SG_ 1297 RCM_a103_eventFrontLeftSeatbelt 1;
BA_ "Confidence" SG_ 1297 RCM_a103_eventFrontRightSeatbelt 1;
BA_ "Confidence" SG_ 1297 RCM_a103_eventVehicleSpeed 1;
BA_ "Confidence" SG_ 1297 RCM_a103_eventSteeringAngle 1;
BA_ "Confidence" SG_ 1297 RCM_a103_eventDriverBrakeApply 1;
BA_ "GenSigSNA" SG_ 1297 RCM_a103_eventDriverBrakeApply "3";
BA_ "Confidence" SG_ 1297 RCM_a103_eventAccelPedalPos 1;
BA_ "GenSigSNA" SG_ 1297 RCM_a103_eventAccelPedalPos "255";
BA_ "Confidence" SG_ 1297 RCM_a104_eventArmStatus 1;
BA_ "Confidence" SG_ 1297 RCM_a104_eventFactoryMode 1;
BA_ "Confidence" SG_ 1297 RCM_a104_eventDiagEnabled 1;
BA_ "Confidence" SG_ 1297 RCM_a104_eventDriveOrientation 1;
BA_ "Confidence" SG_ 1297 RCM_a104_eventIDFsignal 1;
BA_ "Confidence" SG_ 1297 RCM_a104_eventFrontLeftSeatbelt 1;
BA_ "Confidence" SG_ 1297 RCM_a104_eventFrontRightSeatbelt 1;
BA_ "Confidence" SG_ 1297 RCM_a104_eventVehicleSpeed 1;
BA_ "Confidence" SG_ 1297 RCM_a104_eventSteeringAngle 1;
BA_ "Confidence" SG_ 1297 RCM_a104_eventDriverBrakeApply 1;
BA_ "GenSigSNA" SG_ 1297 RCM_a104_eventDriverBrakeApply "3";
BA_ "Confidence" SG_ 1297 RCM_a104_eventAccelPedalPos 1;
BA_ "GenSigSNA" SG_ 1297 RCM_a104_eventAccelPedalPos "255";
BA_ "Confidence" SG_ 1297 RCM_a105_eventArmStatus 1;
BA_ "Confidence" SG_ 1297 RCM_a105_eventFactoryMode 1;
BA_ "Confidence" SG_ 1297 RCM_a105_eventDiagEnabled 1;
BA_ "Confidence" SG_ 1297 RCM_a105_eventDriveOrientation 1;
BA_ "Confidence" SG_ 1297 RCM_a105_eventIDFsignal 1;
BA_ "Confidence" SG_ 1297 RCM_a105_eventFrontLeftSeatbelt 1;
BA_ "Confidence" SG_ 1297 RCM_a105_eventFrontRightSeatbelt 1;
BA_ "Confidence" SG_ 1297 RCM_a105_eventVehicleSpeed 1;
BA_ "Confidence" SG_ 1297 RCM_a105_eventSteeringAngle 1;
BA_ "Confidence" SG_ 1297 RCM_a105_eventDriverBrakeApply 1;
BA_ "GenSigSNA" SG_ 1297 RCM_a105_eventDriverBrakeApply "3";
BA_ "Confidence" SG_ 1297 RCM_a105_eventAccelPedalPos 1;
BA_ "GenSigSNA" SG_ 1297 RCM_a105_eventAccelPedalPos "255";
BA_ "Confidence" SG_ 1297 RCM_a106_eventArmStatus 1;
BA_ "Confidence" SG_ 1297 RCM_a106_eventFactoryMode 1;
BA_ "Confidence" SG_ 1297 RCM_a106_eventDiagEnabled 1;
BA_ "Confidence" SG_ 1297 RCM_a106_eventDriveOrientation 1;
BA_ "Confidence" SG_ 1297 RCM_a106_eventIDFsignal 1;
BA_ "Confidence" SG_ 1297 RCM_a106_eventFrontLeftSeatbelt 1;
BA_ "Confidence" SG_ 1297 RCM_a106_eventFrontRightSeatbelt 1;
BA_ "Confidence" SG_ 1297 RCM_a106_eventVehicleSpeed 1;
BA_ "Confidence" SG_ 1297 RCM_a106_eventSteeringAngle 1;
BA_ "Confidence" SG_ 1297 RCM_a106_eventDriverBrakeApply 1;
BA_ "GenSigSNA" SG_ 1297 RCM_a106_eventDriverBrakeApply "3";
BA_ "Confidence" SG_ 1297 RCM_a106_eventAccelPedalPos 1;
BA_ "GenSigSNA" SG_ 1297 RCM_a106_eventAccelPedalPos "255";
BA_ "Confidence" SG_ 1297 RCM_a107_eventArmStatus 1;
BA_ "Confidence" SG_ 1297 RCM_a107_eventFactoryMode 1;
BA_ "Confidence" SG_ 1297 RCM_a107_eventDiagEnabled 1;
BA_ "Confidence" SG_ 1297 RCM_a107_eventDriveOrientation 1;
BA_ "Confidence" SG_ 1297 RCM_a107_eventIDFsignal 1;
BA_ "Confidence" SG_ 1297 RCM_a107_eventFrontLeftSeatbelt 1;
BA_ "Confidence" SG_ 1297 RCM_a107_eventFrontRightSeatbelt 1;
BA_ "Confidence" SG_ 1297 RCM_a107_eventVehicleSpeed 1;
BA_ "Confidence" SG_ 1297 RCM_a107_eventSteeringAngle 1;
BA_ "Confidence" SG_ 1297 RCM_a107_eventDriverBrakeApply 1;
BA_ "GenSigSNA" SG_ 1297 RCM_a107_eventDriverBrakeApply "3";
BA_ "Confidence" SG_ 1297 RCM_a107_eventAccelPedalPos 1;
BA_ "GenSigSNA" SG_ 1297 RCM_a107_eventAccelPedalPos "255";
BA_ "Confidence" SG_ 1297 RCM_a108_eventArmStatus 1;
BA_ "Confidence" SG_ 1297 RCM_a108_eventFactoryMode 1;
BA_ "Confidence" SG_ 1297 RCM_a108_eventDiagEnabled 1;
BA_ "Confidence" SG_ 1297 RCM_a108_eventDriveOrientation 1;
BA_ "Confidence" SG_ 1297 RCM_a108_eventIDFsignal 1;
BA_ "Confidence" SG_ 1297 RCM_a108_eventFrontLeftSeatbelt 1;
BA_ "Confidence" SG_ 1297 RCM_a108_eventFrontRightSeatbelt 1;
BA_ "Confidence" SG_ 1297 RCM_a108_eventVehicleSpeed 1;
BA_ "Confidence" SG_ 1297 RCM_a108_eventSteeringAngle 1;
BA_ "Confidence" SG_ 1297 RCM_a108_eventDriverBrakeApply 1;
BA_ "GenSigSNA" SG_ 1297 RCM_a108_eventDriverBrakeApply "3";
BA_ "Confidence" SG_ 1297 RCM_a108_eventAccelPedalPos 1;
BA_ "GenSigSNA" SG_ 1297 RCM_a108_eventAccelPedalPos "255";
BA_ "Confidence" SG_ 1297 RCM_a109_eventArmStatus 1;
BA_ "Confidence" SG_ 1297 RCM_a109_eventFactoryMode 1;
BA_ "Confidence" SG_ 1297 RCM_a109_eventDiagEnabled 1;
BA_ "Confidence" SG_ 1297 RCM_a109_eventDriveOrientation 1;
BA_ "Confidence" SG_ 1297 RCM_a109_eventIDFsignal 1;
BA_ "Confidence" SG_ 1297 RCM_a109_eventFrontLeftSeatbelt 1;
BA_ "Confidence" SG_ 1297 RCM_a109_eventFrontRightSeatbelt 1;
BA_ "Confidence" SG_ 1297 RCM_a109_eventVehicleSpeed 1;
BA_ "Confidence" SG_ 1297 RCM_a109_eventSteeringAngle 1;
BA_ "Confidence" SG_ 1297 RCM_a109_eventDriverBrakeApply 1;
BA_ "GenSigSNA" SG_ 1297 RCM_a109_eventDriverBrakeApply "3";
BA_ "Confidence" SG_ 1297 RCM_a109_eventAccelPedalPos 1;
BA_ "GenSigSNA" SG_ 1297 RCM_a109_eventAccelPedalPos "255";
BA_ "Confidence" SG_ 1297 RCM_a110_eventArmStatus 1;
BA_ "Confidence" SG_ 1297 RCM_a110_eventFactoryMode 1;
BA_ "Confidence" SG_ 1297 RCM_a110_eventDiagEnabled 1;
BA_ "Confidence" SG_ 1297 RCM_a110_eventDriveOrientation 1;
BA_ "Confidence" SG_ 1297 RCM_a110_eventIDFsignal 1;
BA_ "Confidence" SG_ 1297 RCM_a110_eventFrontLeftSeatbelt 1;
BA_ "Confidence" SG_ 1297 RCM_a110_eventFrontRightSeatbelt 1;
BA_ "Confidence" SG_ 1297 RCM_a110_eventVehicleSpeed 1;
BA_ "Confidence" SG_ 1297 RCM_a110_eventSteeringAngle 1;
BA_ "Confidence" SG_ 1297 RCM_a110_eventDriverBrakeApply 1;
BA_ "GenSigSNA" SG_ 1297 RCM_a110_eventDriverBrakeApply "3";
BA_ "Confidence" SG_ 1297 RCM_a110_eventAccelPedalPos 1;
BA_ "GenSigSNA" SG_ 1297 RCM_a110_eventAccelPedalPos "255";
BA_ "Confidence" SG_ 1297 RCM_a112_eventArmStatus 1;
BA_ "Confidence" SG_ 1297 RCM_a112_eventFactoryMode 1;
BA_ "Confidence" SG_ 1297 RCM_a112_eventDiagEnabled 1;
BA_ "Confidence" SG_ 1297 RCM_a112_eventDriveOrientation 1;
BA_ "Confidence" SG_ 1297 RCM_a112_eventIDFsignal 1;
BA_ "Confidence" SG_ 1297 RCM_a112_eventFrontLeftSeatbelt 1;
BA_ "Confidence" SG_ 1297 RCM_a112_eventFrontRightSeatbelt 1;
BA_ "Confidence" SG_ 1297 RCM_a112_eventVehicleSpeed 1;
BA_ "Confidence" SG_ 1297 RCM_a112_eventSteeringAngle 1;
BA_ "Confidence" SG_ 1297 RCM_a112_eventDriverBrakeApply 1;
BA_ "GenSigSNA" SG_ 1297 RCM_a112_eventDriverBrakeApply "3";
BA_ "Confidence" SG_ 1297 RCM_a112_eventAccelPedalPos 1;
BA_ "GenSigSNA" SG_ 1297 RCM_a112_eventAccelPedalPos "255";
BA_ "Confidence" SG_ 1297 RCM_a113_eventArmStatus 1;
BA_ "Confidence" SG_ 1297 RCM_a113_eventFactoryMode 1;
BA_ "Confidence" SG_ 1297 RCM_a113_eventDiagEnabled 1;
BA_ "Confidence" SG_ 1297 RCM_a113_eventDriveOrientation 1;
BA_ "Confidence" SG_ 1297 RCM_a113_eventIDFsignal 1;
BA_ "Confidence" SG_ 1297 RCM_a113_eventFrontLeftSeatbelt 1;
BA_ "Confidence" SG_ 1297 RCM_a113_eventFrontRightSeatbelt 1;
BA_ "Confidence" SG_ 1297 RCM_a113_eventVehicleSpeed 1;
BA_ "Confidence" SG_ 1297 RCM_a113_eventSteeringAngle 1;
BA_ "Confidence" SG_ 1297 RCM_a113_eventDriverBrakeApply 1;
BA_ "GenSigSNA" SG_ 1297 RCM_a113_eventDriverBrakeApply "3";
BA_ "Confidence" SG_ 1297 RCM_a113_eventAccelPedalPos 1;
BA_ "GenSigSNA" SG_ 1297 RCM_a113_eventAccelPedalPos "255";
BA_ "Confidence" SG_ 1297 RCM_a114_eventArmStatus 1;
BA_ "Confidence" SG_ 1297 RCM_a114_eventFactoryMode 1;
BA_ "Confidence" SG_ 1297 RCM_a114_eventDiagEnabled 1;
BA_ "Confidence" SG_ 1297 RCM_a114_eventDriveOrientation 1;
BA_ "Confidence" SG_ 1297 RCM_a114_eventIDFsignal 1;
BA_ "Confidence" SG_ 1297 RCM_a114_eventFrontLeftSeatbelt 1;
BA_ "Confidence" SG_ 1297 RCM_a114_eventFrontRightSeatbelt 1;
BA_ "Confidence" SG_ 1297 RCM_a114_eventVehicleSpeed 1;
BA_ "Confidence" SG_ 1297 RCM_a114_eventSteeringAngle 1;
BA_ "Confidence" SG_ 1297 RCM_a114_eventDriverBrakeApply 1;
BA_ "GenSigSNA" SG_ 1297 RCM_a114_eventDriverBrakeApply "3";
BA_ "Confidence" SG_ 1297 RCM_a114_eventAccelPedalPos 1;
BA_ "GenSigSNA" SG_ 1297 RCM_a114_eventAccelPedalPos "255";
BA_ "Confidence" SG_ 1297 RCM_a115_eventArmStatus 1;
BA_ "Confidence" SG_ 1297 RCM_a115_eventFactoryMode 1;
BA_ "Confidence" SG_ 1297 RCM_a115_eventDiagEnabled 1;
BA_ "Confidence" SG_ 1297 RCM_a115_eventDriveOrientation 1;
BA_ "Confidence" SG_ 1297 RCM_a115_eventIDFsignal 1;
BA_ "Confidence" SG_ 1297 RCM_a115_eventFrontLeftSeatbelt 1;
BA_ "Confidence" SG_ 1297 RCM_a115_eventFrontRightSeatbelt 1;
BA_ "Confidence" SG_ 1297 RCM_a115_eventVehicleSpeed 1;
BA_ "Confidence" SG_ 1297 RCM_a115_eventSteeringAngle 1;
BA_ "Confidence" SG_ 1297 RCM_a115_eventDriverBrakeApply 1;
BA_ "GenSigSNA" SG_ 1297 RCM_a115_eventDriverBrakeApply "3";
BA_ "Confidence" SG_ 1297 RCM_a115_eventAccelPedalPos 1;
BA_ "GenSigSNA" SG_ 1297 RCM_a115_eventAccelPedalPos "255";
BA_ "Confidence" SG_ 1297 RCM_a116_eventArmStatus 1;
BA_ "Confidence" SG_ 1297 RCM_a116_eventFactoryMode 1;
BA_ "Confidence" SG_ 1297 RCM_a116_eventDiagEnabled 1;
BA_ "Confidence" SG_ 1297 RCM_a116_eventDriveOrientation 1;
BA_ "Confidence" SG_ 1297 RCM_a116_eventIDFsignal 1;
BA_ "Confidence" SG_ 1297 RCM_a116_eventFrontLeftSeatbelt 1;
BA_ "Confidence" SG_ 1297 RCM_a116_eventFrontRightSeatbelt 1;
BA_ "Confidence" SG_ 1297 RCM_a116_eventVehicleSpeed 1;
BA_ "Confidence" SG_ 1297 RCM_a116_eventSteeringAngle 1;
BA_ "Confidence" SG_ 1297 RCM_a116_eventDriverBrakeApply 1;
BA_ "GenSigSNA" SG_ 1297 RCM_a116_eventDriverBrakeApply "3";
BA_ "Confidence" SG_ 1297 RCM_a116_eventAccelPedalPos 1;
BA_ "GenSigSNA" SG_ 1297 RCM_a116_eventAccelPedalPos "255";
BA_ "Confidence" SG_ 1297 RCM_a117_eventArmStatus 1;
BA_ "Confidence" SG_ 1297 RCM_a117_eventFactoryMode 1;
BA_ "Confidence" SG_ 1297 RCM_a117_eventDiagEnabled 1;
BA_ "Confidence" SG_ 1297 RCM_a117_eventDriveOrientation 1;
BA_ "Confidence" SG_ 1297 RCM_a117_eventIDFsignal 1;
BA_ "Confidence" SG_ 1297 RCM_a117_eventFrontLeftSeatbelt 1;
BA_ "Confidence" SG_ 1297 RCM_a117_eventFrontRightSeatbelt 1;
BA_ "Confidence" SG_ 1297 RCM_a117_eventVehicleSpeed 1;
BA_ "Confidence" SG_ 1297 RCM_a117_eventSteeringAngle 1;
BA_ "Confidence" SG_ 1297 RCM_a117_eventDriverBrakeApply 1;
BA_ "GenSigSNA" SG_ 1297 RCM_a117_eventDriverBrakeApply "3";
BA_ "Confidence" SG_ 1297 RCM_a117_eventAccelPedalPos 1;
BA_ "GenSigSNA" SG_ 1297 RCM_a117_eventAccelPedalPos "255";
BA_ "Confidence" SG_ 1297 RCM_a118_eventArmStatus 1;
BA_ "Confidence" SG_ 1297 RCM_a118_eventFactoryMode 1;
BA_ "Confidence" SG_ 1297 RCM_a118_eventDiagEnabled 1;
BA_ "Confidence" SG_ 1297 RCM_a118_eventDriveOrientation 1;
BA_ "Confidence" SG_ 1297 RCM_a118_eventIDFsignal 1;
BA_ "Confidence" SG_ 1297 RCM_a118_eventFrontLeftSeatbelt 1;
BA_ "Confidence" SG_ 1297 RCM_a118_eventFrontRightSeatbelt 1;
BA_ "Confidence" SG_ 1297 RCM_a118_eventVehicleSpeed 1;
BA_ "Confidence" SG_ 1297 RCM_a118_eventSteeringAngle 1;
BA_ "Confidence" SG_ 1297 RCM_a118_eventDriverBrakeApply 1;
BA_ "GenSigSNA" SG_ 1297 RCM_a118_eventDriverBrakeApply "3";
BA_ "Confidence" SG_ 1297 RCM_a118_eventAccelPedalPos 1;
BA_ "GenSigSNA" SG_ 1297 RCM_a118_eventAccelPedalPos "255";
BA_ "Confidence" SG_ 881 RCM_matrixIndex 1;
BA_ "Confidence" SG_ 1471 RCU_alertID 1;
BA_ "Confidence" SG_ 1471 RCU_alertState 1;
BA_ "Confidence" SG_ 1471 RCU_a010_sensorPowerSupply 1;
BA_ "Confidence" SG_ 1471 RCU_a010_sensorHardware 1;
BA_ "Confidence" SG_ 1471 RCU_a010_sensorSignal 1;
BA_ "Confidence" SG_ 1471 RCU_a023_validityOnChassisBus 1;
BA_ "Confidence" SG_ 1471 RCU_a023_validityOnPartyBus 1;
BA_ "Confidence" SG_ 1471 RCU_a024_validityOnChassisBus 1;
BA_ "Confidence" SG_ 1471 RCU_a024_validityOnPartyBus 1;
BA_ "Confidence" SG_ 1471 RCU_a025_validityOnChassisBus 1;
BA_ "Confidence" SG_ 1471 RCU_a025_validityOnPartyBus 1;
BA_ "Confidence" SG_ 1471 RCU_a035_validityOnChassisBus 1;
BA_ "Confidence" SG_ 1471 RCU_a035_validityOnPartyBus 1;
BA_ "Confidence" SG_ 1471 RCU_a036_validityOnChassisBus 1;
BA_ "Confidence" SG_ 1471 RCU_a036_validityOnPartyBus 1;
BA_ "Confidence" SG_ 998 RCU_matrixIndex 1;
BA_ "SystemSignalLongSymbol" SG_ 998 RCU_a033_VCFRONTLVPowerStateChec "RCU_a033_VCFRONTLVPowerStateChecksum";
BA_ "SystemSignalLongSymbol" SG_ 998 RCU_a034_VCFRONTLVPowerStateCoun "RCU_a034_VCFRONTLVPowerStateCounter";
BA_ "SystemSignalLongSymbol" SG_ 998 RCU_a037_IDBinputRodStrokeInvali "RCU_a037_IDBinputRodStrokeInvalid";
BA_ "SystemSignalLongSymbol" SG_ 998 RCU_a043_VCFRONTiBoosterLvStateI "RCU_a043_VCFRONTiBoosterLvStateInvalid";
BA_ "SystemSignalLongSymbol" SG_ 998 RCU_a055_IDBsimulatorPressFaulte "RCU_a055_IDBsimulatorPressFaulted";
BA_ "SystemSignalLongSymbol" SG_ 998 RCU_a056_redundantControllerIsMa "RCU_a056_redundantControllerIsMaster";
BA_ "SystemSignalLongSymbol" SG_ 998 RCU_a057_DASredundantBrakingCont "RCU_a057_DASredundantBrakingControlDLC";
BA_ "SystemSignalLongSymbol" SG_ 998 RCU_a058_DASredundantBrakingCont "RCU_a058_DASredundantBrakingControlCounter";
BA_ "SystemSignalLongSymbol" SG_ 998 RCU_a059_DASredundantBrakingCont "RCU_a059_DASredundantBrakingControlChecksum";
BA_ "SystemSignalLongSymbol" SG_ 998 RCU_a060_DASbrakeTorqueCommandIn "RCU_a060_DASbrakeTorqueCommandInvalid";
BA_ "SystemSignalLongSymbol" SG_ 998 RCU_a064_ESPredundantBrakingStat "RCU_a064_ESPredundantBrakingStatusDLC";
BA_ "SystemSignalLongSymbol" SG_ 998 RCU_a065_ESPredundantBrakingStat "RCU_a065_ESPredundantBrakingStatusCounter";
BA_ "SystemSignalLongSymbol" SG_ 998 RCU_a066_ESPredundantBrakingStat "RCU_a066_ESPredundantBrakingStatusChecksum";
BA_ "Confidence" SG_ 831 RCU_infoIndex 1;
BA_ "Confidence" SG_ 831 RCU_infoPcbaID 0;
BA_ "Confidence" SG_ 831 RCU_infoAssemblyID 0;
BA_ "Confidence" SG_ 831 RCU_infoUsageID 0;
BA_ "Confidence" SG_ 831 RCU_infoSubUsageID 0;
BA_ "Confidence" SG_ 1415 TCU2_tc10Version 0;
BA_ "GenSigSNA" SG_ 1415 TCU2_tc10Version "0";
BA_ "Confidence" SG_ 1413 TCU2_alertID 1;
BA_ "Confidence" SG_ 1413 TCU2_alertState 1;
BA_ "Confidence" SG_ 1413 TCU2_w012_DataRAT 1;
BA_ "Confidence" SG_ 1413 TCU2_w012_RSRP 1;
BA_ "Confidence" SG_ 1413 TCU2_w012_RSRQ 1;
BA_ "Confidence" SG_ 1413 TCU2_w012_AvgQueueUsage 1;
BA_ "Confidence" SG_ 1413 TCU2_w012_NSAAvailable 1;
BA_ "Confidence" SG_ 1413 TCU2_w013_DataRAT 1;
BA_ "Confidence" SG_ 1413 TCU2_w013_RSRP 1;
BA_ "Confidence" SG_ 1413 TCU2_w013_RSRQ 1;
BA_ "Confidence" SG_ 1413 TCU2_w013_AvgQueueUsage 1;
BA_ "Confidence" SG_ 1413 TCU2_w013_NSAAvailable 1;
BA_ "Confidence" SG_ 1412 TCU2_logMux 1;
BA_ "Confidence" SG_ 1412 TCU2_cpuTemp 0;
BA_ "Confidence" SG_ 1412 TCU2_cpuUsage 0;
BA_ "Confidence" SG_ 1412 TCU2_mdmCoreTemperature 0;
BA_ "Confidence" SG_ 1412 TCU2_availableMemory 0;
BA_ "Confidence" SG_ 1412 TCU2_pwm 0;
BA_ "Confidence" SG_ 1412 TCU2_pwmcap 0;
BA_ "Confidence" SG_ 1412 TCU2_totalResumes 0;
BA_ "Confidence" SG_ 1412 TCU2_mdmUplinkQueueSize 0;
BA_ "Confidence" SG_ 1412 TCU2_mdmRSRP 0;
BA_ "Confidence" SG_ 1412 TCU2_mdmSINR 0;
BA_ "Confidence" SG_ 1412 TCU2_mdmUplinkAllowedRate 0;
BA_ "Confidence" SG_ 1412 TCU2_mdmUplinkAvgRate 0;
BA_ "Confidence" SG_ 1412 TCU2_mdmServiceState 0;
BA_ "Confidence" SG_ 1412 TCU2_mdmIMSStatus 0;
BA_ "Confidence" SG_ 1412 TCU2_mdmSIMStatus 0;
BA_ "Confidence" SG_ 1412 TCU2_mdmBusyActive 0;
BA_ "GenSigSNA" SG_ 1412 TCU2_mdmBusyActive "4294967295";
BA_ "Confidence" SG_ 1412 TCU2_modemUptime 0;
BA_ "Confidence" SG_ 1412 TCU2_mdmDataRat 0;
BA_ "Confidence" SG_ 1412 TCU2_mdmDataCallStatus 0;
BA_ "Confidence" SG_ 1412 TCU2_mdmNSAAvailable 0;
BA_ "Confidence" SG_ 1412 TCU2_mdmPCIID 0;
BA_ "Confidence" SG_ 1412 TCU2_mdmMnc 0;
BA_ "Confidence" SG_ 1412 TCU2_mdmMcc 0;
BA_ "Confidence" SG_ 1412 TCU2_mdmTxKiloBytes 0;
BA_ "Confidence" SG_ 1412 TCU2_mdmDataCallTermReason 0;
BA_ "Confidence" SG_ 1412 TCU2_mdmDataCallTermCode 0;
BA_ "Confidence" SG_ 1412 TCU2_cellularSMState 0;
BA_ "Confidence" SG_ 1412 TCU2_tcuSMState 0;
BA_ "Confidence" SG_ 1412 TCU2_checkInternetFailCount 0;
BA_ "Confidence" SG_ 1412 TCU2_mdmBand 0;
BA_ "Confidence" SG_ 1412 TCU2_wakeSource 0;
BA_ "Confidence" SG_ 1159 TCU_tc10Version 0;
BA_ "GenSigSNA" SG_ 1159 TCU_tc10Version "0";
BA_ "Confidence" SG_ 1157 TCU_alertID 1;
BA_ "Confidence" SG_ 1157 TCU_alertState 1;
BA_ "Confidence" SG_ 1157 TCU_w012_DataRAT 1;
BA_ "Confidence" SG_ 1157 TCU_w012_RSRP 1;
BA_ "Confidence" SG_ 1157 TCU_w012_RSRQ 1;
BA_ "Confidence" SG_ 1157 TCU_w012_AvgQueueUsage 1;
BA_ "Confidence" SG_ 1157 TCU_w012_NSAAvailable 1;
BA_ "Confidence" SG_ 1157 TCU_w013_DataRAT 1;
BA_ "Confidence" SG_ 1157 TCU_w013_RSRP 1;
BA_ "Confidence" SG_ 1157 TCU_w013_RSRQ 1;
BA_ "Confidence" SG_ 1157 TCU_w013_AvgQueueUsage 1;
BA_ "Confidence" SG_ 1157 TCU_w013_NSAAvailable 1;
BA_ "Confidence" SG_ 1155 TCU_logMux 1;
BA_ "Confidence" SG_ 1155 TCU_cpuTemp 0;
BA_ "Confidence" SG_ 1155 TCU_cpuUsage 0;
BA_ "Confidence" SG_ 1155 TCU_mdmCoreTemperature 0;
BA_ "Confidence" SG_ 1155 TCU_availableMemory 0;
BA_ "Confidence" SG_ 1155 TCU_pwm 0;
BA_ "Confidence" SG_ 1155 TCU_pwmcap 0;
BA_ "Confidence" SG_ 1155 TCU_totalResumes 0;
BA_ "Confidence" SG_ 1155 TCU_mdmUplinkQueueSize 0;
BA_ "Confidence" SG_ 1155 TCU_mdmRSRP 0;
BA_ "Confidence" SG_ 1155 TCU_mdmSINR 0;
BA_ "Confidence" SG_ 1155 TCU_mdmUplinkAllowedRate 0;
BA_ "Confidence" SG_ 1155 TCU_mdmUplinkAvgRate 0;
BA_ "Confidence" SG_ 1155 TCU_mdmServiceState 0;
BA_ "Confidence" SG_ 1155 TCU_mdmIMSStatus 0;
BA_ "Confidence" SG_ 1155 TCU_mdmSIMStatus 0;
BA_ "Confidence" SG_ 1155 TCU_mdmBusyActive 0;
BA_ "GenSigSNA" SG_ 1155 TCU_mdmBusyActive "4294967295";
BA_ "Confidence" SG_ 1155 TCU_modemUptime 0;
BA_ "Confidence" SG_ 1155 TCU_mdmDataRat 0;
BA_ "Confidence" SG_ 1155 TCU_mdmDataCallStatus 0;
BA_ "Confidence" SG_ 1155 TCU_mdmNSAAvailable 0;
BA_ "Confidence" SG_ 1155 TCU_mdmPCIID 0;
BA_ "Confidence" SG_ 1155 TCU_mdmMnc 0;
BA_ "Confidence" SG_ 1155 TCU_mdmMcc 0;
BA_ "Confidence" SG_ 1155 TCU_mdmTxKiloBytes 0;
BA_ "Confidence" SG_ 1155 TCU_mdmDataCallTermReason 0;
BA_ "Confidence" SG_ 1155 TCU_mdmDataCallTermCode 0;
BA_ "Confidence" SG_ 1155 TCU_cellularSMState 0;
BA_ "Confidence" SG_ 1155 TCU_tcuSMState 0;
BA_ "Confidence" SG_ 1155 TCU_checkInternetFailCount 0;
BA_ "Confidence" SG_ 1155 TCU_mdmBand 0;
BA_ "Confidence" SG_ 1155 TCU_wakeSource 0;
BA_ "Confidence" SG_ 1603 UDS_ocs1pRequestData 1;
BA_ "Confidence" SG_ 1551 UDS_thcRequestData_H 1;
BA_ "Confidence" SG_ 1551 UDS_thcRequestData_L 1;
VAL_ 1297 RCM_a073_eventFactoryMode 1 "ENABLED" 0 "DISABLED" ;
VAL_ 1297 RCM_a073_eventDiagEnabled 1 "ENABLED" 0 "DISABLED" ;
VAL_ 1297 RCM_a073_eventDriveOrientation 1 "RIGHT_HAND_DRIVE" 0 "LEFT_HAND_DRIVE" ;
VAL_ 1297 RCM_a073_eventIDFsignal 1 "ACTIVE" 0 "NOT_ACTIVE" ;
VAL_ 1297 RCM_a073_eventFrontLeftSeatbelt 1 "LATCHED" 0 "UNLATCHED" ;
VAL_ 1297 RCM_a073_eventFrontRightSeatbelt 1 "LATCHED" 0 "UNLATCHED" ;
VAL_ 1297 RCM_a073_eventDriverBrakeApply 3 "Faulty_SNA" 2 "Driver_applying_brakes" 1 "Not_Applied" 0 "NotInit_orOff" ;
VAL_ 1297 RCM_a073_eventAccelPedalPos 255 "SNA" ;
VAL_ 1297 RCM_a074_eventArmStatus 1 "ARMED" 0 "UNARMED" ;
VAL_ 1297 RCM_a074_eventFactoryMode 1 "ENABLED" 0 "DISABLED" ;
VAL_ 1297 RCM_a074_eventDiagEnabled 1 "ENABLED" 0 "DISABLED" ;
VAL_ 1297 RCM_a074_eventDriveOrientation 1 "RIGHT_HAND_DRIVE" 0 "LEFT_HAND_DRIVE" ;
VAL_ 1297 RCM_a074_eventIDFsignal 1 "ACTIVE" 0 "NOT_ACTIVE" ;
VAL_ 1297 RCM_a074_eventFrontLeftSeatbelt 1 "LATCHED" 0 "UNLATCHED" ;
VAL_ 1297 RCM_a074_eventFrontRightSeatbelt 1 "LATCHED" 0 "UNLATCHED" ;
VAL_ 1297 RCM_a074_eventDriverBrakeApply 3 "Faulty_SNA" 2 "Driver_applying_brakes" 1 "Not_Applied" 0 "NotInit_orOff" ;
VAL_ 1297 RCM_a074_eventAccelPedalPos 255 "SNA" ;
VAL_ 1297 RCM_a075_eventArmStatus 1 "ARMED" 0 "UNARMED" ;
VAL_ 1297 RCM_a075_eventFactoryMode 1 "ENABLED" 0 "DISABLED" ;
VAL_ 1297 RCM_a075_eventDiagEnabled 1 "ENABLED" 0 "DISABLED" ;
VAL_ 1297 RCM_a075_eventDriveOrientation 1 "RIGHT_HAND_DRIVE" 0 "LEFT_HAND_DRIVE" ;
VAL_ 1297 RCM_a075_eventIDFsignal 1 "ACTIVE" 0 "NOT_ACTIVE" ;
VAL_ 1297 RCM_a075_eventFrontLeftSeatbelt 1 "LATCHED" 0 "UNLATCHED" ;
VAL_ 1297 RCM_a075_eventFrontRightSeatbelt 1 "LATCHED" 0 "UNLATCHED" ;
VAL_ 1297 RCM_a075_eventDriverBrakeApply 3 "Faulty_SNA" 2 "Driver_applying_brakes" 1 "Not_Applied" 0 "NotInit_orOff" ;
VAL_ 1297 RCM_a075_eventAccelPedalPos 255 "SNA" ;
VAL_ 1297 RCM_a078_eventArmStatus 1 "ARMED" 0 "UNARMED" ;
VAL_ 1297 RCM_a078_eventFactoryMode 1 "ENABLED" 0 "DISABLED" ;
VAL_ 1297 RCM_a078_eventDiagEnabled 1 "ENABLED" 0 "DISABLED" ;
VAL_ 1297 RCM_a078_eventDriveOrientation 1 "RIGHT_HAND_DRIVE" 0 "LEFT_HAND_DRIVE" ;
VAL_ 1297 RCM_a078_eventIDFsignal 1 "ACTIVE" 0 "NOT_ACTIVE" ;
VAL_ 1297 RCM_a078_eventFrontLeftSeatbelt 1 "LATCHED" 0 "UNLATCHED" ;
VAL_ 1297 RCM_a078_eventFrontRightSeatbelt 1 "LATCHED" 0 "UNLATCHED" ;
VAL_ 1297 RCM_a078_eventDriverBrakeApply 3 "Faulty_SNA" 2 "Driver_applying_brakes" 1 "Not_Applied" 0 "NotInit_orOff" ;
VAL_ 1297 RCM_a078_eventAccelPedalPos 255 "SNA" ;
VAL_ 1297 RCM_a079_eventArmStatus 1 "ARMED" 0 "UNARMED" ;
VAL_ 1297 RCM_a079_eventFactoryMode 1 "ENABLED" 0 "DISABLED" ;
VAL_ 1297 RCM_a079_eventDiagEnabled 1 "ENABLED" 0 "DISABLED" ;
VAL_ 1297 RCM_a079_eventDriveOrientation 1 "RIGHT_HAND_DRIVE" 0 "LEFT_HAND_DRIVE" ;
VAL_ 1297 RCM_a079_eventIDFsignal 1 "ACTIVE" 0 "NOT_ACTIVE" ;
VAL_ 1297 RCM_a079_eventFrontLeftSeatbelt 1 "LATCHED" 0 "UNLATCHED" ;
VAL_ 1297 RCM_a079_eventFrontRightSeatbelt 1 "LATCHED" 0 "UNLATCHED" ;
VAL_ 1297 RCM_a079_eventDriverBrakeApply 3 "Faulty_SNA" 2 "Driver_applying_brakes" 1 "Not_Applied" 0 "NotInit_orOff" ;
VAL_ 1297 RCM_a079_eventAccelPedalPos 255 "SNA" ;
VAL_ 1297 RCM_a080_eventArmStatus 1 "ARMED" 0 "UNARMED" ;
VAL_ 1297 RCM_a080_eventFactoryMode 1 "ENABLED" 0 "DISABLED" ;
VAL_ 1297 RCM_a080_eventDiagEnabled 1 "ENABLED" 0 "DISABLED" ;
VAL_ 1297 RCM_a080_eventDriveOrientation 1 "RIGHT_HAND_DRIVE" 0 "LEFT_HAND_DRIVE" ;
VAL_ 1297 RCM_a080_eventIDFsignal 1 "ACTIVE" 0 "NOT_ACTIVE" ;
VAL_ 1297 RCM_a080_eventFrontLeftSeatbelt 1 "LATCHED" 0 "UNLATCHED" ;
VAL_ 1297 RCM_a080_eventFrontRightSeatbelt 1 "LATCHED" 0 "UNLATCHED" ;
VAL_ 1297 RCM_a080_eventDriverBrakeApply 3 "Faulty_SNA" 2 "Driver_applying_brakes" 1 "Not_Applied" 0 "NotInit_orOff" ;
VAL_ 1297 RCM_a080_eventAccelPedalPos 255 "SNA" ;
VAL_ 1297 RCM_a083_eventArmStatus 1 "ARMED" 0 "UNARMED" ;
VAL_ 1297 RCM_a083_eventFactoryMode 1 "ENABLED" 0 "DISABLED" ;
VAL_ 1297 RCM_a083_eventDiagEnabled 1 "ENABLED" 0 "DISABLED" ;
VAL_ 1297 RCM_a083_eventDriveOrientation 1 "RIGHT_HAND_DRIVE" 0 "LEFT_HAND_DRIVE" ;
VAL_ 1297 RCM_a083_eventIDFsignal 1 "ACTIVE" 0 "NOT_ACTIVE" ;
VAL_ 1297 RCM_a083_eventFrontLeftSeatbelt 1 "LATCHED" 0 "UNLATCHED" ;
VAL_ 1297 RCM_a083_eventFrontRightSeatbelt 1 "LATCHED" 0 "UNLATCHED" ;
VAL_ 1297 RCM_a083_eventDriverBrakeApply 3 "Faulty_SNA" 2 "Driver_applying_brakes" 1 "Not_Applied" 0 "NotInit_orOff" ;
VAL_ 1297 RCM_a083_eventAccelPedalPos 255 "SNA" ;
VAL_ 1297 RCM_a087_eventArmStatus 1 "ARMED" 0 "UNARMED" ;
VAL_ 1297 RCM_a087_eventFactoryMode 1 "ENABLED" 0 "DISABLED" ;
VAL_ 1297 RCM_a087_eventDiagEnabled 1 "ENABLED" 0 "DISABLED" ;
VAL_ 1297 RCM_a087_eventDriveOrientation 1 "RIGHT_HAND_DRIVE" 0 "LEFT_HAND_DRIVE" ;
VAL_ 1297 RCM_a087_eventIDFsignal 1 "ACTIVE" 0 "NOT_ACTIVE" ;
VAL_ 1297 RCM_a087_eventFrontLeftSeatbelt 1 "LATCHED" 0 "UNLATCHED" ;
VAL_ 1297 RCM_a087_eventFrontRightSeatbelt 1 "LATCHED" 0 "UNLATCHED" ;
VAL_ 1297 RCM_a087_eventDriverBrakeApply 3 "Faulty_SNA" 2 "Driver_applying_brakes" 1 "Not_Applied" 0 "NotInit_orOff" ;
VAL_ 1297 RCM_a087_eventAccelPedalPos 255 "SNA" ;
VAL_ 1297 RCM_a088_eventArmStatus 1 "ARMED" 0 "UNARMED" ;
VAL_ 1297 RCM_a088_eventFactoryMode 1 "ENABLED" 0 "DISABLED" ;
VAL_ 1297 RCM_a088_eventDiagEnabled 1 "ENABLED" 0 "DISABLED" ;
VAL_ 1297 RCM_a088_eventDriveOrientation 1 "RIGHT_HAND_DRIVE" 0 "LEFT_HAND_DRIVE" ;
VAL_ 1297 RCM_a088_eventIDFsignal 1 "ACTIVE" 0 "NOT_ACTIVE" ;
VAL_ 1297 RCM_a088_eventFrontLeftSeatbelt 1 "LATCHED" 0 "UNLATCHED" ;
VAL_ 1297 RCM_a088_eventFrontRightSeatbelt 1 "LATCHED" 0 "UNLATCHED" ;
VAL_ 1297 RCM_a088_eventDriverBrakeApply 3 "Faulty_SNA" 2 "Driver_applying_brakes" 1 "Not_Applied" 0 "NotInit_orOff" ;
VAL_ 1297 RCM_a088_eventAccelPedalPos 255 "SNA" ;
VAL_ 1297 RCM_a089_eventArmStatus 1 "ARMED" 0 "UNARMED" ;
VAL_ 1297 RCM_a089_eventFactoryMode 1 "ENABLED" 0 "DISABLED" ;
VAL_ 1297 RCM_a089_eventDiagEnabled 1 "ENABLED" 0 "DISABLED" ;
VAL_ 1297 RCM_a089_eventDriveOrientation 1 "RIGHT_HAND_DRIVE" 0 "LEFT_HAND_DRIVE" ;
VAL_ 1297 RCM_a089_eventIDFsignal 1 "ACTIVE" 0 "NOT_ACTIVE" ;
VAL_ 1297 RCM_a089_eventFrontLeftSeatbelt 1 "LATCHED" 0 "UNLATCHED" ;
VAL_ 1297 RCM_a089_eventFrontRightSeatbelt 1 "LATCHED" 0 "UNLATCHED" ;
VAL_ 1297 RCM_a089_eventDriverBrakeApply 3 "Faulty_SNA" 2 "Driver_applying_brakes" 1 "Not_Applied" 0 "NotInit_orOff" ;
VAL_ 1297 RCM_a089_eventAccelPedalPos 255 "SNA" ;
VAL_ 1297 RCM_a090_eventArmStatus 1 "ARMED" 0 "UNARMED" ;
VAL_ 1297 RCM_a090_eventFactoryMode 1 "ENABLED" 0 "DISABLED" ;
VAL_ 1297 RCM_a090_eventDiagEnabled 1 "ENABLED" 0 "DISABLED" ;
VAL_ 1297 RCM_a090_eventDriveOrientation 1 "RIGHT_HAND_DRIVE" 0 "LEFT_HAND_DRIVE" ;
VAL_ 1297 RCM_a090_eventIDFsignal 1 "ACTIVE" 0 "NOT_ACTIVE" ;
VAL_ 1297 RCM_a090_eventFrontLeftSeatbelt 1 "LATCHED" 0 "UNLATCHED" ;
VAL_ 1297 RCM_a090_eventFrontRightSeatbelt 1 "LATCHED" 0 "UNLATCHED" ;
VAL_ 1297 RCM_a090_eventDriverBrakeApply 3 "Faulty_SNA" 2 "Driver_applying_brakes" 1 "Not_Applied" 0 "NotInit_orOff" ;
VAL_ 1297 RCM_a090_eventAccelPedalPos 255 "SNA" ;
VAL_ 1297 RCM_a092_eventArmStatus 1 "ARMED" 0 "UNARMED" ;
VAL_ 1297 RCM_a092_eventFactoryMode 1 "ENABLED" 0 "DISABLED" ;
VAL_ 1297 RCM_a092_eventDiagEnabled 1 "ENABLED" 0 "DISABLED" ;
VAL_ 1297 RCM_a092_eventDriveOrientation 1 "RIGHT_HAND_DRIVE" 0 "LEFT_HAND_DRIVE" ;
VAL_ 1297 RCM_a092_eventIDFsignal 1 "ACTIVE" 0 "NOT_ACTIVE" ;
VAL_ 1297 RCM_a092_eventFrontLeftSeatbelt 1 "LATCHED" 0 "UNLATCHED" ;
VAL_ 1297 RCM_a092_eventFrontRightSeatbelt 1 "LATCHED" 0 "UNLATCHED" ;
VAL_ 1297 RCM_a092_eventDriverBrakeApply 3 "Faulty_SNA" 2 "Driver_applying_brakes" 1 "Not_Applied" 0 "NotInit_orOff" ;
VAL_ 1297 RCM_a092_eventAccelPedalPos 255 "SNA" ;
VAL_ 1297 RCM_a093_eventArmStatus 1 "ARMED" 0 "UNARMED" ;
VAL_ 1297 RCM_a093_eventFactoryMode 1 "ENABLED" 0 "DISABLED" ;
VAL_ 1297 RCM_a093_eventDiagEnabled 1 "ENABLED" 0 "DISABLED" ;
VAL_ 1297 RCM_a093_eventDriveOrientation 1 "RIGHT_HAND_DRIVE" 0 "LEFT_HAND_DRIVE" ;
VAL_ 1297 RCM_a093_eventIDFsignal 1 "ACTIVE" 0 "NOT_ACTIVE" ;
VAL_ 1297 RCM_a093_eventFrontLeftSeatbelt 1 "LATCHED" 0 "UNLATCHED" ;
VAL_ 1297 RCM_a093_eventFrontRightSeatbelt 1 "LATCHED" 0 "UNLATCHED" ;
VAL_ 1297 RCM_a093_eventDriverBrakeApply 3 "Faulty_SNA" 2 "Driver_applying_brakes" 1 "Not_Applied" 0 "NotInit_orOff" ;
VAL_ 1297 RCM_a093_eventAccelPedalPos 255 "SNA" ;
VAL_ 1297 RCM_a094_eventArmStatus 1 "ARMED" 0 "UNARMED" ;
VAL_ 1297 RCM_a094_eventFactoryMode 1 "ENABLED" 0 "DISABLED" ;
VAL_ 1297 RCM_a094_eventDiagEnabled 1 "ENABLED" 0 "DISABLED" ;
VAL_ 1297 RCM_a094_eventDriveOrientation 1 "RIGHT_HAND_DRIVE" 0 "LEFT_HAND_DRIVE" ;
VAL_ 1297 RCM_a094_eventIDFsignal 1 "ACTIVE" 0 "NOT_ACTIVE" ;
VAL_ 1297 RCM_a094_eventFrontLeftSeatbelt 1 "LATCHED" 0 "UNLATCHED" ;
VAL_ 1297 RCM_a094_eventFrontRightSeatbelt 1 "LATCHED" 0 "UNLATCHED" ;
VAL_ 1297 RCM_a094_eventDriverBrakeApply 3 "Faulty_SNA" 2 "Driver_applying_brakes" 1 "Not_Applied" 0 "NotInit_orOff" ;
VAL_ 1297 RCM_a094_eventAccelPedalPos 255 "SNA" ;
VAL_ 1297 RCM_a101_eventArmStatus 1 "ARMED" 0 "UNARMED" ;
VAL_ 1297 RCM_a101_eventFactoryMode 1 "ENABLED" 0 "DISABLED" ;
VAL_ 1297 RCM_a101_eventDiagEnabled 1 "ENABLED" 0 "DISABLED" ;
VAL_ 1297 RCM_a101_eventDriveOrientation 1 "RIGHT_HAND_DRIVE" 0 "LEFT_HAND_DRIVE" ;
VAL_ 1297 RCM_a101_eventIDFsignal 1 "ACTIVE" 0 "NOT_ACTIVE" ;
VAL_ 1297 RCM_a101_eventFrontLeftSeatbelt 1 "LATCHED" 0 "UNLATCHED" ;
VAL_ 1297 RCM_a101_eventFrontRightSeatbelt 1 "LATCHED" 0 "UNLATCHED" ;
VAL_ 1297 RCM_a101_eventDriverBrakeApply 3 "Faulty_SNA" 2 "Driver_applying_brakes" 1 "Not_Applied" 0 "NotInit_orOff" ;
VAL_ 1297 RCM_a101_eventAccelPedalPos 255 "SNA" ;
VAL_ 1297 RCM_a102_eventArmStatus 1 "ARMED" 0 "UNARMED" ;
VAL_ 1297 RCM_a102_eventFactoryMode 1 "ENABLED" 0 "DISABLED" ;
VAL_ 1297 RCM_a102_eventDiagEnabled 1 "ENABLED" 0 "DISABLED" ;
VAL_ 1297 RCM_a102_eventDriveOrientation 1 "RIGHT_HAND_DRIVE" 0 "LEFT_HAND_DRIVE" ;
VAL_ 1297 RCM_a102_eventIDFsignal 1 "ACTIVE" 0 "NOT_ACTIVE" ;
VAL_ 1297 RCM_a102_eventFrontLeftSeatbelt 1 "LATCHED" 0 "UNLATCHED" ;
VAL_ 1297 RCM_a102_eventFrontRightSeatbelt 1 "LATCHED" 0 "UNLATCHED" ;
VAL_ 1297 RCM_a102_eventDriverBrakeApply 3 "Faulty_SNA" 2 "Driver_applying_brakes" 1 "Not_Applied" 0 "NotInit_orOff" ;
VAL_ 1297 RCM_a102_eventAccelPedalPos 255 "SNA" ;
VAL_ 1297 RCM_a103_eventArmStatus 1 "ARMED" 0 "UNARMED" ;
VAL_ 1297 RCM_a103_eventFactoryMode 1 "ENABLED" 0 "DISABLED" ;
VAL_ 1297 RCM_a103_eventDiagEnabled 1 "ENABLED" 0 "DISABLED" ;
VAL_ 1297 RCM_a103_eventDriveOrientation 1 "RIGHT_HAND_DRIVE" 0 "LEFT_HAND_DRIVE" ;
VAL_ 1297 RCM_a103_eventIDFsignal 1 "ACTIVE" 0 "NOT_ACTIVE" ;
VAL_ 1297 RCM_a103_eventFrontLeftSeatbelt 1 "LATCHED" 0 "UNLATCHED" ;
VAL_ 1297 RCM_a103_eventFrontRightSeatbelt 1 "LATCHED" 0 "UNLATCHED" ;
VAL_ 1297 RCM_a103_eventDriverBrakeApply 3 "Faulty_SNA" 2 "Driver_applying_brakes" 1 "Not_Applied" 0 "NotInit_orOff" ;
VAL_ 1297 RCM_a103_eventAccelPedalPos 255 "SNA" ;
VAL_ 1297 RCM_a104_eventArmStatus 1 "ARMED" 0 "UNARMED" ;
VAL_ 1297 RCM_a104_eventFactoryMode 1 "ENABLED" 0 "DISABLED" ;
VAL_ 1297 RCM_a104_eventDiagEnabled 1 "ENABLED" 0 "DISABLED" ;
VAL_ 1297 RCM_a104_eventDriveOrientation 1 "RIGHT_HAND_DRIVE" 0 "LEFT_HAND_DRIVE" ;
VAL_ 1297 RCM_a104_eventIDFsignal 1 "ACTIVE" 0 "NOT_ACTIVE" ;
VAL_ 1297 RCM_a104_eventFrontLeftSeatbelt 1 "LATCHED" 0 "UNLATCHED" ;
VAL_ 1297 RCM_a104_eventFrontRightSeatbelt 1 "LATCHED" 0 "UNLATCHED" ;
VAL_ 1297 RCM_a104_eventDriverBrakeApply 3 "Faulty_SNA" 2 "Driver_applying_brakes" 1 "Not_Applied" 0 "NotInit_orOff" ;
VAL_ 1297 RCM_a104_eventAccelPedalPos 255 "SNA" ;
VAL_ 1297 RCM_a105_eventArmStatus 1 "ARMED" 0 "UNARMED" ;
VAL_ 1297 RCM_a105_eventFactoryMode 1 "ENABLED" 0 "DISABLED" ;
VAL_ 1297 RCM_a105_eventDiagEnabled 1 "ENABLED" 0 "DISABLED" ;
VAL_ 1297 RCM_a105_eventDriveOrientation 1 "RIGHT_HAND_DRIVE" 0 "LEFT_HAND_DRIVE" ;
VAL_ 1297 RCM_a105_eventIDFsignal 1 "ACTIVE" 0 "NOT_ACTIVE" ;
VAL_ 1297 RCM_a105_eventFrontLeftSeatbelt 1 "LATCHED" 0 "UNLATCHED" ;
VAL_ 1297 RCM_a105_eventFrontRightSeatbelt 1 "LATCHED" 0 "UNLATCHED" ;
VAL_ 1297 RCM_a105_eventDriverBrakeApply 3 "Faulty_SNA" 2 "Driver_applying_brakes" 1 "Not_Applied" 0 "NotInit_orOff" ;
VAL_ 1297 RCM_a105_eventAccelPedalPos 255 "SNA" ;
VAL_ 1297 RCM_a106_eventArmStatus 1 "ARMED" 0 "UNARMED" ;
VAL_ 1297 RCM_a106_eventFactoryMode 1 "ENABLED" 0 "DISABLED" ;
VAL_ 1297 RCM_a106_eventDiagEnabled 1 "ENABLED" 0 "DISABLED" ;
VAL_ 1297 RCM_a106_eventDriveOrientation 1 "RIGHT_HAND_DRIVE" 0 "LEFT_HAND_DRIVE" ;
VAL_ 1297 RCM_a106_eventIDFsignal 1 "ACTIVE" 0 "NOT_ACTIVE" ;
VAL_ 1297 RCM_a106_eventFrontLeftSeatbelt 1 "LATCHED" 0 "UNLATCHED" ;
VAL_ 1297 RCM_a106_eventFrontRightSeatbelt 1 "LATCHED" 0 "UNLATCHED" ;
VAL_ 1297 RCM_a106_eventDriverBrakeApply 3 "Faulty_SNA" 2 "Driver_applying_brakes" 1 "Not_Applied" 0 "NotInit_orOff" ;
VAL_ 1297 RCM_a106_eventAccelPedalPos 255 "SNA" ;
VAL_ 1297 RCM_a107_eventArmStatus 1 "ARMED" 0 "UNARMED" ;
VAL_ 1297 RCM_a107_eventFactoryMode 1 "ENABLED" 0 "DISABLED" ;
VAL_ 1297 RCM_a107_eventDiagEnabled 1 "ENABLED" 0 "DISABLED" ;
VAL_ 1297 RCM_a107_eventDriveOrientation 1 "RIGHT_HAND_DRIVE" 0 "LEFT_HAND_DRIVE" ;
VAL_ 1297 RCM_a107_eventIDFsignal 1 "ACTIVE" 0 "NOT_ACTIVE" ;
VAL_ 1297 RCM_a107_eventFrontLeftSeatbelt 1 "LATCHED" 0 "UNLATCHED" ;
VAL_ 1297 RCM_a107_eventFrontRightSeatbelt 1 "LATCHED" 0 "UNLATCHED" ;
VAL_ 1297 RCM_a107_eventDriverBrakeApply 3 "Faulty_SNA" 2 "Driver_applying_brakes" 1 "Not_Applied" 0 "NotInit_orOff" ;
VAL_ 1297 RCM_a107_eventAccelPedalPos 255 "SNA" ;
VAL_ 1297 RCM_a108_eventArmStatus 1 "ARMED" 0 "UNARMED" ;
VAL_ 1297 RCM_a108_eventFactoryMode 1 "ENABLED" 0 "DISABLED" ;
VAL_ 1297 RCM_a108_eventDiagEnabled 1 "ENABLED" 0 "DISABLED" ;
VAL_ 1297 RCM_a108_eventDriveOrientation 1 "RIGHT_HAND_DRIVE" 0 "LEFT_HAND_DRIVE" ;
VAL_ 1297 RCM_a108_eventIDFsignal 1 "ACTIVE" 0 "NOT_ACTIVE" ;
VAL_ 1297 RCM_a108_eventFrontLeftSeatbelt 1 "LATCHED" 0 "UNLATCHED" ;
VAL_ 1297 RCM_a108_eventFrontRightSeatbelt 1 "LATCHED" 0 "UNLATCHED" ;
VAL_ 1297 RCM_a108_eventDriverBrakeApply 3 "Faulty_SNA" 2 "Driver_applying_brakes" 1 "Not_Applied" 0 "NotInit_orOff" ;
VAL_ 1297 RCM_a108_eventAccelPedalPos 255 "SNA" ;
VAL_ 1297 RCM_a109_eventArmStatus 1 "ARMED" 0 "UNARMED" ;
VAL_ 1297 RCM_a109_eventFactoryMode 1 "ENABLED" 0 "DISABLED" ;
VAL_ 1297 RCM_a109_eventDiagEnabled 1 "ENABLED" 0 "DISABLED" ;
VAL_ 1297 RCM_a109_eventDriveOrientation 1 "RIGHT_HAND_DRIVE" 0 "LEFT_HAND_DRIVE" ;
VAL_ 1297 RCM_a109_eventIDFsignal 1 "ACTIVE" 0 "NOT_ACTIVE" ;
VAL_ 1297 RCM_a109_eventFrontLeftSeatbelt 1 "LATCHED" 0 "UNLATCHED" ;
VAL_ 1297 RCM_a109_eventFrontRightSeatbelt 1 "LATCHED" 0 "UNLATCHED" ;
VAL_ 1297 RCM_a109_eventDriverBrakeApply 3 "Faulty_SNA" 2 "Driver_applying_brakes" 1 "Not_Applied" 0 "NotInit_orOff" ;
VAL_ 1297 RCM_a109_eventAccelPedalPos 255 "SNA" ;
VAL_ 1297 RCM_a110_eventArmStatus 1 "ARMED" 0 "UNARMED" ;
VAL_ 1297 RCM_a110_eventFactoryMode 1 "ENABLED" 0 "DISABLED" ;
VAL_ 1297 RCM_a110_eventDiagEnabled 1 "ENABLED" 0 "DISABLED" ;
VAL_ 1297 RCM_a110_eventDriveOrientation 1 "RIGHT_HAND_DRIVE" 0 "LEFT_HAND_DRIVE" ;
VAL_ 1297 RCM_a110_eventIDFsignal 1 "ACTIVE" 0 "NOT_ACTIVE" ;
VAL_ 1297 RCM_a110_eventFrontLeftSeatbelt 1 "LATCHED" 0 "UNLATCHED" ;
VAL_ 1297 RCM_a110_eventFrontRightSeatbelt 1 "LATCHED" 0 "UNLATCHED" ;
VAL_ 1297 RCM_a110_eventDriverBrakeApply 3 "Faulty_SNA" 2 "Driver_applying_brakes" 1 "Not_Applied" 0 "NotInit_orOff" ;
VAL_ 1297 RCM_a110_eventAccelPedalPos 255 "SNA" ;
VAL_ 1297 RCM_a112_eventArmStatus 1 "ARMED" 0 "UNARMED" ;
VAL_ 1297 RCM_a112_eventFactoryMode 1 "ENABLED" 0 "DISABLED" ;
VAL_ 1297 RCM_a112_eventDiagEnabled 1 "ENABLED" 0 "DISABLED" ;
VAL_ 1297 RCM_a112_eventDriveOrientation 1 "RIGHT_HAND_DRIVE" 0 "LEFT_HAND_DRIVE" ;
VAL_ 1297 RCM_a112_eventIDFsignal 1 "ACTIVE" 0 "NOT_ACTIVE" ;
VAL_ 1297 RCM_a112_eventFrontLeftSeatbelt 1 "LATCHED" 0 "UNLATCHED" ;
VAL_ 1297 RCM_a112_eventFrontRightSeatbelt 1 "LATCHED" 0 "UNLATCHED" ;
VAL_ 1297 RCM_a112_eventDriverBrakeApply 3 "Faulty_SNA" 2 "Driver_applying_brakes" 1 "Not_Applied" 0 "NotInit_orOff" ;
VAL_ 1297 RCM_a112_eventAccelPedalPos 255 "SNA" ;
VAL_ 1297 RCM_a113_eventArmStatus 1 "ARMED" 0 "UNARMED" ;
VAL_ 1297 RCM_a113_eventFactoryMode 1 "ENABLED" 0 "DISABLED" ;
VAL_ 1297 RCM_a113_eventDiagEnabled 1 "ENABLED" 0 "DISABLED" ;
VAL_ 1297 RCM_a113_eventDriveOrientation 1 "RIGHT_HAND_DRIVE" 0 "LEFT_HAND_DRIVE" ;
VAL_ 1297 RCM_a113_eventIDFsignal 1 "ACTIVE" 0 "NOT_ACTIVE" ;
VAL_ 1297 RCM_a113_eventFrontLeftSeatbelt 1 "LATCHED" 0 "UNLATCHED" ;
VAL_ 1297 RCM_a113_eventFrontRightSeatbelt 1 "LATCHED" 0 "UNLATCHED" ;
VAL_ 1297 RCM_a113_eventDriverBrakeApply 3 "Faulty_SNA" 2 "Driver_applying_brakes" 1 "Not_Applied" 0 "NotInit_orOff" ;
VAL_ 1297 RCM_a113_eventAccelPedalPos 255 "SNA" ;
VAL_ 1297 RCM_a114_eventArmStatus 1 "ARMED" 0 "UNARMED" ;
VAL_ 1297 RCM_a114_eventFactoryMode 1 "ENABLED" 0 "DISABLED" ;
VAL_ 1297 RCM_a114_eventDiagEnabled 1 "ENABLED" 0 "DISABLED" ;
VAL_ 1297 RCM_a114_eventDriveOrientation 1 "RIGHT_HAND_DRIVE" 0 "LEFT_HAND_DRIVE" ;
VAL_ 1297 RCM_a114_eventIDFsignal 1 "ACTIVE" 0 "NOT_ACTIVE" ;
VAL_ 1297 RCM_a114_eventFrontLeftSeatbelt 1 "LATCHED" 0 "UNLATCHED" ;
VAL_ 1297 RCM_a114_eventFrontRightSeatbelt 1 "LATCHED" 0 "UNLATCHED" ;
VAL_ 1297 RCM_a114_eventDriverBrakeApply 3 "Faulty_SNA" 2 "Driver_applying_brakes" 1 "Not_Applied" 0 "NotInit_orOff" ;
VAL_ 1297 RCM_a114_eventAccelPedalPos 255 "SNA" ;
VAL_ 1297 RCM_a115_eventArmStatus 1 "ARMED" 0 "UNARMED" ;
VAL_ 1297 RCM_a115_eventFactoryMode 1 "ENABLED" 0 "DISABLED" ;
VAL_ 1297 RCM_a115_eventDiagEnabled 1 "ENABLED" 0 "DISABLED" ;
VAL_ 1297 RCM_a115_eventDriveOrientation 1 "RIGHT_HAND_DRIVE" 0 "LEFT_HAND_DRIVE" ;
VAL_ 1297 RCM_a115_eventIDFsignal 1 "ACTIVE" 0 "NOT_ACTIVE" ;
VAL_ 1297 RCM_a115_eventFrontLeftSeatbelt 1 "LATCHED" 0 "UNLATCHED" ;
VAL_ 1297 RCM_a115_eventFrontRightSeatbelt 1 "LATCHED" 0 "UNLATCHED" ;
VAL_ 1297 RCM_a115_eventDriverBrakeApply 3 "Faulty_SNA" 2 "Driver_applying_brakes" 1 "Not_Applied" 0 "NotInit_orOff" ;
VAL_ 1297 RCM_a115_eventAccelPedalPos 255 "SNA" ;
VAL_ 1297 RCM_a116_eventArmStatus 1 "ARMED" 0 "UNARMED" ;
VAL_ 1297 RCM_a116_eventFactoryMode 1 "ENABLED" 0 "DISABLED" ;
VAL_ 1297 RCM_a116_eventDiagEnabled 1 "ENABLED" 0 "DISABLED" ;
VAL_ 1297 RCM_a116_eventDriveOrientation 1 "RIGHT_HAND_DRIVE" 0 "LEFT_HAND_DRIVE" ;
VAL_ 1297 RCM_a116_eventIDFsignal 1 "ACTIVE" 0 "NOT_ACTIVE" ;
VAL_ 1297 RCM_a116_eventFrontLeftSeatbelt 1 "LATCHED" 0 "UNLATCHED" ;
VAL_ 1297 RCM_a116_eventFrontRightSeatbelt 1 "LATCHED" 0 "UNLATCHED" ;
VAL_ 1297 RCM_a116_eventDriverBrakeApply 3 "Faulty_SNA" 2 "Driver_applying_brakes" 1 "Not_Applied" 0 "NotInit_orOff" ;
VAL_ 1297 RCM_a116_eventAccelPedalPos 255 "SNA" ;
VAL_ 1297 RCM_a117_eventArmStatus 1 "ARMED" 0 "UNARMED" ;
VAL_ 1297 RCM_a117_eventFactoryMode 1 "ENABLED" 0 "DISABLED" ;
VAL_ 1297 RCM_a117_eventDiagEnabled 1 "ENABLED" 0 "DISABLED" ;
VAL_ 1297 RCM_a117_eventDriveOrientation 1 "RIGHT_HAND_DRIVE" 0 "LEFT_HAND_DRIVE" ;
VAL_ 1297 RCM_a117_eventIDFsignal 1 "ACTIVE" 0 "NOT_ACTIVE" ;
VAL_ 1297 RCM_a117_eventFrontLeftSeatbelt 1 "LATCHED" 0 "UNLATCHED" ;
VAL_ 1297 RCM_a117_eventFrontRightSeatbelt 1 "LATCHED" 0 "UNLATCHED" ;
VAL_ 1297 RCM_a117_eventDriverBrakeApply 3 "Faulty_SNA" 2 "Driver_applying_brakes" 1 "Not_Applied" 0 "NotInit_orOff" ;
VAL_ 1297 RCM_a117_eventAccelPedalPos 255 "SNA" ;
VAL_ 1297 RCM_a118_eventArmStatus 1 "ARMED" 0 "UNARMED" ;
VAL_ 1297 RCM_a118_eventFactoryMode 1 "ENABLED" 0 "DISABLED" ;
VAL_ 1297 RCM_a118_eventDiagEnabled 1 "ENABLED" 0 "DISABLED" ;
VAL_ 1297 RCM_a118_eventDriveOrientation 1 "RIGHT_HAND_DRIVE" 0 "LEFT_HAND_DRIVE" ;
VAL_ 1297 RCM_a118_eventIDFsignal 1 "ACTIVE" 0 "NOT_ACTIVE" ;
VAL_ 1297 RCM_a118_eventFrontLeftSeatbelt 1 "LATCHED" 0 "UNLATCHED" ;
VAL_ 1297 RCM_a118_eventFrontRightSeatbelt 1 "LATCHED" 0 "UNLATCHED" ;
VAL_ 1297 RCM_a118_eventDriverBrakeApply 3 "Faulty_SNA" 2 "Driver_applying_brakes" 1 "Not_Applied" 0 "NotInit_orOff" ;
VAL_ 1297 RCM_a118_eventAccelPedalPos 255 "SNA" ;
VAL_ 881 RCM_matrixIndex 1 "AlertMatrix1" 0 "AlertMatrix0" ;
VAL_ 1471 RCU_alertID 66 "a066_ESPredundantBrakingStatusChecksum" 65 "a065_ESPredundantBrakingStatusCounter" 64 "a064_ESPredundantBrakingStatusDLC" 63 "a063_DIlocStatus2Checksum" 62 "a062_DIlocStatus2Counter" 61 "a061_DIlocStatus2DLC" 60 "a060_DASbrakeTorqueCommandInvalid" 59 "a059_DASredundantBrakingControlChecksum" 58 "a058_DASredundantBrakingControlCounter" 57 "a057_DASredundantBrakingControlDLC" 56 "a056_redundantControllerIsMaster" 55 "a055_IDBsimulatorPressFaulted" 54 "a054_IDBcircuitPressFaulted" 53 "a053_ESPwheelSpeedsChecksum" 52 "a052_ESPwheelSpeedsCounter" 51 "a051_ESPReRWSSLInvalid" 50 "a050_ESPReLWSSLInvalid" 49 "a049_ESPFrRWSSLInvalid" 48 "a048_ESPFrLWSSLInvalid" 47 "a047_ESPwheelSpeedsDLC" 46 "a046_brakeFluidLevelSNA" 45 "a045_VCFRONTtempInvalid" 44 "a044_VCFRONTsensorsMIA" 43 "a043_VCFRONTiBoosterLvStateInvalid" 42 "a042_DIsystemStatusChecksum" 41 "a041_DIsystemStatusCounter" 40 "a040_DIgearInvalid" 39 "a039_DIaccelPosInvalid" 38 "a038_DIsystemStatusDLC" 37 "a037_IDBinputRodStrokeInvalid" 36 "a036_IDBpspInvalid" 35 "a035_IDBpcpInvalid" 34 "a034_VCFRONTLVPowerStateCounter" 33 "a033_VCFRONTLVPowerStateChecksum" 32 "a032_VCFRONTLVPowerStateDLC" 31 "a031_PMstate2Counter" 30 "a030_PMstate2Checksum" 29 "a029_PMstate2DLC" 28 "a028_DIchassisControlCounter" 27 "a027_DIchassisCtrlChecksum" 26 "a026_DIchassisControlDLC" 25 "a025_IDBstatusCounter" 24 "a024_IDBstatusChecksum" 23 "a023_IDBstatusDLC" 22 "a022_BBstatusCounter" 21 "a021_BBstatusChecksum" 20 "a020_BBstatusDLC" 19 "a019_DItorquePathActive" 18 "a018_DItorquePathFaulted" 17 "a017_chassisBusOff" 16 "a016_partyBusOff" 15 "a015_fluidLeakDetected" 14 "a014_asicTempHigh" 13 "a013_mcuGenericFault" 12 "a012_pedalSensorNotCal" 11 "a011_idbPedalTravelMismatch" 10 "a010_pedalSensorFault" 9 "a009_brakeFluidLow" 8 "a008_pressureNotCalibrated" 7 "a007_pressureSensorFault" 6 "a006_wakeLineOpen" 5 "a005_supplyUndervoltage" 4 "a004_supplyOvervoltage" 3 "a003_pumpMotorFault" 2 "a002_solenoidValveFault" 1 "a001_valveDriverFault" 0 "ALERT_DO_NOT_USE_ZERO" ;
VAL_ 1471 RCU_alertState 1 "SET" 0 "CLEARED" ;
VAL_ 1471 RCU_a010_sensorPowerSupply 1 "NOT_OK" 0 "OK" ;
VAL_ 1471 RCU_a010_sensorHardware 1 "NOT_OK" 0 "OK" ;
VAL_ 1471 RCU_a010_sensorSignal 1 "NOT_OK" 0 "OK" ;
VAL_ 1471 RCU_a023_validityOnChassisBus 1 "NOT_OK" 0 "OK" ;
VAL_ 1471 RCU_a023_validityOnPartyBus 1 "NOT_OK" 0 "OK" ;
VAL_ 1471 RCU_a024_validityOnChassisBus 1 "NOT_OK" 0 "OK" ;
VAL_ 1471 RCU_a024_validityOnPartyBus 1 "NOT_OK" 0 "OK" ;
VAL_ 1471 RCU_a025_validityOnChassisBus 1 "NOT_OK" 0 "OK" ;
VAL_ 1471 RCU_a025_validityOnPartyBus 1 "NOT_OK" 0 "OK" ;
VAL_ 1471 RCU_a035_validityOnChassisBus 1 "NOT_OK" 0 "OK" ;
VAL_ 1471 RCU_a035_validityOnPartyBus 1 "NOT_OK" 0 "OK" ;
VAL_ 1471 RCU_a036_validityOnChassisBus 1 "NOT_OK" 0 "OK" ;
VAL_ 1471 RCU_a036_validityOnPartyBus 1 "NOT_OK" 0 "OK" ;
VAL_ 998 RCU_matrixIndex 1 "AlertMatrix1" 0 "AlertMatrix0" ;
VAL_ 831 RCU_infoIndex 255 "END" 31 "SUBCOMPONENT_GITHASH" 30 "PACKAGE_SN_8_14" 29 "PACKAGE_SN_1_7" 27 "PACKAGE_PN_15_20" 26 "PACKAGE_PN_8_14" 25 "PACKAGE_PN_1_7" 23 "SUBCOMPONENT2" 22 "VARIANTCRC" 20 "UDS_PROTOCOL_BOOTCRC" 19 "VERSION_DEPRECATED" 18 "BOOTLOADER_GITHASH" 17 "APP_GITHASH" 16 "SUBCOMPONENT" 15 "BOOTLOADER_CRC" 14 "BOOTLOADER_SVN" 13 "APP_CRC" 11 "PCBAID_ASSYID_USAGEID" 10 "BUILD_HWID_COMPONENTID" 9 "DEPRECATED_9" 8 "DEPRECATED_8" 7 "DEPRECATED_7" 6 "DEPRECATED_6" 5 "DEPRECATED_5" 4 "DEPRECATED_4" 3 "DEPRECATED_3" 2 "DEPRECATED_2" 1 "DEPRECATED_1" 0 "DEPRECATED_0" ;
VAL_ 1415 TCU2_tc10Version 2 "TCU_tc10Version_FINAL_1_0" 1 "TCU_tc10Version_DRAFT" 0 "SNA" ;
VAL_ 1413 TCU2_alertID 16 "w016_IMEIMismatch" 15 "w015_NPNSubscriptionActive" 14 "w014_HostapdCrash" 13 "w013_UplinkQueueFull" 12 "w012_UplinkDegraded" 11 "w011_CellDumpDetected" 10 "w010_WifiDumpDetected" 9 "w009_WifiFirmwareCrash" 8 "w008_KernelPanic" 7 "w007_ModemUnreachable" 6 "w006_MpssUnavailable" 5 "w005_SIMSlotError" 4 "w004_MSDTransmissionFailed" 3 "w003_ECallFailed" 2 "w002_CellRegRejected" 1 "w001_IMSRegistrationFailed" 0 "ALERT_DO_NOT_USE_ZERO" ;
VAL_ 1413 TCU2_alertState 1 "SET" 0 "CLEARED" ;
VAL_ 1413 TCU2_w012_DataRAT 6 "NR5G_UNKNOWN" 5 "NR5G_SA" 4 "NR5G_NSA" 3 "LTE" 2 "WCDMA" 1 "GSM" 0 "UNKNOWN" ;
VAL_ 1413 TCU2_w012_NSAAvailable 2 "NOT_AVAILABLE" 1 "AVAILABLE" 0 "UNKNOWN" ;
VAL_ 1413 TCU2_w013_DataRAT 6 "NR5G_UNKNOWN" 5 "NR5G_SA" 4 "NR5G_NSA" 3 "LTE" 2 "WCDMA" 1 "GSM" 0 "UNKNOWN" ;
VAL_ 1413 TCU2_w013_NSAAvailable 2 "NOT_AVAILABLE" 1 "AVAILABLE" 0 "UNKNOWN" ;
VAL_ 1412 TCU2_logMux 30 "wakeSource" 29 "mdmBand" 28 "checkInternetFailCount" 27 "tcuSMState" 26 "cellularSMState" 25 "mdmDataCallTermCode" 24 "mdmDataCallTermReason" 23 "mdmTxKiloBytes" 22 "mdmMcc" 21 "mdmMnc" 20 "mdmPCIID" 19 "mdmNSAAvailable" 18 "mdmDataCallStatus" 17 "mdmDataRat" 16 "modemUptime" 15 "mdmBusyActive" 14 "mdmSIMStatus" 13 "mdmIMSStatus" 12 "mdmServiceState" 11 "mdmUplinkAvgRate" 10 "mdmUplinkAllowedRate" 9 "mdmSINR" 8 "mdmRSRP" 7 "mdmUplinkQueueSize" 6 "totalResumes" 5 "pwmcap" 4 "pwm" 3 "availableMemory" 2 "mdmCoreTemperature" 1 "cpuUsage" 0 "cpuTemp" ;
VAL_ 1412 TCU2_mdmBusyActive 4294967295 "SNA" ;
VAL_ 1412 TCU2_mdmDataRat 6 "RAT_NR5G_UNKNOWN" 5 "RAT_NR5G_SA" 4 "RAT_NR5G_NSA" 3 "RAT_LTE" 2 "RAT_WCDMA" 1 "RAT_GSM" 0 "RAT_UNKNOWN" ;
VAL_ 1412 TCU2_mdmDataCallStatus 4 "DISCONNECTED" 3 "DISCONNECTING" 2 "CONNECTED" 1 "CONNECTING" 0 "UNKNOWN" ;
VAL_ 1412 TCU2_mdmNSAAvailable 2 "NSA_NOT_AVAILABLE" 1 "NSA_AVAILABLE" 0 "NSA_UNKNOWN" ;
VAL_ 1412 TCU2_cellularSMState 7 "RECOVERING" 6 "LINK_CONNECTED" 5 "CHECKING_INTERNET" 4 "DATA_CONNECTED" 3 "IN_SERVICE" 2 "OUT_OF_SERVICE" 1 "WAITING_COMPONENT" 0 "UNKNOWN" ;
VAL_ 1412 TCU2_tcuSMState 7 "UPDATING" 6 "RESUMING" 5 "SUSPENDED" 4 "PREPARING_SLEEP" 3 "POWER_CYCLING" 2 "IN_OPERATION" 1 "SEARCHING_COMPONENT" 0 "UNKNOWN" ;
VAL_ 1412 TCU2_wakeSource 3 "ETHERNET" 2 "WOIP" 1 "SMS" 0 "NONE" ;
VAL_ 1159 TCU_tc10Version 2 "TCU_tc10Version_FINAL_1_0" 1 "TCU_tc10Version_DRAFT" 0 "SNA" ;
VAL_ 1157 TCU_alertID 16 "w016_IMEIMismatch" 15 "w015_NPNSubscriptionActive" 14 "w014_HostapdCrash" 13 "w013_UplinkQueueFull" 12 "w012_UplinkDegraded" 11 "w011_CellDumpDetected" 10 "w010_WifiDumpDetected" 9 "w009_WifiFirmwareCrash" 8 "w008_KernelPanic" 7 "w007_ModemUnreachable" 6 "w006_MpssUnavailable" 5 "w005_SIMSlotError" 4 "w004_MSDTransmissionFailed" 3 "w003_ECallFailed" 2 "w002_CellRegRejected" 1 "w001_IMSRegistrationFailed" 0 "ALERT_DO_NOT_USE_ZERO" ;
VAL_ 1157 TCU_alertState 1 "SET" 0 "CLEARED" ;
VAL_ 1157 TCU_w012_DataRAT 6 "NR5G_UNKNOWN" 5 "NR5G_SA" 4 "NR5G_NSA" 3 "LTE" 2 "WCDMA" 1 "GSM" 0 "UNKNOWN" ;
VAL_ 1157 TCU_w012_NSAAvailable 2 "NOT_AVAILABLE" 1 "AVAILABLE" 0 "UNKNOWN" ;
VAL_ 1157 TCU_w013_DataRAT 6 "NR5G_UNKNOWN" 5 "NR5G_SA" 4 "NR5G_NSA" 3 "LTE" 2 "WCDMA" 1 "GSM" 0 "UNKNOWN" ;
VAL_ 1157 TCU_w013_NSAAvailable 2 "NOT_AVAILABLE" 1 "AVAILABLE" 0 "UNKNOWN" ;
VAL_ 1155 TCU_logMux 30 "wakeSource" 29 "mdmBand" 28 "checkInternetFailCount" 27 "tcuSMState" 26 "cellularSMState" 25 "mdmDataCallTermCode" 24 "mdmDataCallTermReason" 23 "mdmTxKiloBytes" 22 "mdmMcc" 21 "mdmMnc" 20 "mdmPCIID" 19 "mdmNSAAvailable" 18 "mdmDataCallStatus" 17 "mdmDataRat" 16 "modemUptime" 15 "mdmBusyActive" 14 "mdmSIMStatus" 13 "mdmIMSStatus" 12 "mdmServiceState" 11 "mdmUplinkAvgRate" 10 "mdmUplinkAllowedRate" 9 "mdmSINR" 8 "mdmRSRP" 7 "mdmUplinkQueueSize" 6 "totalResumes" 5 "pwmcap" 4 "pwm" 3 "availableMemory" 2 "mdmCoreTemperature" 1 "cpuUsage" 0 "cpuTemp" ;
VAL_ 1155 TCU_mdmBusyActive 4294967295 "SNA" ;
VAL_ 1155 TCU_mdmDataRat 6 "RAT_NR5G_UNKNOWN" 5 "RAT_NR5G_SA" 4 "RAT_NR5G_NSA" 3 "RAT_LTE" 2 "RAT_WCDMA" 1 "RAT_GSM" 0 "RAT_UNKNOWN" ;
VAL_ 1155 TCU_mdmDataCallStatus 4 "DISCONNECTED" 3 "DISCONNECTING" 2 "CONNECTED" 1 "CONNECTING" 0 "UNKNOWN" ;
VAL_ 1155 TCU_mdmNSAAvailable 2 "NSA_NOT_AVAILABLE" 1 "NSA_AVAILABLE" 0 "NSA_UNKNOWN" ;
VAL_ 1155 TCU_cellularSMState 7 "RECOVERING" 6 "LINK_CONNECTED" 5 "CHECKING_INTERNET" 4 "DATA_CONNECTED" 3 "IN_SERVICE" 2 "OUT_OF_SERVICE" 1 "WAITING_COMPONENT" 0 "UNKNOWN" ;
VAL_ 1155 TCU_tcuSMState 7 "UPDATING" 6 "RESUMING" 5 "SUSPENDED" 4 "PREPARING_SLEEP" 3 "POWER_CYCLING" 2 "IN_OPERATION" 1 "SEARCHING_COMPONENT" 0 "UNKNOWN" ;
VAL_ 1155 TCU_wakeSource 3 "ETHERNET" 2 "WOIP" 1 "SMS" 0 "NONE" ;
